VERSION "DNNBNNNYNNNNNNNNNNNNNNNNNNNNNNNNNNNNNNNNNN/4/%%%/4/'%**4NNN///"

NS_ :

BS_:

BU_: Vector__XXX Verdeck TSG_Fahrer TSG_Beifahrer Standheizung SMLS SitzMemo_Fahrer SitzMemo_Beifahrer Reifendruck_VW Reifendruck_Audi PTC_Heizung Multifunktions_SG Komfort_SG Gateway_K FHSG_hinten_rechts FHSG_hinten_links Einparkhilfe Clima BSG Anhaenger_SG

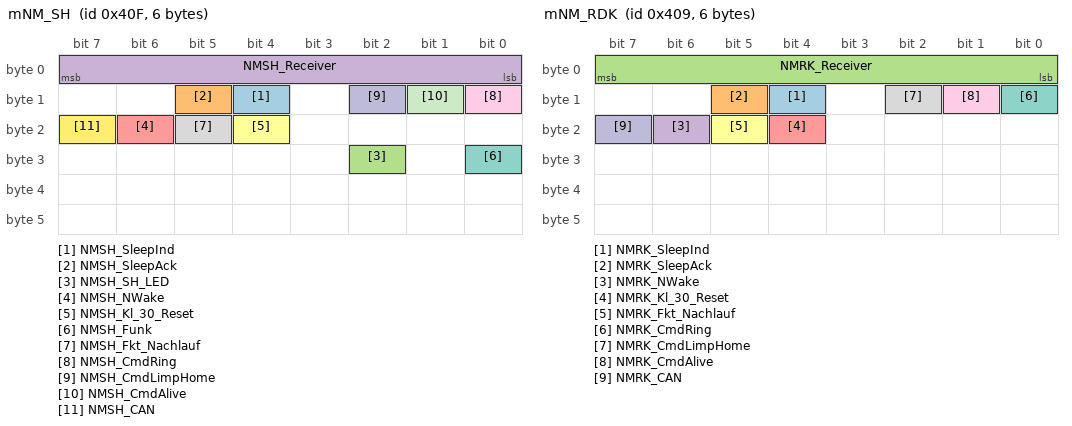
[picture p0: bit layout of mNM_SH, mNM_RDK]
BO_ 1039 mNM_SH: 6 Standheizung
 SG_ NMSH_SleepInd : 12|1@1+ (1,0) [0|0] ""  Reifendruck_VW,Reifendruck_Audi,Multifunktions_SG,SMLS,SitzMemo_Beifahrer,SitzMemo_Fahrer,Einparkhilfe,Verdeck,PTC_Heizung,Standheizung,Clima,Anhaenger_SG,BSG,FHSG_hinten_rechts,FHSG_hinten_links,TSG_Beifahrer,TSG_Fahrer,Komfort_SG,Gateway_K
 SG_ NMSH_SleepAck : 13|1@1+ (1,0) [0|0] ""  Reifendruck_VW,Reifendruck_Audi,Multifunktions_SG,SMLS,SitzMemo_Beifahrer,SitzMemo_Fahrer,Einparkhilfe,Verdeck,PTC_Heizung,Standheizung,Clima,Anhaenger_SG,BSG,FHSG_hinten_rechts,FHSG_hinten_links,TSG_Beifahrer,TSG_Fahrer,Komfort_SG,Gateway_K
 SG_ NMSH_SH_LED : 26|1@1+ (1,0) [0|0] ""  Standheizung
 SG_ NMSH_Receiver : 0|8@1+ (1,0) [0|0] ""  Reifendruck_VW,Reifendruck_Audi,Multifunktions_SG,SMLS,SitzMemo_Beifahrer,SitzMemo_Fahrer,Einparkhilfe,Verdeck,PTC_Heizung,Standheizung,Clima,Anhaenger_SG,BSG,FHSG_hinten_rechts,FHSG_hinten_links,TSG_Beifahrer,TSG_Fahrer,Komfort_SG,Gateway_K
 SG_ NMSH_NWake : 22|1@1+ (1,0) [0|0] ""  Standheizung
 SG_ NMSH_Kl_30_Reset : 20|1@1+ (1,0) [0|0] ""  Standheizung
 SG_ NMSH_Funk : 24|1@1+ (1,0) [0|0] ""  Standheizung
 SG_ NMSH_Fkt_Nachlauf : 21|1@1+ (1,0) [0|0] ""  Standheizung
 SG_ NMSH_CmdRing : 8|1@1+ (1,0) [0|0] ""  Reifendruck_VW,Reifendruck_Audi,Multifunktions_SG,SMLS,SitzMemo_Beifahrer,SitzMemo_Fahrer,Einparkhilfe,Verdeck,PTC_Heizung,Standheizung,Clima,Anhaenger_SG,BSG,FHSG_hinten_rechts,FHSG_hinten_links,TSG_Beifahrer,TSG_Fahrer,Komfort_SG,Gateway_K
 SG_ NMSH_CmdLimpHome : 10|1@1+ (1,0) [0|0] ""  Reifendruck_VW,Reifendruck_Audi,Multifunktions_SG,SMLS,SitzMemo_Beifahrer,SitzMemo_Fahrer,Einparkhilfe,Verdeck,PTC_Heizung,Standheizung,Clima,Anhaenger_SG,BSG,FHSG_hinten_rechts,FHSG_hinten_links,TSG_Beifahrer,TSG_Fahrer,Komfort_SG,Gateway_K
 SG_ NMSH_CmdAlive : 9|1@1+ (1,0) [0|0] ""  Reifendruck_VW,Reifendruck_Audi,Multifunktions_SG,SMLS,SitzMemo_Beifahrer,SitzMemo_Fahrer,Einparkhilfe,Verdeck,PTC_Heizung,Standheizung,Clima,Anhaenger_SG,BSG,FHSG_hinten_rechts,FHSG_hinten_links,TSG_Beifahrer,TSG_Fahrer,Komfort_SG,Gateway_K
 SG_ NMSH_CAN : 23|1@1+ (1,0) [0|0] ""  Standheizung

BO_ 1033 mNM_RDK: 6 Reifendruck_Audi
 SG_ NMRK_SleepInd : 12|1@1+ (1,0) [0|0] ""  Reifendruck_VW,Reifendruck_Audi,Multifunktions_SG,SMLS,SitzMemo_Beifahrer,SitzMemo_Fahrer,Einparkhilfe,Verdeck,PTC_Heizung,Standheizung,Clima,Anhaenger_SG,BSG,FHSG_hinten_rechts,FHSG_hinten_links,TSG_Beifahrer,TSG_Fahrer,Komfort_SG,Gateway_K
 SG_ NMRK_SleepAck : 13|1@1+ (1,0) [0|0] ""  Reifendruck_VW,Reifendruck_Audi,Multifunktions_SG,SMLS,SitzMemo_Beifahrer,SitzMemo_Fahrer,Einparkhilfe,Verdeck,PTC_Heizung,Standheizung,Clima,Anhaenger_SG,BSG,FHSG_hinten_rechts,FHSG_hinten_links,TSG_Beifahrer,TSG_Fahrer,Komfort_SG,Gateway_K
 SG_ NMRK_Receiver : 0|8@1+ (1,0) [0|0] ""  Reifendruck_VW,Reifendruck_Audi,Multifunktions_SG,SMLS,SitzMemo_Beifahrer,SitzMemo_Fahrer,Einparkhilfe,Verdeck,PTC_Heizung,Standheizung,Clima,Anhaenger_SG,BSG,FHSG_hinten_rechts,FHSG_hinten_links,TSG_Beifahrer,TSG_Fahrer,Komfort_SG,Gateway_K
 SG_ NMRK_NWake : 22|1@1+ (1,0) [0|0] ""  Reifendruck_VW,Reifendruck_Audi
 SG_ NMRK_Kl_30_Reset : 20|1@1+ (1,0) [0|0] ""  Reifendruck_VW,Reifendruck_Audi
 SG_ NMRK_Fkt_Nachlauf : 21|1@1+ (1,0) [0|0] ""  Reifendruck_VW,Reifendruck_Audi
 SG_ NMRK_CmdRing : 8|1@1+ (1,0) [0|0] ""  Reifendruck_VW,Reifendruck_Audi,Multifunktions_SG,SMLS,SitzMemo_Beifahrer,SitzMemo_Fahrer,Einparkhilfe,Verdeck,PTC_Heizung,Standheizung,Clima,Anhaenger_SG,BSG,FHSG_hinten_rechts,FHSG_hinten_links,TSG_Beifahrer,TSG_Fahrer,Komfort_SG,Gateway_K
 SG_ NMRK_CmdLimpHome : 10|1@1+ (1,0) [0|0] ""  Reifendruck_VW,Reifendruck_Audi,Multifunktions_SG,SMLS,SitzMemo_Beifahrer,SitzMemo_Fahrer,Einparkhilfe,Verdeck,PTC_Heizung,Standheizung,Clima,Anhaenger_SG,BSG,FHSG_hinten_rechts,FHSG_hinten_links,TSG_Beifahrer,TSG_Fahrer,Komfort_SG,Gateway_K
 SG_ NMRK_CmdAlive : 9|1@1+ (1,0) [0|0] ""  Reifendruck_VW,Reifendruck_Audi,Multifunktions_SG,SMLS,SitzMemo_Beifahrer,SitzMemo_Fahrer,Einparkhilfe,Verdeck,PTC_Heizung,Standheizung,Clima,Anhaenger_SG,BSG,FHSG_hinten_rechts,FHSG_hinten_links,TSG_Beifahrer,TSG_Fahrer,Komfort_SG,Gateway_K
 SG_ NMRK_CAN : 23|1@1+ (1,0) [0|0] ""  Reifendruck_VW,Reifendruck_Audi

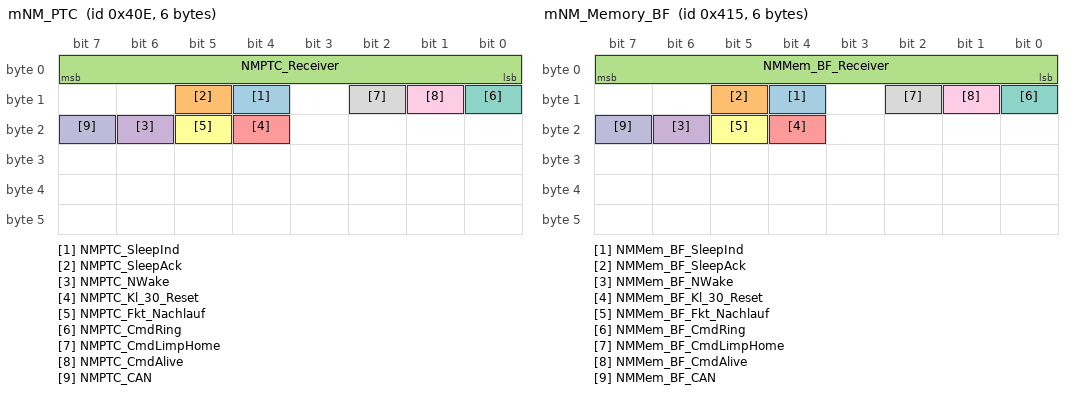
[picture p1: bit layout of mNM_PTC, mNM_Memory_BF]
BO_ 1038 mNM_PTC: 6 PTC_Heizung
 SG_ NMPTC_SleepInd : 12|1@1+ (1,0) [0|0] ""  Reifendruck_VW,Reifendruck_Audi,Multifunktions_SG,SMLS,SitzMemo_Beifahrer,SitzMemo_Fahrer,Einparkhilfe,Verdeck,PTC_Heizung,Standheizung,Clima,Anhaenger_SG,BSG,FHSG_hinten_rechts,FHSG_hinten_links,TSG_Beifahrer,TSG_Fahrer,Komfort_SG,Gateway_K
 SG_ NMPTC_SleepAck : 13|1@1+ (1,0) [0|0] ""  Reifendruck_VW,Reifendruck_Audi,Multifunktions_SG,SMLS,SitzMemo_Beifahrer,SitzMemo_Fahrer,Einparkhilfe,Verdeck,PTC_Heizung,Standheizung,Clima,Anhaenger_SG,BSG,FHSG_hinten_rechts,FHSG_hinten_links,TSG_Beifahrer,TSG_Fahrer,Komfort_SG,Gateway_K
 SG_ NMPTC_Receiver : 0|8@1+ (1,0) [0|0] ""  Reifendruck_VW,Reifendruck_Audi,Multifunktions_SG,SMLS,SitzMemo_Beifahrer,SitzMemo_Fahrer,Einparkhilfe,Verdeck,PTC_Heizung,Standheizung,Clima,Anhaenger_SG,BSG,FHSG_hinten_rechts,FHSG_hinten_links,TSG_Beifahrer,TSG_Fahrer,Komfort_SG,Gateway_K
 SG_ NMPTC_NWake : 22|1@1+ (1,0) [0|0] ""  Reifendruck_VW,Reifendruck_Audi,Gateway_K
 SG_ NMPTC_Kl_30_Reset : 20|1@1+ (1,0) [0|0] ""  Reifendruck_VW,Reifendruck_Audi,Gateway_K
 SG_ NMPTC_Fkt_Nachlauf : 21|1@1+ (1,0) [0|0] ""  Reifendruck_VW,Reifendruck_Audi,Gateway_K
 SG_ NMPTC_CmdRing : 8|1@1+ (1,0) [0|0] ""  Reifendruck_VW,Reifendruck_Audi,Multifunktions_SG,SMLS,SitzMemo_Beifahrer,SitzMemo_Fahrer,Einparkhilfe,Verdeck,PTC_Heizung,Standheizung,Clima,Anhaenger_SG,BSG,FHSG_hinten_rechts,FHSG_hinten_links,TSG_Beifahrer,TSG_Fahrer,Komfort_SG,Gateway_K
 SG_ NMPTC_CmdLimpHome : 10|1@1+ (1,0) [0|0] ""  Reifendruck_VW,Reifendruck_Audi,Multifunktions_SG,SMLS,SitzMemo_Beifahrer,SitzMemo_Fahrer,Einparkhilfe,Verdeck,PTC_Heizung,Standheizung,Clima,Anhaenger_SG,BSG,FHSG_hinten_rechts,FHSG_hinten_links,TSG_Beifahrer,TSG_Fahrer,Komfort_SG,Gateway_K
 SG_ NMPTC_CmdAlive : 9|1@1+ (1,0) [0|0] ""  Reifendruck_VW,Reifendruck_Audi,Multifunktions_SG,SMLS,SitzMemo_Beifahrer,SitzMemo_Fahrer,Einparkhilfe,Verdeck,PTC_Heizung,Standheizung,Clima,Anhaenger_SG,BSG,FHSG_hinten_rechts,FHSG_hinten_links,TSG_Beifahrer,TSG_Fahrer,Komfort_SG,Gateway_K
 SG_ NMPTC_CAN : 23|1@1+ (1,0) [0|0] ""  Reifendruck_VW,Reifendruck_Audi,Gateway_K

BO_ 1050 mNM_MFG: 6 Multifunktions_SG
 SG_ NMMFG_Warnblinker : 26|1@1+ (1,0) [0|0] ""  Multifunktions_SG
 SG_ NMMFG_Standlicht : 25|1@1+ (1,0) [0|0] ""  Multifunktions_SG
 SG_ NMMFG_SleepInd : 12|1@1+ (1,0) [0|0] ""  Reifendruck_VW,Reifendruck_Audi,Multifunktions_SG,SMLS,SitzMemo_Beifahrer,SitzMemo_Fahrer,Einparkhilfe,Verdeck,PTC_Heizung,Standheizung,Clima,Anhaenger_SG,BSG,FHSG_hinten_rechts,FHSG_hinten_links,TSG_Beifahrer,TSG_Fahrer,Komfort_SG,Gateway_K
 SG_ NMMFG_SleepAck : 13|1@1+ (1,0) [0|0] ""  Reifendruck_VW,Reifendruck_Audi,Multifunktions_SG,SMLS,SitzMemo_Beifahrer,SitzMemo_Fahrer,Einparkhilfe,Verdeck,PTC_Heizung,Standheizung,Clima,Anhaenger_SG,BSG,FHSG_hinten_rechts,FHSG_hinten_links,TSG_Beifahrer,TSG_Fahrer,Komfort_SG,Gateway_K
 SG_ NMMFG_Receiver : 0|8@1+ (1,0) [0|0] ""  Reifendruck_VW,Reifendruck_Audi,Multifunktions_SG,SMLS,SitzMemo_Beifahrer,SitzMemo_Fahrer,Einparkhilfe,Verdeck,PTC_Heizung,Standheizung,Clima,Anhaenger_SG,BSG,FHSG_hinten_rechts,FHSG_hinten_links,TSG_Beifahrer,TSG_Fahrer,Komfort_SG,Gateway_K
 SG_ NMMFG_re_Parklicht : 31|1@1+ (1,0) [0|0] ""  Multifunktions_SG
 SG_ NMMFG_NWake : 22|1@1+ (1,0) [0|0] ""  Multifunktions_SG
 SG_ NMMFG_Lichthupe : 29|1@1+ (1,0) [0|0] ""  Multifunktions_SG
 SG_ NMMFG_li_Parklicht : 30|1@1+ (1,0) [0|0] ""  Multifunktions_SG
 SG_ NMMFG_Kl_30_Reset : 20|1@1+ (1,0) [0|0] ""  Multifunktions_SG
 SG_ NMMFG_Fkt_Nachlauf : 21|1@1+ (1,0) [0|0] ""  Multifunktions_SG
 SG_ NMMFG_Fernbedienung : 24|1@1+ (1,0) [0|0] ""  Multifunktions_SG
 SG_ NMMFG_Fanfare : 32|1@1+ (1,0) [0|0] ""  Multifunktions_SG
 SG_ NMMFG_CmdRing : 8|1@1+ (1,0) [0|0] ""  Reifendruck_VW,Reifendruck_Audi,Multifunktions_SG,SMLS,SitzMemo_Beifahrer,SitzMemo_Fahrer,Einparkhilfe,Verdeck,PTC_Heizung,Standheizung,Clima,Anhaenger_SG,BSG,FHSG_hinten_rechts,FHSG_hinten_links,TSG_Beifahrer,TSG_Fahrer,Komfort_SG,Gateway_K
 SG_ NMMFG_CmdLimpHome : 10|1@1+ (1,0) [0|0] ""  Reifendruck_VW,Reifendruck_Audi,Multifunktions_SG,SMLS,SitzMemo_Beifahrer,SitzMemo_Fahrer,Einparkhilfe,Verdeck,PTC_Heizung,Standheizung,Clima,Anhaenger_SG,BSG,FHSG_hinten_rechts,FHSG_hinten_links,TSG_Beifahrer,TSG_Fahrer,Komfort_SG,Gateway_K
 SG_ NMMFG_CmdAlive : 9|1@1+ (1,0) [0|0] ""  Reifendruck_VW,Reifendruck_Audi,Multifunktions_SG,SMLS,SitzMemo_Beifahrer,SitzMemo_Fahrer,Einparkhilfe,Verdeck,PTC_Heizung,Standheizung,Clima,Anhaenger_SG,BSG,FHSG_hinten_rechts,FHSG_hinten_links,TSG_Beifahrer,TSG_Fahrer,Komfort_SG,Gateway_K
 SG_ NMMFG_CAN : 23|1@1+ (1,0) [0|0] ""  Multifunktions_SG
 SG_ NMMFG_Blinkalarm : 33|1@1+ (1,0) [0|0] ""  Multifunktions_SG
 SG_ NMMFG_Bel_Innenraum : 28|1@1+ (1,0) [0|0] ""  Multifunktions_SG
 SG_ NMMFG_Bel_Fussraum : 27|1@1+ (1,0) [0|0] ""  Multifunktions_SG

BO_ 1045 mNM_Memory_BF: 6 SitzMemo_Beifahrer
 SG_ NMMem_BF_SleepInd : 12|1@1+ (1,0) [0|0] ""  Reifendruck_VW,Reifendruck_Audi,Multifunktions_SG,SMLS,SitzMemo_Beifahrer,SitzMemo_Fahrer,Einparkhilfe,Verdeck,PTC_Heizung,Standheizung,Clima,Anhaenger_SG,BSG,FHSG_hinten_rechts,FHSG_hinten_links,TSG_Beifahrer,TSG_Fahrer,Komfort_SG,Gateway_K
 SG_ NMMem_BF_SleepAck : 13|1@1+ (1,0) [0|0] ""  Reifendruck_VW,Reifendruck_Audi,Multifunktions_SG,SMLS,SitzMemo_Beifahrer,SitzMemo_Fahrer,Einparkhilfe,Verdeck,PTC_Heizung,Standheizung,Clima,Anhaenger_SG,BSG,FHSG_hinten_rechts,FHSG_hinten_links,TSG_Beifahrer,TSG_Fahrer,Komfort_SG,Gateway_K
 SG_ NMMem_BF_Receiver : 0|8@1+ (1,0) [0|0] ""  Reifendruck_VW,Reifendruck_Audi,Multifunktions_SG,SMLS,SitzMemo_Beifahrer,SitzMemo_Fahrer,Einparkhilfe,Verdeck,PTC_Heizung,Standheizung,Clima,Anhaenger_SG,BSG,FHSG_hinten_rechts,FHSG_hinten_links,TSG_Beifahrer,TSG_Fahrer,Komfort_SG,Gateway_K
 SG_ NMMem_BF_NWake : 22|1@1+ (1,0) [0|0] ""  SitzMemo_Beifahrer
 SG_ NMMem_BF_Kl_30_Reset : 20|1@1+ (1,0) [0|0] ""  SitzMemo_Beifahrer
 SG_ NMMem_BF_Fkt_Nachlauf : 21|1@1+ (1,0) [0|0] ""  SitzMemo_Beifahrer
 SG_ NMMem_BF_CmdRing : 8|1@1+ (1,0) [0|0] ""  Reifendruck_VW,Reifendruck_Audi,Multifunktions_SG,SMLS,SitzMemo_Beifahrer,SitzMemo_Fahrer,Einparkhilfe,Verdeck,PTC_Heizung,Standheizung,Clima,Anhaenger_SG,BSG,FHSG_hinten_rechts,FHSG_hinten_links,TSG_Beifahrer,TSG_Fahrer,Komfort_SG,Gateway_K
 SG_ NMMem_BF_CmdLimpHome : 10|1@1+ (1,0) [0|0] ""  Reifendruck_VW,Reifendruck_Audi,Multifunktions_SG,SMLS,SitzMemo_Beifahrer,SitzMemo_Fahrer,Einparkhilfe,Verdeck,PTC_Heizung,Standheizung,Clima,Anhaenger_SG,BSG,FHSG_hinten_rechts,FHSG_hinten_links,TSG_Beifahrer,TSG_Fahrer,Komfort_SG,Gateway_K
 SG_ NMMem_BF_CmdAlive : 9|1@1+ (1,0) [0|0] ""  Reifendruck_VW,Reifendruck_Audi,Multifunktions_SG,SMLS,SitzMemo_Beifahrer,SitzMemo_Fahrer,Einparkhilfe,Verdeck,PTC_Heizung,Standheizung,Clima,Anhaenger_SG,BSG,FHSG_hinten_rechts,FHSG_hinten_links,TSG_Beifahrer,TSG_Fahrer,Komfort_SG,Gateway_K
 SG_ NMMem_BF_CAN : 23|1@1+ (1,0) [0|0] ""  SitzMemo_Beifahrer

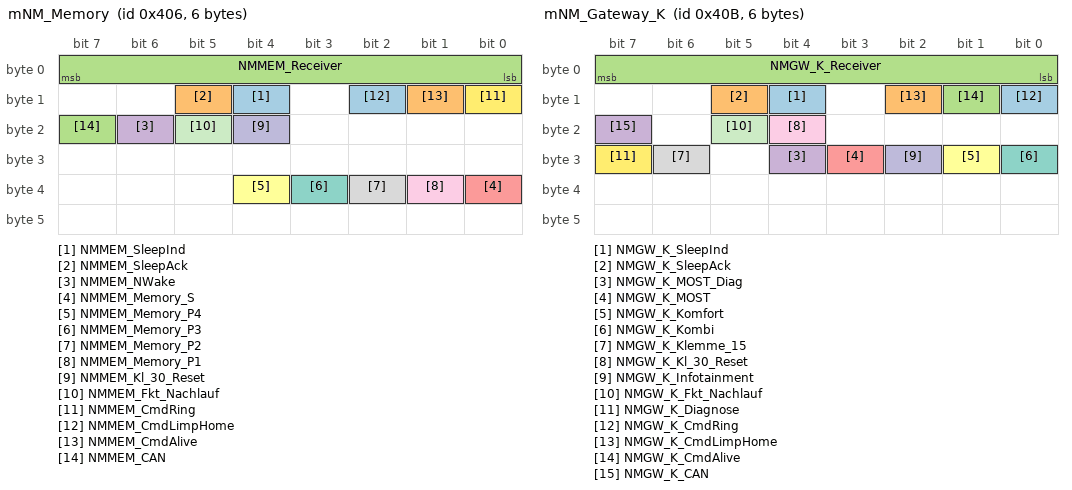
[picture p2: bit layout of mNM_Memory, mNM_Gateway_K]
BO_ 1030 mNM_Memory: 6 SitzMemo_Fahrer
 SG_ NMMEM_SleepInd : 12|1@1+ (1,0) [0|0] ""  Reifendruck_VW,Reifendruck_Audi,Multifunktions_SG,SMLS,SitzMemo_Beifahrer,SitzMemo_Fahrer,Einparkhilfe,Verdeck,PTC_Heizung,Standheizung,Clima,Anhaenger_SG,BSG,FHSG_hinten_rechts,FHSG_hinten_links,TSG_Beifahrer,TSG_Fahrer,Komfort_SG,Gateway_K
 SG_ NMMEM_SleepAck : 13|1@1+ (1,0) [0|0] ""  Reifendruck_VW,Reifendruck_Audi,Multifunktions_SG,SMLS,SitzMemo_Beifahrer,SitzMemo_Fahrer,Einparkhilfe,Verdeck,PTC_Heizung,Standheizung,Clima,Anhaenger_SG,BSG,FHSG_hinten_rechts,FHSG_hinten_links,TSG_Beifahrer,TSG_Fahrer,Komfort_SG,Gateway_K
 SG_ NMMEM_Receiver : 0|8@1+ (1,0) [0|0] ""  Reifendruck_VW,Reifendruck_Audi,Multifunktions_SG,SMLS,SitzMemo_Beifahrer,SitzMemo_Fahrer,Einparkhilfe,Verdeck,PTC_Heizung,Standheizung,Clima,Anhaenger_SG,BSG,FHSG_hinten_rechts,FHSG_hinten_links,TSG_Beifahrer,TSG_Fahrer,Komfort_SG,Gateway_K
 SG_ NMMEM_NWake : 22|1@1+ (1,0) [0|0] ""  SitzMemo_Fahrer
 SG_ NMMEM_Memory_S : 32|1@1+ (1,0) [0|0] ""  SitzMemo_Fahrer
 SG_ NMMEM_Memory_P4 : 36|1@1+ (1,0) [0|0] ""  SitzMemo_Fahrer
 SG_ NMMEM_Memory_P3 : 35|1@1+ (1,0) [0|0] ""  SitzMemo_Fahrer
 SG_ NMMEM_Memory_P2 : 34|1@1+ (1,0) [0|0] ""  SitzMemo_Fahrer
 SG_ NMMEM_Memory_P1 : 33|1@1+ (1,0) [0|0] ""  SitzMemo_Fahrer
 SG_ NMMEM_Kl_30_Reset : 20|1@1+ (1,0) [0|0] ""  SitzMemo_Fahrer
 SG_ NMMEM_Fkt_Nachlauf : 21|1@1+ (1,0) [0|0] ""  SitzMemo_Fahrer
 SG_ NMMEM_CmdRing : 8|1@1+ (1,0) [0|0] ""  Reifendruck_VW,Reifendruck_Audi,Multifunktions_SG,SMLS,SitzMemo_Beifahrer,SitzMemo_Fahrer,Einparkhilfe,Verdeck,PTC_Heizung,Standheizung,Clima,Anhaenger_SG,BSG,FHSG_hinten_rechts,FHSG_hinten_links,TSG_Beifahrer,TSG_Fahrer,Komfort_SG,Gateway_K
 SG_ NMMEM_CmdLimpHome : 10|1@1+ (1,0) [0|0] ""  Reifendruck_VW,Reifendruck_Audi,Multifunktions_SG,SMLS,SitzMemo_Beifahrer,SitzMemo_Fahrer,Einparkhilfe,Verdeck,PTC_Heizung,Standheizung,Clima,Anhaenger_SG,BSG,FHSG_hinten_rechts,FHSG_hinten_links,TSG_Beifahrer,TSG_Fahrer,Komfort_SG,Gateway_K
 SG_ NMMEM_CmdAlive : 9|1@1+ (1,0) [0|0] ""  Reifendruck_VW,Reifendruck_Audi,Multifunktions_SG,SMLS,SitzMemo_Beifahrer,SitzMemo_Fahrer,Einparkhilfe,Verdeck,PTC_Heizung,Standheizung,Clima,Anhaenger_SG,BSG,FHSG_hinten_rechts,FHSG_hinten_links,TSG_Beifahrer,TSG_Fahrer,Komfort_SG,Gateway_K
 SG_ NMMEM_CAN : 23|1@1+ (1,0) [0|0] ""  SitzMemo_Fahrer

BO_ 1035 mNM_Gateway_K: 6 Gateway_K
 SG_ NMGW_K_SleepInd : 12|1@1+ (1,0) [0|0] ""  Reifendruck_VW,Reifendruck_Audi,Multifunktions_SG,SMLS,SitzMemo_Beifahrer,SitzMemo_Fahrer,Einparkhilfe,Verdeck,PTC_Heizung,Standheizung,Clima,Anhaenger_SG,BSG,FHSG_hinten_rechts,FHSG_hinten_links,TSG_Beifahrer,TSG_Fahrer,Komfort_SG,Gateway_K
 SG_ NMGW_K_SleepAck : 13|1@1+ (1,0) [0|0] ""  Reifendruck_VW,Reifendruck_Audi,Multifunktions_SG,SMLS,SitzMemo_Beifahrer,SitzMemo_Fahrer,Einparkhilfe,Verdeck,PTC_Heizung,Standheizung,Clima,Anhaenger_SG,BSG,FHSG_hinten_rechts,FHSG_hinten_links,TSG_Beifahrer,TSG_Fahrer,Komfort_SG,Gateway_K
 SG_ NMGW_K_Receiver : 0|8@1+ (1,0) [0|0] ""  Reifendruck_VW,Reifendruck_Audi,Multifunktions_SG,SMLS,SitzMemo_Beifahrer,SitzMemo_Fahrer,Einparkhilfe,Verdeck,PTC_Heizung,Standheizung,Clima,Anhaenger_SG,BSG,FHSG_hinten_rechts,FHSG_hinten_links,TSG_Beifahrer,TSG_Fahrer,Komfort_SG,Gateway_K
 SG_ NMGW_K_MOST_Diag : 28|1@1+ (1,0) [0|0] ""  Gateway_K
 SG_ NMGW_K_MOST : 27|1@1+ (1,0) [0|0] ""  Gateway_K
 SG_ NMGW_K_Komfort : 25|1@1+ (1,0) [0|0] ""  Gateway_K
 SG_ NMGW_K_Kombi : 24|1@1+ (1,0) [0|0] ""  Gateway_K
 SG_ NMGW_K_Klemme_15 : 30|1@1+ (1,0) [0|0] ""  Gateway_K
 SG_ NMGW_K_Kl_30_Reset : 20|1@1+ (1,0) [0|0] ""  Gateway_K
 SG_ NMGW_K_Infotainment : 26|1@1+ (1,0) [0|0] ""  Gateway_K
 SG_ NMGW_K_Fkt_Nachlauf : 21|1@1+ (1,0) [0|0] ""  Gateway_K
 SG_ NMGW_K_Diagnose : 31|1@1+ (1,0) [0|0] ""  Gateway_K
 SG_ NMGW_K_CmdRing : 8|1@1+ (1,0) [0|0] ""  Reifendruck_VW,Reifendruck_Audi,Multifunktions_SG,SMLS,SitzMemo_Beifahrer,SitzMemo_Fahrer,Einparkhilfe,Verdeck,PTC_Heizung,Standheizung,Clima,Anhaenger_SG,BSG,FHSG_hinten_rechts,FHSG_hinten_links,TSG_Beifahrer,TSG_Fahrer,Komfort_SG,Gateway_K
 SG_ NMGW_K_CmdLimpHome : 10|1@1+ (1,0) [0|0] ""  Reifendruck_VW,Reifendruck_Audi,Multifunktions_SG,SMLS,SitzMemo_Beifahrer,SitzMemo_Fahrer,Einparkhilfe,Verdeck,PTC_Heizung,Standheizung,Clima,Anhaenger_SG,BSG,FHSG_hinten_rechts,FHSG_hinten_links,TSG_Beifahrer,TSG_Fahrer,Komfort_SG,Gateway_K
 SG_ NMGW_K_CmdAlive : 9|1@1+ (1,0) [0|0] ""  Reifendruck_VW,Reifendruck_Audi,Multifunktions_SG,SMLS,SitzMemo_Beifahrer,SitzMemo_Fahrer,Einparkhilfe,Verdeck,PTC_Heizung,Standheizung,Clima,Anhaenger_SG,BSG,FHSG_hinten_rechts,FHSG_hinten_links,TSG_Beifahrer,TSG_Fahrer,Komfort_SG,Gateway_K
 SG_ NMGW_K_CAN : 23|1@1+ (1,0) [0|0] ""  Gateway_K

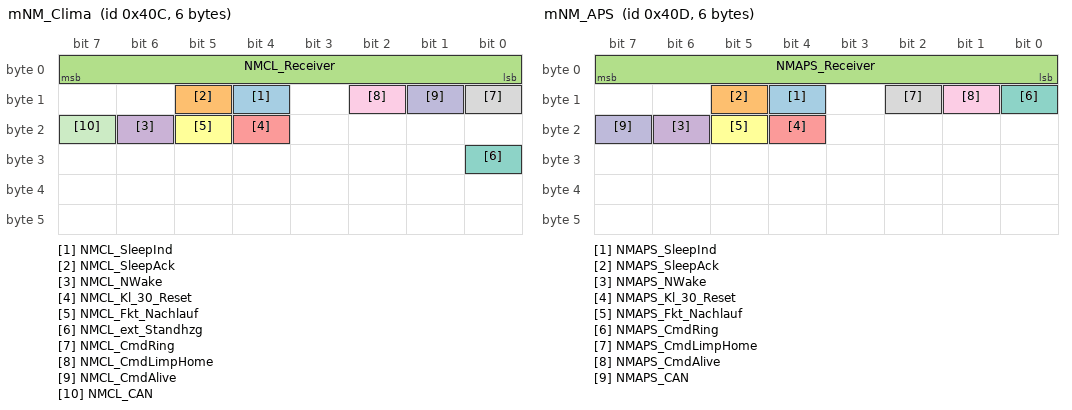
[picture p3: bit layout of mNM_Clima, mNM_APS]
BO_ 1036 mNM_Clima: 6 Clima
 SG_ NMCL_SleepInd : 12|1@1+ (1,0) [0|0] ""  Reifendruck_VW,Reifendruck_Audi,Multifunktions_SG,SMLS,SitzMemo_Beifahrer,SitzMemo_Fahrer,Einparkhilfe,Verdeck,PTC_Heizung,Standheizung,Clima,Anhaenger_SG,BSG,FHSG_hinten_rechts,FHSG_hinten_links,TSG_Beifahrer,TSG_Fahrer,Komfort_SG,Gateway_K
 SG_ NMCL_SleepAck : 13|1@1+ (1,0) [0|0] ""  Reifendruck_VW,Reifendruck_Audi,Multifunktions_SG,SMLS,SitzMemo_Beifahrer,SitzMemo_Fahrer,Einparkhilfe,Verdeck,PTC_Heizung,Standheizung,Clima,Anhaenger_SG,BSG,FHSG_hinten_rechts,FHSG_hinten_links,TSG_Beifahrer,TSG_Fahrer,Komfort_SG,Gateway_K
 SG_ NMCL_Receiver : 0|8@1+ (1,0) [0|0] ""  Reifendruck_VW,Reifendruck_Audi,Multifunktions_SG,SMLS,SitzMemo_Beifahrer,SitzMemo_Fahrer,Einparkhilfe,Verdeck,PTC_Heizung,Standheizung,Clima,Anhaenger_SG,BSG,FHSG_hinten_rechts,FHSG_hinten_links,TSG_Beifahrer,TSG_Fahrer,Komfort_SG,Gateway_K
 SG_ NMCL_NWake : 22|1@1+ (1,0) [0|0] ""  Clima
 SG_ NMCL_Kl_30_Reset : 20|1@1+ (1,0) [0|0] ""  Clima
 SG_ NMCL_Fkt_Nachlauf : 21|1@1+ (1,0) [0|0] ""  Clima
 SG_ NMCL_ext_Standhzg : 24|1@1+ (1,0) [0|0] ""  Clima
 SG_ NMCL_CmdRing : 8|1@1+ (1,0) [0|0] ""  Reifendruck_VW,Reifendruck_Audi,Multifunktions_SG,SMLS,SitzMemo_Beifahrer,SitzMemo_Fahrer,Einparkhilfe,Verdeck,PTC_Heizung,Standheizung,Clima,Anhaenger_SG,BSG,FHSG_hinten_rechts,FHSG_hinten_links,TSG_Beifahrer,TSG_Fahrer,Komfort_SG,Gateway_K
 SG_ NMCL_CmdLimpHome : 10|1@1+ (1,0) [0|0] ""  Reifendruck_VW,Reifendruck_Audi,Multifunktions_SG,SMLS,SitzMemo_Beifahrer,SitzMemo_Fahrer,Einparkhilfe,Verdeck,PTC_Heizung,Standheizung,Clima,Anhaenger_SG,BSG,FHSG_hinten_rechts,FHSG_hinten_links,TSG_Beifahrer,TSG_Fahrer,Komfort_SG,Gateway_K
 SG_ NMCL_CmdAlive : 9|1@1+ (1,0) [0|0] ""  Reifendruck_VW,Reifendruck_Audi,Multifunktions_SG,SMLS,SitzMemo_Beifahrer,SitzMemo_Fahrer,Einparkhilfe,Verdeck,PTC_Heizung,Standheizung,Clima,Anhaenger_SG,BSG,FHSG_hinten_rechts,FHSG_hinten_links,TSG_Beifahrer,TSG_Fahrer,Komfort_SG,Gateway_K
 SG_ NMCL_CAN : 23|1@1+ (1,0) [0|0] ""  Clima

BO_ 1024 mNM_BSG: 6 BSG
 SG_ NMBS_Warnblinker : 26|1@1+ (1,0) [0|0] ""  BSG
 SG_ NMBS_Standlicht : 28|1@1+ (1,0) [0|0] ""  BSG
 SG_ NMBS_SleepInd : 12|1@1+ (1,0) [0|0] ""  Reifendruck_VW,Reifendruck_Audi,Multifunktions_SG,SMLS,SitzMemo_Beifahrer,SitzMemo_Fahrer,Einparkhilfe,Verdeck,PTC_Heizung,Standheizung,Clima,Anhaenger_SG,BSG,FHSG_hinten_rechts,FHSG_hinten_links,TSG_Beifahrer,TSG_Fahrer,Komfort_SG,Gateway_K
 SG_ NMBS_SleepAck : 13|1@1+ (1,0) [0|0] ""  Reifendruck_VW,Reifendruck_Audi,Multifunktions_SG,SMLS,SitzMemo_Beifahrer,SitzMemo_Fahrer,Einparkhilfe,Verdeck,PTC_Heizung,Standheizung,Clima,Anhaenger_SG,BSG,FHSG_hinten_rechts,FHSG_hinten_links,TSG_Beifahrer,TSG_Fahrer,Komfort_SG,Gateway_K
 SG_ NMBS_Signalhorn : 27|1@1+ (1,0) [0|0] ""  BSG
 SG_ NMBS_Receiver : 0|8@1+ (1,0) [0|0] ""  Reifendruck_VW,Reifendruck_Audi,Multifunktions_SG,SMLS,SitzMemo_Beifahrer,SitzMemo_Fahrer,Einparkhilfe,Verdeck,PTC_Heizung,Standheizung,Clima,Anhaenger_SG,BSG,FHSG_hinten_rechts,FHSG_hinten_links,TSG_Beifahrer,TSG_Fahrer,Komfort_SG,Gateway_K
 SG_ NMBS_NWake : 22|1@1+ (1,0) [0|0] ""  BSG
 SG_ NMBS_MH_Kontakt : 38|1@1+ (1,0) [0|0] ""  BSG
 SG_ NMBS_Lastman : 45|1@1+ (1,0) [0|0] ""  BSG
 SG_ NMBS_Klemme15 : 25|1@1+ (1,0) [0|0] ""  BSG
 SG_ NMBS_Kl_30_Reset : 20|1@1+ (1,0) [0|0] ""  BSG
 SG_ NMBS_HR_Drehfalle : 35|1@1+ (1,0) [0|0] ""  BSG
 SG_ NMBS_Home_Fkt : 44|1@1+ (1,0) [0|0] ""  BSG
 SG_ NMBS_HL_Drehfalle : 34|1@1+ (1,0) [0|0] ""  BSG
 SG_ NMBS_HD_Vorraste : 36|1@1+ (1,0) [0|0] ""  BSG
 SG_ NMBS_HD_Innentaster : 40|1@1+ (1,0) [0|0] ""  BSG
 SG_ NMBS_HD_Hauptraste : 37|1@1+ (1,0) [0|0] ""  BSG
 SG_ NMBS_HD_Grifftaster : 41|1@1+ (1,0) [0|0] ""  BSG
 SG_ NMBS_FT_Drehfalle : 32|1@1+ (1,0) [0|0] ""  BSG
 SG_ NMBS_Fkt_Nachlauf : 21|1@1+ (1,0) [0|0] ""  BSG
 SG_ NMBS_Dimmsignal : 24|1@1+ (1,0) [0|0] ""  BSG
 SG_ NMBS_CmdRing : 8|1@1+ (1,0) [0|0] ""  Reifendruck_VW,Reifendruck_Audi,Multifunktions_SG,SMLS,SitzMemo_Beifahrer,SitzMemo_Fahrer,Einparkhilfe,Verdeck,PTC_Heizung,Standheizung,Clima,Anhaenger_SG,BSG,FHSG_hinten_rechts,FHSG_hinten_links,TSG_Beifahrer,TSG_Fahrer,Komfort_SG,Gateway_K
 SG_ NMBS_CmdLimpHome : 10|1@1+ (1,0) [0|0] ""  Reifendruck_VW,Reifendruck_Audi,Multifunktions_SG,SMLS,SitzMemo_Beifahrer,SitzMemo_Fahrer,Einparkhilfe,Verdeck,PTC_Heizung,Standheizung,Clima,Anhaenger_SG,BSG,FHSG_hinten_rechts,FHSG_hinten_links,TSG_Beifahrer,TSG_Fahrer,Komfort_SG,Gateway_K
 SG_ NMBS_CmdAlive : 9|1@1+ (1,0) [0|0] ""  Reifendruck_VW,Reifendruck_Audi,Multifunktions_SG,SMLS,SitzMemo_Beifahrer,SitzMemo_Fahrer,Einparkhilfe,Verdeck,PTC_Heizung,Standheizung,Clima,Anhaenger_SG,BSG,FHSG_hinten_rechts,FHSG_hinten_links,TSG_Beifahrer,TSG_Fahrer,Komfort_SG,Gateway_K
 SG_ NMBS_CAN : 23|1@1+ (1,0) [0|0] ""  BSG
 SG_ NMBS_BT_Drehfalle : 33|1@1+ (1,0) [0|0] ""  BSG
 SG_ NMBS_Bremslicht : 29|1@1+ (1,0) [0|0] ""  BSG

BO_ 1037 mNM_APS: 6 Einparkhilfe
 SG_ NMAPS_SleepInd : 12|1@1+ (1,0) [0|0] ""  Reifendruck_VW,Reifendruck_Audi,Multifunktions_SG,SMLS,SitzMemo_Beifahrer,SitzMemo_Fahrer,Einparkhilfe,Verdeck,PTC_Heizung,Standheizung,Clima,Anhaenger_SG,BSG,FHSG_hinten_rechts,FHSG_hinten_links,TSG_Beifahrer,TSG_Fahrer,Komfort_SG,Gateway_K
 SG_ NMAPS_SleepAck : 13|1@1+ (1,0) [0|0] ""  Reifendruck_VW,Reifendruck_Audi,Multifunktions_SG,SMLS,SitzMemo_Beifahrer,SitzMemo_Fahrer,Einparkhilfe,Verdeck,PTC_Heizung,Standheizung,Clima,Anhaenger_SG,BSG,FHSG_hinten_rechts,FHSG_hinten_links,TSG_Beifahrer,TSG_Fahrer,Komfort_SG,Gateway_K
 SG_ NMAPS_Receiver : 0|8@1+ (1,0) [0|0] ""  Reifendruck_VW,Reifendruck_Audi,Multifunktions_SG,SMLS,SitzMemo_Beifahrer,SitzMemo_Fahrer,Einparkhilfe,Verdeck,PTC_Heizung,Standheizung,Clima,Anhaenger_SG,BSG,FHSG_hinten_rechts,FHSG_hinten_links,TSG_Beifahrer,TSG_Fahrer,Komfort_SG,Gateway_K
 SG_ NMAPS_NWake : 22|1@1+ (1,0) [0|0] ""  Einparkhilfe
 SG_ NMAPS_Kl_30_Reset : 20|1@1+ (1,0) [0|0] ""  Einparkhilfe
 SG_ NMAPS_Fkt_Nachlauf : 21|1@1+ (1,0) [0|0] ""  Einparkhilfe
 SG_ NMAPS_CmdRing : 8|1@1+ (1,0) [0|0] ""  Reifendruck_VW,Reifendruck_Audi,Multifunktions_SG,SMLS,SitzMemo_Beifahrer,SitzMemo_Fahrer,Einparkhilfe,Verdeck,PTC_Heizung,Standheizung,Clima,Anhaenger_SG,BSG,FHSG_hinten_rechts,FHSG_hinten_links,TSG_Beifahrer,TSG_Fahrer,Komfort_SG,Gateway_K
 SG_ NMAPS_CmdLimpHome : 10|1@1+ (1,0) [0|0] ""  Reifendruck_VW,Reifendruck_Audi,Multifunktions_SG,SMLS,SitzMemo_Beifahrer,SitzMemo_Fahrer,Einparkhilfe,Verdeck,PTC_Heizung,Standheizung,Clima,Anhaenger_SG,BSG,FHSG_hinten_rechts,FHSG_hinten_links,TSG_Beifahrer,TSG_Fahrer,Komfort_SG,Gateway_K
 SG_ NMAPS_CmdAlive : 9|1@1+ (1,0) [0|0] ""  Reifendruck_VW,Reifendruck_Audi,Multifunktions_SG,SMLS,SitzMemo_Beifahrer,SitzMemo_Fahrer,Einparkhilfe,Verdeck,PTC_Heizung,Standheizung,Clima,Anhaenger_SG,BSG,FHSG_hinten_rechts,FHSG_hinten_links,TSG_Beifahrer,TSG_Fahrer,Komfort_SG,Gateway_K
 SG_ NMAPS_CAN : 23|1@1+ (1,0) [0|0] ""  Einparkhilfe

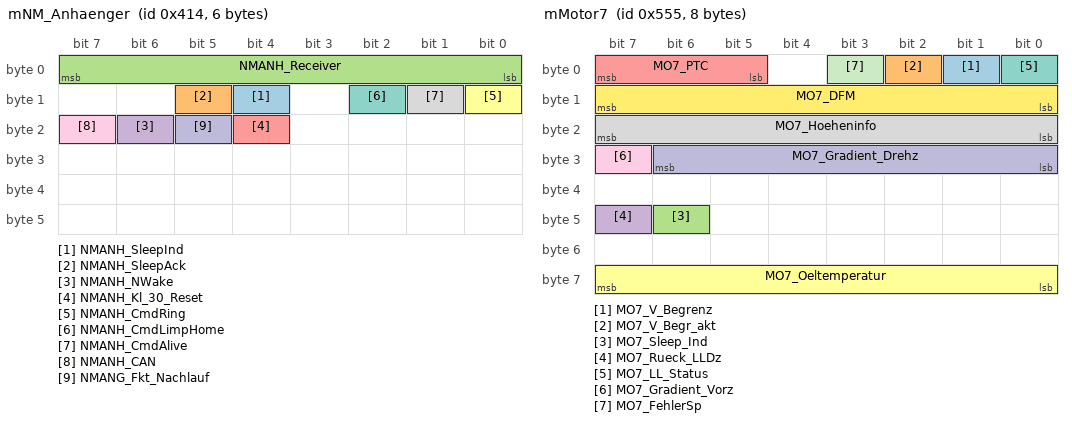
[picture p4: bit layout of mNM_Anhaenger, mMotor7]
BO_ 1044 mNM_Anhaenger: 6 Anhaenger_SG
 SG_ NMANH_SleepInd : 12|1@1+ (1,0) [0|0] ""  Reifendruck_VW,Reifendruck_Audi,Multifunktions_SG,SMLS,SitzMemo_Beifahrer,SitzMemo_Fahrer,Einparkhilfe,Verdeck,PTC_Heizung,Standheizung,Clima,Anhaenger_SG,BSG,FHSG_hinten_rechts,FHSG_hinten_links,TSG_Beifahrer,TSG_Fahrer,Komfort_SG,Gateway_K
 SG_ NMANH_SleepAck : 13|1@1+ (1,0) [0|0] ""  Reifendruck_VW,Reifendruck_Audi,Multifunktions_SG,SMLS,SitzMemo_Beifahrer,SitzMemo_Fahrer,Einparkhilfe,Verdeck,PTC_Heizung,Standheizung,Clima,Anhaenger_SG,BSG,FHSG_hinten_rechts,FHSG_hinten_links,TSG_Beifahrer,TSG_Fahrer,Komfort_SG,Gateway_K
 SG_ NMANH_Receiver : 0|8@1+ (1,0) [0|0] ""  Reifendruck_VW,Reifendruck_Audi,Multifunktions_SG,SMLS,SitzMemo_Beifahrer,SitzMemo_Fahrer,Einparkhilfe,Verdeck,PTC_Heizung,Standheizung,Clima,Anhaenger_SG,BSG,FHSG_hinten_rechts,FHSG_hinten_links,TSG_Beifahrer,TSG_Fahrer,Komfort_SG,Gateway_K
 SG_ NMANH_NWake : 22|1@1+ (1,0) [0|0] ""  Anhaenger_SG
 SG_ NMANH_Kl_30_Reset : 20|1@1+ (1,0) [0|0] ""  Anhaenger_SG
 SG_ NMANH_CmdRing : 8|1@1+ (1,0) [0|0] ""  Reifendruck_VW,Reifendruck_Audi,Multifunktions_SG,SMLS,SitzMemo_Beifahrer,SitzMemo_Fahrer,Einparkhilfe,Verdeck,PTC_Heizung,Standheizung,Clima,Anhaenger_SG,BSG,FHSG_hinten_rechts,FHSG_hinten_links,TSG_Beifahrer,TSG_Fahrer,Komfort_SG,Gateway_K
 SG_ NMANH_CmdLimpHome : 10|1@1+ (1,0) [0|0] ""  Reifendruck_VW,Reifendruck_Audi,Multifunktions_SG,SMLS,SitzMemo_Beifahrer,SitzMemo_Fahrer,Einparkhilfe,Verdeck,PTC_Heizung,Standheizung,Clima,Anhaenger_SG,BSG,FHSG_hinten_rechts,FHSG_hinten_links,TSG_Beifahrer,TSG_Fahrer,Komfort_SG,Gateway_K
 SG_ NMANH_CmdAlive : 9|1@1+ (1,0) [0|0] ""  Reifendruck_VW,Reifendruck_Audi,Multifunktions_SG,SMLS,SitzMemo_Beifahrer,SitzMemo_Fahrer,Einparkhilfe,Verdeck,PTC_Heizung,Standheizung,Clima,Anhaenger_SG,BSG,FHSG_hinten_rechts,FHSG_hinten_links,TSG_Beifahrer,TSG_Fahrer,Komfort_SG,Gateway_K
 SG_ NMANH_CAN : 23|1@1+ (1,0) [0|0] ""  Anhaenger_SG
 SG_ NMANG_Fkt_Nachlauf : 21|1@1+ (1,0) [0|0] ""  Anhaenger_SG

BO_ 1365 mMotor7: 8 Gateway_K
 SG_ MO7_V_Begrenz : 1|1@1+ (1,0) [0|1] "" Vector__XXX
 SG_ MO7_V_Begr_akt : 2|1@1+ (1,0) [0|1] "" Vector__XXX
 SG_ MO7_Sleep_Ind : 46|1@1+ (1,0) [0|1] "" Vector__XXX
 SG_ MO7_Rueck_LLDz : 47|1@1+ (1,0) [0|1] "" Vector__XXX
 SG_ MO7_PTC : 5|3@1+ (1,0) [0|7] "Tabelle"  BSG
 SG_ MO7_Oeltemperatur : 56|8@1+ (1,-60) [-60|194] "°C" Vector__XXX
 SG_ MO7_LL_Status : 0|1@1+ (1,0) [0|1] ""  BSG
 SG_ MO7_Hoeheninfo : 16|8@1+ (0.0078125,0) [0|2] ""  Standheizung
 SG_ MO7_Gradient_Vorz : 31|1@1+ (1,0) [0|1] "" Vector__XXX
 SG_ MO7_Gradient_Drehz : 24|7@1+ (1,0) [0|126] "1/min" Vector__XXX
 SG_ MO7_FehlerSp : 3|1@1+ (1,0) [0|1] "" Vector__XXX
 SG_ MO7_DFM : 8|8@1+ (0.4,0) [0|101.6] "%"  PTC_Heizung,BSG

BO_ 1473 mMFL_Tasten: 2 SMLS
 SG_ MLT_Symbol : 0|8@1+ (1,0) [0|255] ""  Reifendruck_VW,Standheizung,BSG,Komfort_SG,Gateway_K
 SG_ MLT_DW_VZ : 15|1@1+ (1,0) [0|1] ""  Reifendruck_VW,Standheizung,BSG,Komfort_SG,Gateway_K
 SG_ MLT_DW_Ticks : 8|7@1+ (1,0) [0|127] "Tick"  Reifendruck_VW,Standheizung,BSG,Komfort_SG,Gateway_K

BO_ 1475 mMFL_Cmd: 3 SMLS
 SG_ ML1_Ziel : 0|8@1+ (1,0) [0|255] ""  Gateway_K
 SG_ ML1_DW_VZ : 23|1@1+ (1,0) [0|1] ""  Gateway_K
 SG_ ML1_DW_Ticks : 16|7@1+ (1,0) [0|127] "Tick"  Gateway_K
 SG_ ML1_Befehl : 8|8@1+ (1,0) [0|255] ""  Gateway_K

BO_ 889 mMFG_1: 8 Multifunktions_SG
 SG_ MG1_Zaehler : 52|4@1+ (1,0) [0|15] "Tabelle"  SMLS,BSG
 SG_ MG1_WischenStufe_2 : 27|1@1+ (1,0) [0|1] ""  SMLS
 SG_ MG1_WischenStufe_1 : 26|1@1+ (1,0) [0|1] ""  SMLS
 SG_ MG1_Warnblinker : 11|1@1+ (1,0) [0|1] ""  BSG
 SG_ MG1_Typ3 : 3|1@1+ (1,0) [0|1] ""  SMLS,BSG,TSG_Fahrer,Gateway_K
 SG_ MG1_Typ2 : 2|1@1+ (1,0) [0|1] ""  SMLS,BSG,Gateway_K
 SG_ MG1_Typ1 : 1|1@1+ (1,0) [0|1] ""  SMLS,BSG,Gateway_K
 SG_ MG1_Typ0 : 0|1@1+ (1,0) [0|1] ""  SMLS,BSG,Gateway_K
 SG_ MG1_Tipwischen : 24|1@1+ (1,0) [0|1] ""  SMLS
 SG_ MG1_Summer : 32|1@1+ (1,0) [0|1] ""  Gateway_K
 SG_ MG1_Standlicht : 8|1@1+ (1,0) [0|1] ""  BSG
 SG_ MG1_Signalhorn : 39|1@1+ (1,0) [0|1] ""  SMLS
 SG_ MG1_Parklicht_rechts : 22|1@1+ (1,0) [0|1] ""  SMLS
 SG_ MG1_Parklicht_links : 21|1@1+ (1,0) [0|1] ""  SMLS
 SG_ MG1_Motorweiterlauf : 48|1@1+ (1,0) [0|1] ""  SMLS
 SG_ MG1_Lichthupe : 18|1@1+ (1,0) [0|1] ""  SMLS
 SG_ MG1_KD_Fehler : 7|1@1+ (1,0) [0|1] ""  Gateway_K
 SG_ MG1_Interm_Fernlicht : 10|1@1+ (1,0) [0|1] ""  BSG
 SG_ MG1_Innenraumbel : 13|1@1+ (1,0) [0|1] ""  BSG
 SG_ MG1_Heckwaschen : 31|1@1+ (1,0) [0|1] ""  SMLS
 SG_ MG1_Heckintervall : 30|1@1+ (1,0) [0|1] ""  SMLS
 SG_ MG1_Fussraumbel : 12|1@1+ (1,0) [0|1] ""  BSG
 SG_ MG1_Frontwaschen : 28|1@1+ (1,0) [0|1] ""  SMLS
 SG_ MG1_Frontintervall : 25|1@1+ (1,0) [0|1] ""  SMLS
 SG_ MG1_FH_FT_Tief : 41|1@1+ (1,0) [0|1] ""  TSG_Fahrer
 SG_ MG1_FH_FT_Hoch : 40|1@1+ (1,0) [0|1] ""  TSG_Fahrer
 SG_ MG1_FH_BT_Tief : 43|1@1+ (1,0) [0|1] ""  TSG_Fahrer
 SG_ MG1_FH_BT_Hoch : 42|1@1+ (1,0) [0|1] ""  TSG_Fahrer
 SG_ MG1_Fernlicht : 19|1@1+ (1,0) [0|1] ""  SMLS
 SG_ MG1_Fernbedienung : 6|1@1+ (1,0) [0|1] ""  SMLS
 SG_ MG1_Fahrlicht : 9|1@1+ (1,0) [0|1] ""  BSG
 SG_ MG1_Checksumme : 56|8@1+ (1,0) [0|255] "Tabelle"  SMLS,BSG
 SG_ MG1_Blk_rechts : 17|1@1+ (1,0) [0|1] ""  SMLS
 SG_ MG1_Blk_links : 16|1@1+ (1,0) [0|1] ""  SMLS
 SG_ MG1_Anlasssperre : 50|1@1+ (1,0) [0|1] ""  BSG
 SG_ MG1_Anlasser : 49|1@1+ (1,0) [0|1] ""  SMLS
 SG_ MG1_Alarm_Fanfare : 33|1@1+ (1,0) [0|1] ""  BSG
 SG_ MG1_Alarm_Blinker : 34|1@1+ (1,0) [0|1] ""  BSG

BO_ 1317 mMenue_3: 2 Gateway_K
 SG_ SHM_SL : 2|1@1+ (1,0) [0|1] ""  Standheizung,Clima
 SG_ SHM_SH_SL : 0|1@1+ (1,0) [0|1] ""  Standheizung,Clima
 SG_ SHM_SH : 1|1@1+ (1,0) [0|1] ""  Standheizung
 SG_ SHM_Restdauer : 8|7@1+ (1,0) [0|126] "min"  Standheizung,Clima
 SG_ SHM_MVW : 3|1@1+ (1,0) [0|1] ""  Standheizung

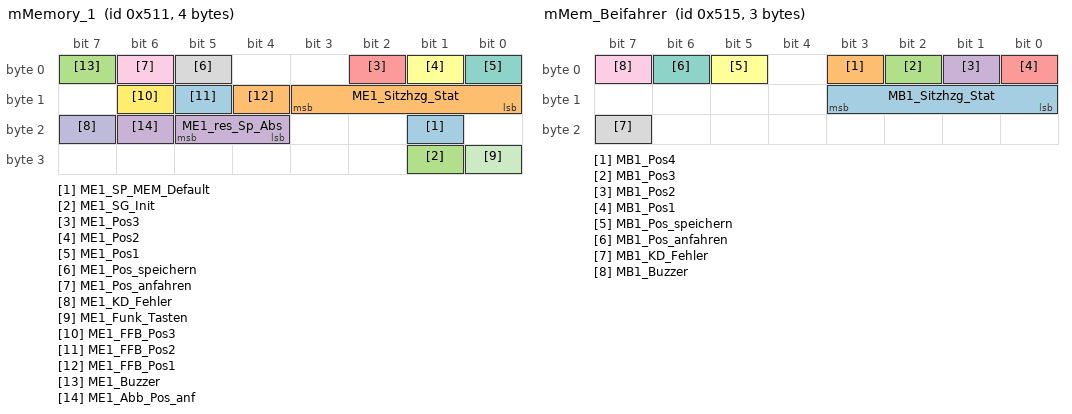
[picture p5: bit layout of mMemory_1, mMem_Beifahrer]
BO_ 1297 mMemory_1: 4 SitzMemo_Fahrer
 SG_ ME1_SP_MEM_Default : 17|1@1+ (1,0) [0|1] ""  TSG_Beifahrer,TSG_Fahrer
 SG_ ME1_Sitzhzg_Stat : 8|4@1+ (10,0) [0|100] "%"  BSG
 SG_ ME1_SG_Init : 25|1@1+ (1,0) [0|1] ""  TSG_Beifahrer,TSG_Fahrer
 SG_ ME1_res_Sp_Abs : 20|2@1+ (1,0) [0|3] ""  TSG_Beifahrer,TSG_Fahrer
 SG_ ME1_Pos3 : 2|1@1+ (1,0) [0|1] ""  TSG_Beifahrer,TSG_Fahrer
 SG_ ME1_Pos2 : 1|1@1+ (1,0) [0|1] ""  TSG_Beifahrer,TSG_Fahrer
 SG_ ME1_Pos1 : 0|1@1+ (1,0) [0|1] ""  TSG_Beifahrer,TSG_Fahrer
 SG_ ME1_Pos_speichern : 5|1@1+ (1,0) [0|1] ""  TSG_Beifahrer,TSG_Fahrer
 SG_ ME1_Pos_anfahren : 6|1@1+ (1,0) [0|1] ""  TSG_Beifahrer,TSG_Fahrer
 SG_ ME1_KD_Fehler : 23|1@1+ (1,0) [0|1] ""  Gateway_K
 SG_ ME1_Funk_Tasten : 24|1@1+ (1,0) [0|1] ""  TSG_Beifahrer,TSG_Fahrer
 SG_ ME1_FFB_Pos3 : 14|1@1+ (1,0) [0|1] "" Vector__XXX
 SG_ ME1_FFB_Pos2 : 13|1@1+ (1,0) [0|1] "" Vector__XXX
 SG_ ME1_FFB_Pos1 : 12|1@1+ (1,0) [0|1] "" Vector__XXX
 SG_ ME1_Buzzer : 7|1@1+ (1,0) [0|1] ""  Gateway_K
 SG_ ME1_Abb_Pos_anf : 22|1@1+ (1,0) [0|1] ""  TSG_Beifahrer,TSG_Fahrer

BO_ 1301 mMem_Beifahrer: 3 SitzMemo_Beifahrer
 SG_ MB1_Sitzhzg_Stat : 8|4@1+ (10,0) [0|100] "%"  BSG
 SG_ MB1_Pos4 : 3|1@1+ (1,0) [0|1] "" Vector__XXX
 SG_ MB1_Pos3 : 2|1@1+ (1,0) [0|1] "" Vector__XXX
 SG_ MB1_Pos2 : 1|1@1+ (1,0) [0|1] "" Vector__XXX
 SG_ MB1_Pos1 : 0|1@1+ (1,0) [0|1] "" Vector__XXX
 SG_ MB1_Pos_speichern : 5|1@1+ (1,0) [0|1] "" Vector__XXX
 SG_ MB1_Pos_anfahren : 6|1@1+ (1,0) [0|1] "" Vector__XXX
 SG_ MB1_KD_Fehler : 23|1@1+ (1,0) [0|1] ""  Gateway_K
 SG_ MB1_Buzzer : 7|1@1+ (1,0) [0|1] ""  Gateway_K

BO_ 705 mLSM_1: 5 SMLS
 SG_ LS1_WischenStufe_2 : 11|1@1+ (1,0) [0|1] ""  Multifunktions_SG,Clima,BSG,Gateway_K
 SG_ LS1_WischenStufe_1 : 10|1@1+ (1,0) [0|1] ""  Multifunktions_SG,Clima,BSG,Gateway_K
 SG_ LS1_Winterstellung : 32|1@1+ (1,0) [0|1] ""  BSG,Gateway_K
 SG_ LS1_Tipwischen : 8|1@1+ (1,0) [0|1] ""  Clima,BSG,Gateway_K
 SG_ LS1_Signalhorn : 7|1@1+ (1,0) [0|1] ""  Multifunktions_SG,BSG,Gateway_K
 SG_ LS1_Servicestellung : 38|1@1+ (1,0) [0|1] ""  BSG,Gateway_K
 SG_ LS1_Parklicht_rechts : 6|1@1+ (1,0) [0|1] ""  Multifunktions_SG,BSG,Gateway_K
 SG_ LS1_Parklicht_links : 5|1@1+ (1,0) [0|1] ""  Multifunktions_SG,BSG,Gateway_K
 SG_ LS1_MFL_vorhanden : 33|1@1+ (1,0) [0|1] ""  Reifendruck_VW,Standheizung,BSG,Komfort_SG,Gateway_K
 SG_ LS1_MFA_vorhanden : 34|1@1+ (1,0) [0|1] ""  Reifendruck_VW,Standheizung,BSG,Komfort_SG,Gateway_K
 SG_ LS1_MFA_Tasten : 35|1@1+ (1,0) [0|1] ""  Reifendruck_VW,Standheizung,BSG,Komfort_SG,Gateway_K
 SG_ LS1_LSZ_zurueck : 27|1@1+ (1,0) [0|1] ""  SitzMemo_Fahrer,Gateway_K
 SG_ LS1_LSZ_vor : 26|1@1+ (1,0) [0|1] ""  SitzMemo_Fahrer,Gateway_K
 SG_ LS1_LSY_unten : 25|1@1+ (1,0) [0|1] ""  SitzMemo_Fahrer,Gateway_K
 SG_ LS1_LSY_oben : 24|1@1+ (1,0) [0|1] ""  SitzMemo_Fahrer,Gateway_K
 SG_ LS1_Lichthupe : 2|1@1+ (1,0) [0|1] ""  Multifunktions_SG,BSG,Gateway_K
 SG_ LS1_LHeizung_aktiv : 31|1@1+ (1,0) [0|1] ""  BSG,Gateway_K
 SG_ LS1_KD_Fehler : 23|1@1+ (1,0) [0|1] ""  Gateway_K
 SG_ LS1_Intervallstufen : 16|4@1+ (1,0) [0|15] ""  BSG,Gateway_K
 SG_ LS1_Intervall : 9|1@1+ (1,0) [0|1] ""  Multifunktions_SG,Clima,BSG,Gateway_K
 SG_ LS1_Heckwaschen : 15|1@1+ (1,0) [0|1] ""  Multifunktions_SG,BSG,Gateway_K
 SG_ LS1_Heckintervall : 14|1@1+ (1,0) [0|1] ""  Multifunktions_SG,BSG,Gateway_K
 SG_ LS1_Frontwaschen : 12|1@1+ (1,0) [0|1] ""  Multifunktions_SG,Clima,BSG,Gateway_K
 SG_ LS1_Fernlicht : 3|1@1+ (1,0) [0|1] ""  Multifunktions_SG,BSG,Gateway_K
 SG_ LS1_Easy_Entry_LS : 30|1@1+ (1,0) [0|1] ""  SitzMemo_Fahrer,Gateway_K
 SG_ LS1_Blk_rechts : 1|1@1+ (1,0) [0|1] ""  Multifunktions_SG,BSG,Gateway_K
 SG_ LS1_Blk_links : 0|1@1+ (1,0) [0|1] ""  Multifunktions_SG,BSG,Gateway_K
 SG_ LS1_Bew_Frontwaschen : 13|1@1+ (1,0) [0|1] ""  Clima,BSG,Gateway_K
 SG_ LS1_BC_Up_Cursor : 21|1@1+ (1,0) [0|1] ""  Gateway_K
 SG_ LS1_BC_Reset : 22|1@1+ (1,0) [0|1] ""  Gateway_K
 SG_ LS1_BC_Down_Cursor : 20|1@1+ (1,0) [0|1] ""  Gateway_K

BO_ 1585 mLicht_2: 4 BSG
 SG_ LI2_Standl_HR_def : 25|1@1+ (1,0) [0|1] ""  Gateway_K
 SG_ LI2_Standl_HL_def : 17|1@1+ (1,0) [0|1] ""  Gateway_K
 SG_ LI2_Rueckf_HR_def : 27|1@1+ (1,0) [0|1] ""  Gateway_K
 SG_ LI2_Rueckf_HL_def : 19|1@1+ (1,0) [0|1] ""  Gateway_K
 SG_ LI2_Parkl_VR_def : 9|1@1+ (1,0) [0|1] ""  Gateway_K
 SG_ LI2_Parkl_VL_def : 1|1@1+ (1,0) [0|1] ""  Gateway_K
 SG_ LI2_Nebel_VR_def : 12|1@1+ (1,0) [0|1] ""  Gateway_K
 SG_ LI2_Nebel_VL_def : 4|1@1+ (1,0) [0|1] ""  Gateway_K
 SG_ LI2_Nebel_HR_def : 28|1@1+ (1,0) [0|1] ""  Gateway_K
 SG_ LI2_Nebel_HL_def : 20|1@1+ (1,0) [0|1] ""  Gateway_K
 SG_ LI2_Kurv_R_Licht_def : 15|1@1+ (1,0) [0|1] ""  Gateway_K
 SG_ LI2_Kurv_L_Licht_def : 7|1@1+ (1,0) [0|1] ""  Gateway_K
 SG_ LI2_Kennzl_def : 22|1@1+ (1,0) [0|1] ""  Gateway_K
 SG_ LI2_Fernl_VR_def : 11|1@1+ (1,0) [0|1] ""  Gateway_K
 SG_ LI2_Fernl_VL_def : 3|1@1+ (1,0) [0|1] ""  Gateway_K
 SG_ LI2_Bremsl_HR_def : 26|1@1+ (1,0) [0|1] ""  Gateway_K
 SG_ LI2_Bremsl_HL_def : 18|1@1+ (1,0) [0|1] ""  Gateway_K
 SG_ LI2_Blk_VR_def : 8|1@1+ (1,0) [0|1] ""  Gateway_K
 SG_ LI2_Blk_VL_def : 0|1@1+ (1,0) [0|1] ""  Gateway_K
 SG_ LI2_Blk_Seite_R_def : 14|1@1+ (1,0) [0|1] ""  Gateway_K
 SG_ LI2_BLk_Seite_L_def : 6|1@1+ (1,0) [0|1] ""  Gateway_K
 SG_ LI2_Blk_HR_def : 24|1@1+ (1,0) [0|1] ""  Gateway_K
 SG_ LI2_Blk_HL_def : 16|1@1+ (1,0) [0|1] ""  Gateway_K
 SG_ LI2_Abblend_VR_def : 10|1@1+ (1,0) [0|1] ""  Gateway_K
 SG_ LI2_Abblend_VL_def : 2|1@1+ (1,0) [0|1] ""  Gateway_K
 SG_ LI2_3Bremsl_def : 21|1@1+ (1,0) [0|1] ""  Gateway_K

BO_ 1329 mLicht_1_alt: 4 BSG
 SG_ LIA_Zaehler : 20|4@1+ (1,0) [0|15] "Tabelle" Vector__XXX
 SG_ LIA_Warnblk_Status : 19|1@1+ (1,0) [0|1] ""  TSG_Beifahrer,TSG_Fahrer,Gateway_K
 SG_ LIA_Warnblink : 11|1@1+ (1,0) [0|1] ""  Multifunktions_SG,Anhaenger_SG,TSG_Beifahrer,TSG_Fahrer,Gateway_K
 SG_ LIA_Tagesfahrlicht : 15|1@1+ (1,0) [0|1] ""  Gateway_K
 SG_ LIA_Standlicht : 0|1@1+ (1,0) [0|1] ""  Multifunktions_SG,Anhaenger_SG,Gateway_K
 SG_ LIA_Rueckfahrlicht : 5|1@1+ (1,0) [0|1] ""  TSG_Fahrer,TSG_Beifahrer,SitzMemo_Fahrer,Gateway_K,Einparkhilfe,Anhaenger_SG
 SG_ LIA_Pruefsumme : 24|8@1+ (1,0) [0|255] "Tabelle" Vector__XXX
 SG_ LIA_Parklicht_rechts : 7|1@1+ (1,0) [0|1] ""  Anhaenger_SG,Gateway_K
 SG_ LIA_Parklicht_links : 6|1@1+ (1,0) [0|1] ""  Anhaenger_SG,Gateway_K
 SG_ LIA_Nebelschluss : 4|1@1+ (1,0) [0|1] ""  Anhaenger_SG,Gateway_K
 SG_ LIA_Nebellicht : 3|1@1+ (1,0) [0|1] ""  Gateway_K
 SG_ LIA_Fernlicht : 2|1@1+ (1,0) [0|1] ""  Multifunktions_SG,Gateway_K
 SG_ LIA_Blk_rechts : 9|1@1+ (1,0) [0|1] ""  Anhaenger_SG,TSG_Beifahrer,TSG_Fahrer
 SG_ LIA_Blk_R_Kontrolle : 17|1@1+ (1,0) [0|1] ""  Gateway_K
 SG_ LIA_Blk_links : 8|1@1+ (1,0) [0|1] ""  Anhaenger_SG,TSG_Beifahrer,TSG_Fahrer
 SG_ LIA_Blk_L_Kontrolle : 16|1@1+ (1,0) [0|1] ""  Gateway_K
 SG_ LIA_BLK_Frequenz : 12|1@1+ (1,0) [0|1] ""  Multifunktions_SG,Anhaenger_SG,Gateway_K
 SG_ LIA_Anhaenger : 10|1@1+ (1,0) [0|1] ""  Gateway_K
 SG_ LIA_AFL_Schalter : 13|1@1+ (1,0) [0|1] ""  Gateway_K
 SG_ LIA_Abblendlicht : 1|1@1+ (1,0) [0|1] ""  Multifunktions_SG,Gateway_K

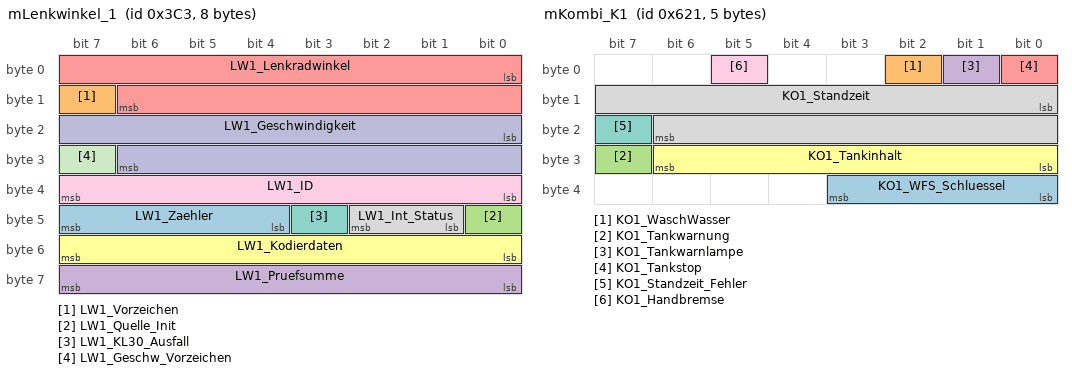
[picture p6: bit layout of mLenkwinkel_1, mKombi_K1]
BO_ 963 mLenkwinkel_1: 8 Gateway_K
 SG_ LW1_Zaehler : 44|4@1+ (1,0) [0|15] "" Vector__XXX
 SG_ LW1_Vorzeichen : 15|1@1+ (1,0) [0|1] ""  Multifunktions_SG
 SG_ LW1_Quelle_Init : 40|1@1+ (1,0) [0|1] "" Vector__XXX
 SG_ LW1_Pruefsumme : 56|8@1+ (1,0) [0|255] "" Vector__XXX
 SG_ LW1_Lenkradwinkel : 0|15@1+ (0.04375,0) [0|1433.6] "°"  Multifunktions_SG
 SG_ LW1_Kodierdaten : 48|8@1+ (1,0) [0|255] "" Vector__XXX
 SG_ LW1_KL30_Ausfall : 43|1@1+ (1,0) [0|1] "" Vector__XXX
 SG_ LW1_Int_Status : 41|2@1+ (1,0) [0|3] "" Vector__XXX
 SG_ LW1_ID : 32|8@1+ (1,0) [0|255] "" Vector__XXX
 SG_ LW1_Geschwindigkeit : 16|15@1+ (0.04375,0) [0|1433.6] "°/Sek" Vector__XXX
 SG_ LW1_Geschw_Vorzeichen : 31|1@1+ (1,0) [0|1] "" Vector__XXX

BO_ 961 mLenkhilfe_1: 6 Gateway_K
 SG_ LH1_Welligkeit : 40|8@1+ (0.01,0) [0|2.54] "Vss" Vector__XXX
 SG_ LH1_Unterst_Leist : 32|8@1+ (0.5,0) [0|100] "%"  BSG
 SG_ LH1_Unterspannung : 24|1@1+ (1,0) [0|1] ""  BSG
 SG_ LH1_Uebertemperatur : 26|1@1+ (1,0) [0|1] ""  BSG
 SG_ LH1_Ueberspannung : 25|1@1+ (1,0) [0|1] ""  BSG
 SG_ LH1_Textbits : 9|4@1+ (1,0) [0|3] ""  BSG
 SG_ LH1_Sleep_Indication : 14|1@1+ (1,0) [0|1] ""  BSG
 SG_ LH1_Sensorik : 27|1@1+ (1,0) [0|1] ""  BSG
 SG_ LH1_NL_Res : 31|1@1+ (1,0) [0|1] ""  BSG
 SG_ LH1_Motor : 30|1@1+ (1,0) [0|1] ""  BSG
 SG_ LH1_Lastinfo : 0|7@1+ (1,0) [0|127] "A"  BSG
 SG_ LH1_KD_Fehler : 15|1@1+ (1,0) [0|1] "" Vector__XXX
 SG_ LH1_gueltig_Wellig : 19|1@1+ (1,0) [0|1] "" Vector__XXX
 SG_ LH1_gueltig_Batt_ab : 18|1@1+ (1,0) [0|1] ""  BSG
 SG_ LH1_Fehlerlampe : 8|1@1+ (1,0) [0|1] ""  BSG
 SG_ LH1_Fehler_Lastinfo : 7|1@1+ (1,0) [0|1] ""  BSG
 SG_ LH1_ECU_intern : 29|1@1+ (1,0) [0|1] ""  BSG
 SG_ LH1_Diag : 16|1@1+ (1,0) [0|1] ""  BSG
 SG_ LH1_CAN_Schnittstelle : 28|1@1+ (1,0) [0|1] ""  BSG
 SG_ LH1_Batterie_ab : 17|1@1+ (1,0) [0|1] ""  BSG
 SG_ LH1_Akustiksig : 13|1@1+ (1,0) [0|1] ""  BSG

BO_ 1569 mKombi_K1: 5 Gateway_K
 SG_ KO1_WFS_Schluessel : 32|4@1+ (1,0) [0|15] "" Vector__XXX
 SG_ KO1_WaschWasser : 2|1@1+ (1,0) [0|1] "" Vector__XXX
 SG_ KO1_Tankwarnung : 31|1@1+ (1,0) [0|1] "" Vector__XXX
 SG_ KO1_Tankwarnlampe : 1|1@1+ (1,0) [0|1] ""  Reifendruck_VW,Standheizung
 SG_ KO1_Tankstop : 0|1@1+ (1,0) [0|1] ""  Reifendruck_VW
 SG_ KO1_Tankinhalt : 24|7@1+ (1,0) [0|126] "" Vector__XXX
 SG_ KO1_Standzeit_Fehler : 23|1@1+ (1,0) [0|1] ""  Reifendruck_VW,Clima
 SG_ KO1_Standzeit : 8|15@1+ (4,0) [0|131068] "sek"  Reifendruck_VW,Clima
 SG_ KO1_Handbremse : 5|1@1+ (1,0) [0|1] ""  Multifunktions_SG,BSG

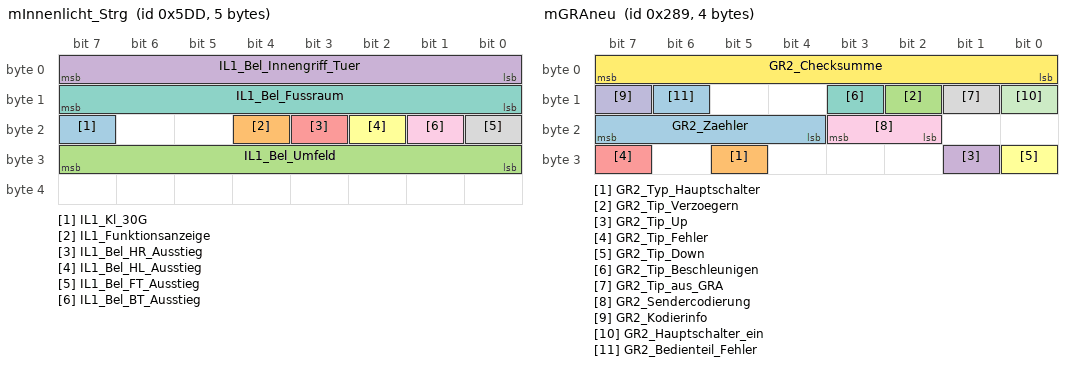
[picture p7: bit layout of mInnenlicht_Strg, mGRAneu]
BO_ 1501 mInnenlicht_Strg: 5 BSG
 SG_ IL1_Kl_30G : 23|1@1+ (1,0) [0|1] "" Vector__XXX
 SG_ IL1_Funktionsanzeige : 20|1@1+ (1,0) [0|1] ""  FHSG_hinten_rechts,FHSG_hinten_links,TSG_Beifahrer,TSG_Fahrer,Komfort_SG
 SG_ IL1_Bel_Umfeld : 24|8@1+ (1,0) [0|100] "%"  TSG_Beifahrer,TSG_Fahrer
 SG_ IL1_Bel_Innengriff_Tuer : 0|8@1+ (1,0) [0|100] "%"  TSG_Beifahrer,TSG_Fahrer,Komfort_SG
 SG_ IL1_Bel_HR_Ausstieg : 19|1@1+ (1,0) [0|1] ""  Komfort_SG
 SG_ IL1_Bel_HL_Ausstieg : 18|1@1+ (1,0) [0|1] ""  Komfort_SG
 SG_ IL1_Bel_Fussraum : 8|8@1+ (1,0) [0|100] "%"  Multifunktions_SG,SitzMemo_Beifahrer,SitzMemo_Fahrer
 SG_ IL1_Bel_FT_Ausstieg : 16|1@1+ (1,0) [0|1] ""  TSG_Fahrer
 SG_ IL1_Bel_BT_Ausstieg : 17|1@1+ (1,0) [0|1] ""  TSG_Beifahrer

BO_ 859 mGW_Motor: 8 Gateway_K
 SG_ GWM_Motordrehzahl : 8|16@1+ (0.25,0) [0|16256] "1/min"  Reifendruck_VW,Reifendruck_Audi,Multifunktions_SG,PTC_Heizung,Standheizung,Clima,BSG,TSG_Beifahrer,TSG_Fahrer
 SG_ GWM_Kuppl_Schalter : 35|1@1+ (1,0) [0|1] ""  BSG
 SG_ GWM_KuehlmittelTemp : 24|8@1+ (0.75,-48.75) [-48|142.5] "°C"  PTC_Heizung,Standheizung,Clima
 SG_ GWM_Komp_Leist_red : 39|1@1+ (1,0) [0|1] ""  Clima,BSG
 SG_ GWM_KLuefter : 40|8@1+ (0.4,0) [0|100] "%"  Clima,BSG
 SG_ GWM_Klimaabschaltung : 37|1@1+ (1,0) [0|1] ""  Clima
 SG_ GWM_Kennfeldkuehlung : 38|1@1+ (1,0) [0|1] ""  Clima,BSG
 SG_ GWM_Heissl_Vorwarn : 36|1@1+ (1,0) [0|1] ""  Clima
 SG_ GWM_GRA_Status : 54|2@1+ (1,0) [0|3] "" Vector__XXX
 SG_ GWM_Fehl_KmittelTemp : 34|1@1+ (1,0) [0|1] ""  Clima
 SG_ GWM_Bremstest_Schalter : 33|1@1+ (1,0) [0|1] ""  BSG
 SG_ GWM_Bremslicht_Schalter : 32|1@1+ (1,0) [0|1] ""  BSG
 SG_ GWM_Anl_Freigabe : 48|1@1+ (1,0) [0|1] ""  BSG
 SG_ GWM_Anl_Ausspuren : 49|1@1+ (1,0) [0|1] ""  BSG
 SG_ GWM_Alt_5_Motor : 2|1@1+ (1,0) [0|1] ""  Clima,BSG
 SG_ GWM_Alt_2_Motor : 1|1@1+ (1,0) [0|1] ""  PTC_Heizung,Standheizung,Clima,BSG
 SG_ GWM_Alt_1_Motor : 0|1@1+ (1,0) [0|1] ""  Reifendruck_VW,Reifendruck_Audi,Multifunktions_SG,PTC_Heizung,Standheizung,Clima,BSG,TSG_Beifahrer,TSG_Fahrer

BO_ 1319 mGW_Kombi: 8 Gateway_K
 SG_ GWK_Umfang_Reifen : 28|12@1+ (1,0) [0|4095] "mm" Vector__XXX
 SG_ GWK_AussenTemp_ungefiltert : 48|8@1+ (0.5,-50) [-50|77] "°C"  Reifendruck_VW,PTC_Heizung,Standheizung,Clima,BSG,TSG_Beifahrer,TSG_Fahrer
 SG_ GWK_AussenTemp_gefiltert : 40|8@1+ (0.5,-50) [-50|77] "°C"  Reifendruck_VW,Reifendruck_Audi,PTC_Heizung,Standheizung,Clima,BSG
 SG_ GWK_AussenTemp_Fehler : 56|1@1+ (1,0) [0|1] ""  Standheizung,Clima,BSG
 SG_ GWK_Alt_3_Kombi : 0|1@1+ (1,0) [0|1] "" Vector__XXX
 SG_ GWK_Alt_2_Kombi : 1|1@1+ (1,0) [0|1] ""  Reifendruck_VW,Reifendruck_Audi,Standheizung,Clima,BSG

BO_ 857 mGW_Bremse_Getriebe: 8 Gateway_K
 SG_ GWB_Wegimpulse_Fehler : 39|1@1+ (1,0) [0|1] ""  Einparkhilfe
 SG_ GWB_Wegimpulse : 24|11@1+ (1,0) [0|2047] ""  Einparkhilfe
 SG_ GWB_Wegimpuls_Status : 35|1@1+ (1,0) [0|1] ""  Einparkhilfe
 SG_ GWB_Shift_Lock : 59|1@1+ (1,0) [0|1] "" Vector__XXX
 SG_ GWB_Schlechtweg_Fehler : 54|1@1+ (1,0) [0|1] "" Vector__XXX
 SG_ GWB_Schlechtweg : 53|1@1+ (1,0) [0|1] "" Vector__XXX
 SG_ GWB_Schaltvorgang : 56|1@1+ (1,0) [0|1] "" Vector__XXX
 SG_ GWB_res_Richtung : 46|1@1+ (1,0) [0|1] "" Vector__XXX
 SG_ GWB_Info_Waehlhebel : 60|4@1+ (1,0) [0|15] "Tabelle"  Multifunktions_SG,Einparkhilfe,BSG
 SG_ GWB_Impulszahl : 40|6@1+ (1,0) [0|1] "" Vector__XXX
 SG_ GWB_Geschw_Ersatz : 55|1@1+ (1,0) [0|1] ""  Reifendruck_VW,Multifunktions_SG
 SG_ GWB_FzgGeschw_Quelle : 8|1@1+ (1,0) [0|1] ""  Reifendruck_VW,Reifendruck_Audi,Multifunktions_SG,Verdeck,Clima,BSG
 SG_ GWB_FzgGeschw : 9|15@1+ (0.01,0) [0|325] "km/h"  Reifendruck_VW,Reifendruck_Audi,Multifunktions_SG,SitzMemo_Fahrer,Einparkhilfe,Verdeck,Clima,BSG,FHSG_hinten_rechts,FHSG_hinten_links,TSG_Beifahrer,TSG_Fahrer,Komfort_SG
 SG_ GWB_Alt_FzgGeschw : 0|1@1+ (1,0) [0|1] ""  Reifendruck_VW,Reifendruck_Audi,Multifunktions_SG,SitzMemo_Fahrer,Einparkhilfe,Verdeck,Clima,BSG,FHSG_hinten_rechts,FHSG_hinten_links,TSG_Beifahrer,TSG_Fahrer,Komfort_SG
 SG_ GWB_Alt_2_Getriebe : 4|1@1+ (1,0) [0|1] "" Vector__XXX
 SG_ GWB_Alt_2_Bremse : 1|1@1+ (1,0) [0|1] "" Vector__XXX
 SG_ GWB_Alt_1_Getriebe : 3|1@1+ (1,0) [0|1] ""  Einparkhilfe,BSG
 SG_ GWB_Alt_1_Bremse : 2|1@1+ (1,0) [0|1] ""  BSG
 SG_ GWB_ABS_Bremsung : 50|1@1+ (1,0) [0|1] ""  BSG

BO_ 649 mGRAneu: 4 SMLS
 SG_ GR2_Zaehler : 20|4@1+ (1,0) [0|15] "Tabelle"  Gateway_K
 SG_ GR2_Typ_Hauptschalter : 29|1@1+ (1,0) [0|1] ""  Gateway_K
 SG_ GR2_Tip_Verzoegern : 10|1@1+ (1,0) [0|1] ""  Gateway_K
 SG_ GR2_Tip_Up : 25|1@1+ (1,0) [0|1] ""  Gateway_K
 SG_ GR2_Tip_Fehler : 31|1@1+ (1,0) [0|1] ""  Gateway_K
 SG_ GR2_Tip_Down : 24|1@1+ (1,0) [0|1] ""  Gateway_K
 SG_ GR2_Tip_Beschleunigen : 11|1@1+ (1,0) [0|1] ""  Gateway_K
 SG_ GR2_Tip_aus_GRA : 9|1@1+ (1,0) [0|1] ""  Gateway_K
 SG_ GR2_Sendercodierung : 18|2@1+ (1,0) [0|3] "Tabelle"  Gateway_K
 SG_ GR2_Kodierinfo : 15|1@1+ (1,0) [0|1] ""  Gateway_K
 SG_ GR2_Hauptschalter_ein : 8|1@1+ (1,0) [0|1] ""  Gateway_K
 SG_ GR2_Checksumme : 0|8@1+ (1,0) [0|255] "Tabelle"  Gateway_K
 SG_ GR2_Bedienteil_Fehler : 14|1@1+ (1,0) [0|1] ""  Gateway_K

BO_ 1619 mGateway_3: 3 Gateway_K
 SG_ GW3_Sprachvariante : 8|8@1+ (1,0) [0|10] "Tabelle"  Reifendruck_VW,Standheizung,Clima,BSG,Komfort_SG
 SG_ GW3_Motortyp : 16|6@1+ (1,0) [0|63] "Tabelle"  Standheizung,Clima
 SG_ GW3_Laendervariante : 0|6@1+ (1,0) [0|7] "Tabelle"  Reifendruck_VW,Standheizung,Clima,BSG,TSG_Beifahrer,TSG_Fahrer,Komfort_SG

BO_ 1631 mFzg_Ident: 8 Gateway_K
 SG_ FI1_MUX : 0|8@1+ (1,0) [0|255] "" Vector__XXX
 SG_ FI1_Data7 : 56|8@1+ (1,0) [0|255] "" Vector__XXX
 SG_ FI1_Data6 : 48|8@1+ (1,0) [0|255] "" Vector__XXX
 SG_ FI1_Data5 : 40|8@1+ (1,0) [0|255] "" Vector__XXX
 SG_ FI1_Data4 : 32|8@1+ (1,0) [0|255] "" Vector__XXX
 SG_ FI1_Data3 : 24|8@1+ (1,0) [0|255] "" Vector__XXX
 SG_ FI1_Data2 : 16|8@1+ (1,0) [0|255] "" Vector__XXX
 SG_ FI1_Data1 : 8|8@1+ (1,0) [0|255] "" Vector__XXX

BO_ 2016 Messdaten1: 8 Clima
 SG_ Messdaten8 : 56|8@1+ (1,0) [0|0] "" Vector__XXX
 SG_ Messdaten7 : 48|8@1+ (1,0) [0|0] "" Vector__XXX
 SG_ Messdaten6 : 40|8@1+ (1,0) [0|0] "" Vector__XXX
 SG_ Messdaten5 : 32|8@1+ (1,0) [0|0] "" Vector__XXX
 SG_ Messdaten4 : 24|8@1+ (1,0) [0|0] "" Vector__XXX
 SG_ Messdaten3 : 16|8@1+ (1,0) [0|0] "" Vector__XXX
 SG_ Messdaten2 : 8|8@1+ (1,0) [0|0] "" Vector__XXX
 SG_ Messdaten1 : 0|8@1+ (1,0) [0|0] "" Vector__XXX

BO_ 1550 mEinheiten: 2 Gateway_K
 SG_ EH1_Profil : 8|4@1+ (1,0) [0|15] ""  Reifendruck_VW,Standheizung,BSG,Komfort_SG
 SG_ EH1_Einh_Vol : 2|1@1+ (1,0) [0|1] "" Vector__XXX
 SG_ EH1_Einh_Verbr : 3|1@1+ (1,0) [0|1] "" Vector__XXX
 SG_ EH1_Einh_Temp : 1|1@1+ (1,0) [0|1] ""  Standheizung,Clima
 SG_ EH1_Einh_Strck : 0|1@1+ (1,0) [0|1] "" Vector__XXX
 SG_ EH1_Einh_Druck : 4|1@1+ (1,0) [0|1] ""  Reifendruck_VW

BO_ 1583 mDisplay_1: 4 Gateway_K
 SG_ DY1_Reset : 1|1@1+ (1,0) [0|1] ""  Reifendruck_VW,Standheizung,BSG,Komfort_SG
 SG_ DY1_Global_Reset : 2|1@1+ (1,0) [0|1] ""  Reifendruck_VW,Standheizung,BSG,Komfort_SG
 SG_ DY1_Display_OK : 0|1@1+ (1,0) [0|1] ""  Reifendruck_VW,Standheizung,BSG,Komfort_SG
 SG_ DY1_Bereich3 : 24|8@1+ (1,0) [0|255] ""  Reifendruck_VW,Standheizung,BSG,Komfort_SG
 SG_ DY1_Bereich2 : 16|8@1+ (1,0) [0|255] ""  Reifendruck_VW,Standheizung,BSG,Komfort_SG
 SG_ DY1_Bereich1 : 8|8@1+ (1,0) [0|255] ""  Reifendruck_VW,Standheizung,BSG,Komfort_SG

BO_ 1589 mDimmung: 3 BSG
 SG_ DI1_Schalter_def : 15|1@1+ (1,0) [0|1] ""  SMLS,Clima,TSG_Beifahrer,TSG_Fahrer,Komfort_SG,Gateway_K
 SG_ DI1_Schalter : 8|7@1+ (1,0) [0|100] "%"  SMLS,Clima,TSG_Beifahrer,TSG_Fahrer,Komfort_SG,Gateway_K
 SG_ DI1_Display_def : 7|1@1+ (1,0) [0|1] ""  Multifunktions_SG,SMLS,SitzMemo_Beifahrer,SitzMemo_Fahrer,Einparkhilfe,Verdeck,Clima,FHSG_hinten_rechts,FHSG_hinten_links,TSG_Beifahrer,TSG_Fahrer,Komfort_SG,Gateway_K
 SG_ DI1_Display : 0|7@1+ (1,0) [0|100] "%"  Multifunktions_SG,SMLS,SitzMemo_Beifahrer,SitzMemo_Fahrer,Einparkhilfe,Verdeck,Clima,FHSG_hinten_rechts,FHSG_hinten_links,TSG_Beifahrer,TSG_Fahrer,Komfort_SG,Gateway_K

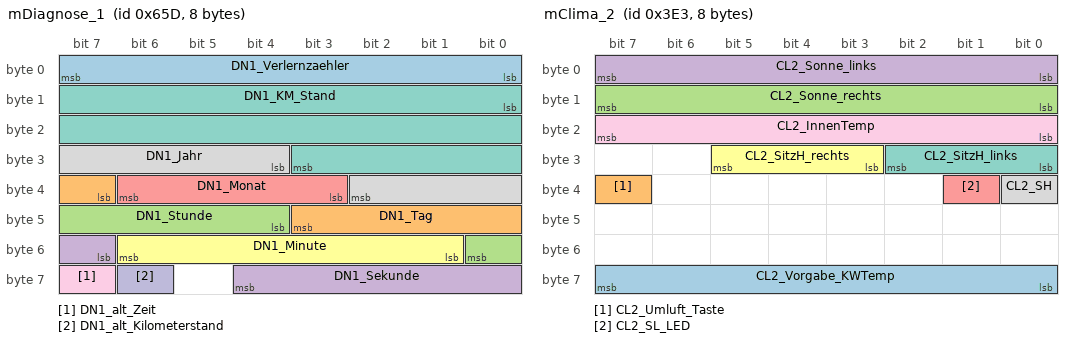
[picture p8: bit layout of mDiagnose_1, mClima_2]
BO_ 1629 mDiagnose_1: 8 Gateway_K
 SG_ DN1_Verlernzaehler : 0|8@1+ (1,0) [0|255] ""  Reifendruck_VW,Reifendruck_Audi,Multifunktions_SG,SMLS,SitzMemo_Beifahrer,SitzMemo_Fahrer,Einparkhilfe,Verdeck,PTC_Heizung,Standheizung,Clima,Anhaenger_SG,BSG,FHSG_hinten_rechts,FHSG_hinten_links,TSG_Beifahrer,TSG_Fahrer,Komfort_SG
 SG_ DN1_Tag : 39|5@1+ (1,0) [0|31] ""  Reifendruck_VW,Reifendruck_Audi,Multifunktions_SG,SMLS,SitzMemo_Beifahrer,SitzMemo_Fahrer,Einparkhilfe,Verdeck,PTC_Heizung,Standheizung,Clima,Anhaenger_SG,BSG,FHSG_hinten_rechts,FHSG_hinten_links,TSG_Beifahrer,TSG_Fahrer,Komfort_SG
 SG_ DN1_Stunde : 44|5@1+ (1,0) [0|23] "h"  Reifendruck_VW,Reifendruck_Audi,Multifunktions_SG,SMLS,SitzMemo_Beifahrer,SitzMemo_Fahrer,Einparkhilfe,Verdeck,PTC_Heizung,Standheizung,Clima,Anhaenger_SG,BSG,FHSG_hinten_rechts,FHSG_hinten_links,TSG_Beifahrer,TSG_Fahrer,Komfort_SG
 SG_ DN1_Sekunde : 55|6@1+ (1,0) [0|59] "sec"  Reifendruck_VW,Reifendruck_Audi,Multifunktions_SG,SMLS,SitzMemo_Beifahrer,SitzMemo_Fahrer,Einparkhilfe,Verdeck,PTC_Heizung,Standheizung,Clima,Anhaenger_SG,BSG,FHSG_hinten_rechts,FHSG_hinten_links,TSG_Beifahrer,TSG_Fahrer,Komfort_SG
 SG_ DN1_Monat : 35|4@1+ (1,0) [0|15] ""  Reifendruck_VW,Reifendruck_Audi,Multifunktions_SG,SMLS,SitzMemo_Beifahrer,SitzMemo_Fahrer,Einparkhilfe,Verdeck,PTC_Heizung,Standheizung,Clima,Anhaenger_SG,BSG,FHSG_hinten_rechts,FHSG_hinten_links,TSG_Beifahrer,TSG_Fahrer,Komfort_SG
 SG_ DN1_Minute : 49|6@1+ (1,0) [0|59] "min"  Reifendruck_VW,Reifendruck_Audi,Multifunktions_SG,SMLS,SitzMemo_Beifahrer,SitzMemo_Fahrer,Einparkhilfe,Verdeck,PTC_Heizung,Standheizung,Clima,Anhaenger_SG,BSG,FHSG_hinten_rechts,FHSG_hinten_links,TSG_Beifahrer,TSG_Fahrer,Komfort_SG
 SG_ DN1_KM_Stand : 8|20@1+ (1,0) [0|1048575] "km"  Reifendruck_VW,Reifendruck_Audi,Multifunktions_SG,SMLS,SitzMemo_Beifahrer,SitzMemo_Fahrer,Einparkhilfe,Verdeck,PTC_Heizung,Standheizung,Clima,Anhaenger_SG,BSG,FHSG_hinten_rechts,FHSG_hinten_links,TSG_Beifahrer,TSG_Fahrer,Komfort_SG
 SG_ DN1_Jahr : 28|7@1+ (1,2000) [2000|2127] ""  Reifendruck_VW,Reifendruck_Audi,Multifunktions_SG,SMLS,SitzMemo_Beifahrer,SitzMemo_Fahrer,Einparkhilfe,Verdeck,PTC_Heizung,Standheizung,Clima,Anhaenger_SG,BSG,FHSG_hinten_rechts,FHSG_hinten_links,TSG_Beifahrer,TSG_Fahrer,Komfort_SG
 SG_ DN1_alt_Zeit : 63|1@1+ (1,0) [0|1] ""  Reifendruck_VW,Reifendruck_Audi,Multifunktions_SG,SMLS,SitzMemo_Beifahrer,SitzMemo_Fahrer,Einparkhilfe,Verdeck,PTC_Heizung,Standheizung,Clima,Anhaenger_SG,BSG,FHSG_hinten_rechts,FHSG_hinten_links,TSG_Beifahrer,TSG_Fahrer,Komfort_SG
 SG_ DN1_alt_Kilometerstand : 62|1@1+ (1,0) [0|1] ""  Reifendruck_VW,Reifendruck_Audi,Multifunktions_SG,SMLS,SitzMemo_Beifahrer,SitzMemo_Fahrer,Einparkhilfe,Verdeck,PTC_Heizung,Standheizung,Clima,Anhaenger_SG,BSG,FHSG_hinten_rechts,FHSG_hinten_links,TSG_Beifahrer,TSG_Fahrer,Komfort_SG

BO_ 995 mClima_2: 8 Clima
 SG_ CL2_Vorgabe_KWTemp : 56|8@1+ (0.75,-48.75) [-48|142.5] "°C"  Gateway_K
 SG_ CL2_Umluft_Taste : 39|1@1+ (1,0) [0|1] ""  FHSG_hinten_rechts,FHSG_hinten_links,TSG_Beifahrer,TSG_Fahrer,Komfort_SG,Gateway_K
 SG_ CL2_Sonne_rechts : 8|8@1+ (4,0) [0|1016] "W/m²"  Gateway_K
 SG_ CL2_Sonne_links : 0|8@1+ (4,0) [0|1016] "W/m²"  Gateway_K
 SG_ CL2_SL_LED : 33|1@1+ (1,0) [0|1] ""  Komfort_SG,Gateway_K
 SG_ CL2_SitzH_rechts : 27|3@1+ (1,0) [0|7] ""  Gateway_K
 SG_ CL2_SitzH_links : 24|3@1+ (1,0) [0|7] ""  Gateway_K
 SG_ CL2_SH : 32|1@1+ (1,0) [0|1] ""  Standheizung,Gateway_K
 SG_ CL2_InnenTemp : 16|8@1+ (0.5,-50) [-50|77] "K"  Standheizung,Gateway_K

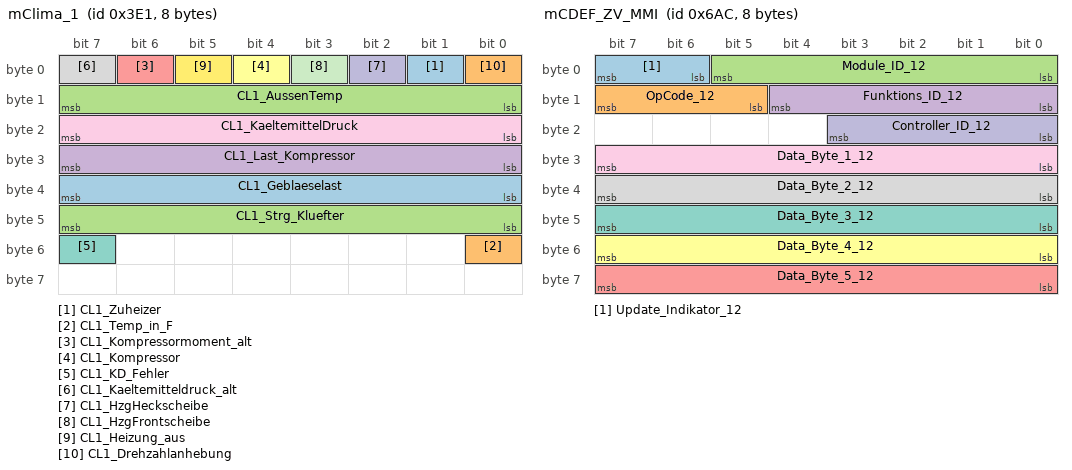
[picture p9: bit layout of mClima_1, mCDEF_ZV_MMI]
BO_ 993 mClima_1: 8 Clima
 SG_ CL1_Zuheizer : 1|1@1+ (1,0) [0|1] ""  PTC_Heizung,Standheizung,Gateway_K
 SG_ CL1_Temp_in_F : 48|1@1+ (1,0) [0|1] ""  Gateway_K
 SG_ CL1_Strg_Kluefter : 40|8@1+ (0.4,0) [0|100] "%"  BSG,Gateway_K
 SG_ CL1_Last_Kompressor : 24|8@1+ (0.25,0) [0|63.5] "Nm"  BSG,Gateway_K
 SG_ CL1_Kompressormoment_alt : 6|1@1+ (1,0) [0|1] ""  Gateway_K
 SG_ CL1_Kompressor : 4|1@1+ (1,0) [0|1] ""  BSG,Gateway_K
 SG_ CL1_KD_Fehler : 55|1@1+ (1,0) [0|1] ""  Gateway_K
 SG_ CL1_Kaeltemitteldruck_alt : 7|1@1+ (1,0) [0|1] ""  Gateway_K
 SG_ CL1_KaeltemittelDruck : 16|8@1+ (0.2,0) [0|50.8] "bar"  BSG,Gateway_K
 SG_ CL1_HzgHeckscheibe : 2|1@1+ (1,0) [0|1] ""  BSG,TSG_Beifahrer,TSG_Fahrer,Gateway_K
 SG_ CL1_HzgFrontscheibe : 3|1@1+ (1,0) [0|1] ""  BSG,Gateway_K
 SG_ CL1_Heizung_aus : 5|1@1+ (1,0) [0|1] ""  Gateway_K
 SG_ CL1_Geblaeselast : 32|8@1+ (0.4,0) [0|100] "%"  BSG,Gateway_K
 SG_ CL1_Drehzahlanhebung : 0|1@1+ (1,0) [0|1] ""  Standheizung,Gateway_K
 SG_ CL1_AussenTemp : 8|8@1+ (0.5,-50) [-50|77] "°C"  Standheizung,Gateway_K

BO_ 1708 mCDEF_ZV_MMI: 8 Komfort_SG
 SG_ Update_Indikator_12 : 6|2@1+ (1,0) [0|3] ""  Gateway_K
 SG_ OpCode_12 : 13|3@1+ (1,0) [0|7] ""  Gateway_K
 SG_ Module_ID_12 : 0|6@1+ (1,0) [0|63] ""  Gateway_K
 SG_ Funktions_ID_12 : 8|5@1+ (1,0) [0|31] ""  Gateway_K
 SG_ Data_Byte_5_12 : 56|8@1+ (1,0) [0|255] ""  Gateway_K
 SG_ Data_Byte_4_12 : 48|8@1+ (1,0) [0|255] ""  Gateway_K
 SG_ Data_Byte_3_12 : 40|8@1+ (1,0) [0|255] ""  Gateway_K
 SG_ Data_Byte_2_12 : 32|8@1+ (1,0) [0|255] ""  Gateway_K
 SG_ Data_Byte_1_12 : 24|8@1+ (1,0) [0|255] ""  Gateway_K
 SG_ Controller_ID_12 : 16|4@1+ (1,0) [0|15] ""  Gateway_K

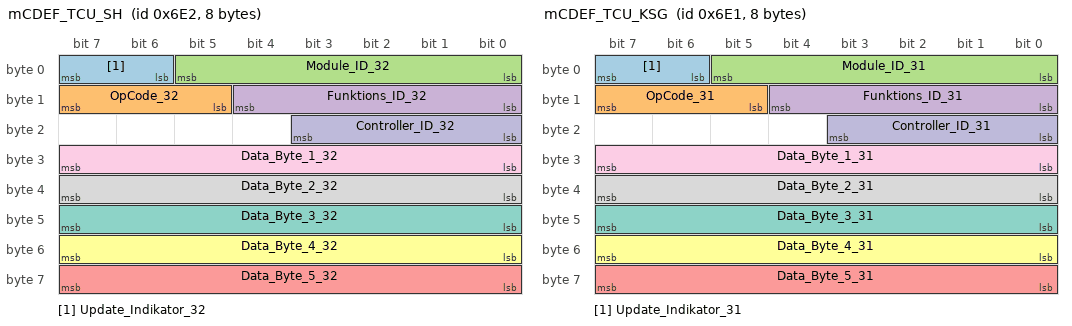
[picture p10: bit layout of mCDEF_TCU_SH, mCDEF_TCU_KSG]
BO_ 1762 mCDEF_TCU_SH: 8 Gateway_K
 SG_ Update_Indikator_32 : 6|2@1+ (1,0) [0|3] ""  Standheizung
 SG_ OpCode_32 : 13|3@1+ (1,0) [0|7] ""  Standheizung
 SG_ Module_ID_32 : 0|6@1+ (1,0) [0|63] ""  Standheizung
 SG_ Funktions_ID_32 : 8|5@1+ (1,0) [0|31] ""  Standheizung
 SG_ Data_Byte_5_32 : 56|8@1+ (1,0) [0|255] ""  Standheizung
 SG_ Data_Byte_4_32 : 48|8@1+ (1,0) [0|255] ""  Standheizung
 SG_ Data_Byte_3_32 : 40|8@1+ (1,0) [0|255] ""  Standheizung
 SG_ Data_Byte_2_32 : 32|8@1+ (1,0) [0|255] ""  Standheizung
 SG_ Data_Byte_1_32 : 24|8@1+ (1,0) [0|255] ""  Standheizung
 SG_ Controller_ID_32 : 16|4@1+ (1,0) [0|15] ""  Standheizung

BO_ 1761 mCDEF_TCU_KSG: 8 Gateway_K
 SG_ Update_Indikator_31 : 6|2@1+ (1,0) [0|3] ""  Komfort_SG
 SG_ OpCode_31 : 13|3@1+ (1,0) [0|7] ""  Komfort_SG
 SG_ Module_ID_31 : 0|6@1+ (1,0) [0|63] ""  Komfort_SG
 SG_ Funktions_ID_31 : 8|5@1+ (1,0) [0|31] ""  Komfort_SG
 SG_ Data_Byte_5_31 : 56|8@1+ (1,0) [0|255] ""  Komfort_SG
 SG_ Data_Byte_4_31 : 48|8@1+ (1,0) [0|255] ""  Komfort_SG
 SG_ Data_Byte_3_31 : 40|8@1+ (1,0) [0|255] ""  Komfort_SG
 SG_ Data_Byte_2_31 : 32|8@1+ (1,0) [0|255] ""  Komfort_SG
 SG_ Data_Byte_1_31 : 24|8@1+ (1,0) [0|255] ""  Komfort_SG
 SG_ Controller_ID_31 : 16|4@1+ (1,0) [0|15] ""  Komfort_SG

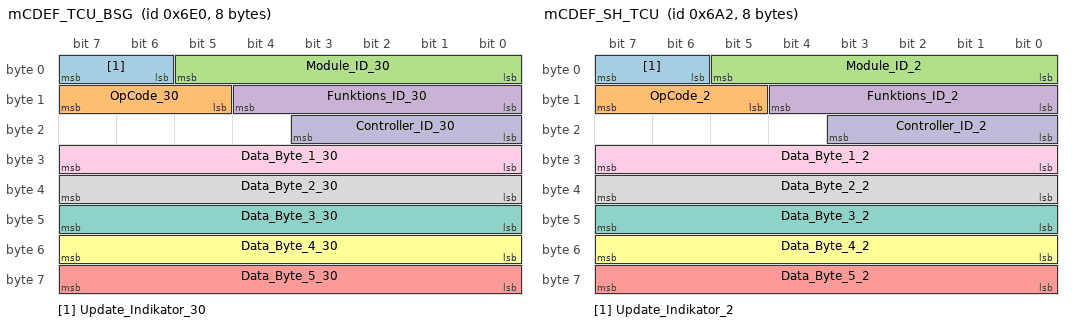
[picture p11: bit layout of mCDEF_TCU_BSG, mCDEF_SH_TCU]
BO_ 1760 mCDEF_TCU_BSG: 8 Gateway_K
 SG_ Update_Indikator_30 : 6|2@1+ (1,0) [0|3] ""  BSG
 SG_ OpCode_30 : 13|3@1+ (1,0) [0|7] ""  BSG
 SG_ Module_ID_30 : 0|6@1+ (1,0) [0|63] ""  BSG
 SG_ Funktions_ID_30 : 8|5@1+ (1,0) [0|31] ""  BSG
 SG_ Data_Byte_5_30 : 56|8@1+ (1,0) [0|255] ""  BSG
 SG_ Data_Byte_4_30 : 48|8@1+ (1,0) [0|255] ""  BSG
 SG_ Data_Byte_3_30 : 40|8@1+ (1,0) [0|255] ""  BSG
 SG_ Data_Byte_2_30 : 32|8@1+ (1,0) [0|255] ""  BSG
 SG_ Data_Byte_1_30 : 24|8@1+ (1,0) [0|255] ""  BSG
 SG_ Controller_ID_30 : 16|4@1+ (1,0) [0|15] ""  BSG

BO_ 1698 mCDEF_SH_TCU: 8 Standheizung
 SG_ Update_Indikator_2 : 6|2@1+ (1,0) [0|3] ""  Gateway_K
 SG_ OpCode_2 : 13|3@1+ (1,0) [0|7] ""  Gateway_K
 SG_ Module_ID_2 : 0|6@1+ (1,0) [0|63] ""  Gateway_K
 SG_ Funktions_ID_2 : 8|5@1+ (1,0) [0|31] ""  Gateway_K
 SG_ Data_Byte_5_2 : 56|8@1+ (1,0) [0|255] ""  Gateway_K
 SG_ Data_Byte_4_2 : 48|8@1+ (1,0) [0|255] ""  Gateway_K
 SG_ Data_Byte_3_2 : 40|8@1+ (1,0) [0|255] ""  Gateway_K
 SG_ Data_Byte_2_2 : 32|8@1+ (1,0) [0|255] ""  Gateway_K
 SG_ Data_Byte_1_2 : 24|8@1+ (1,0) [0|255] ""  Gateway_K
 SG_ Controller_ID_2 : 16|4@1+ (1,0) [0|15] ""  Gateway_K

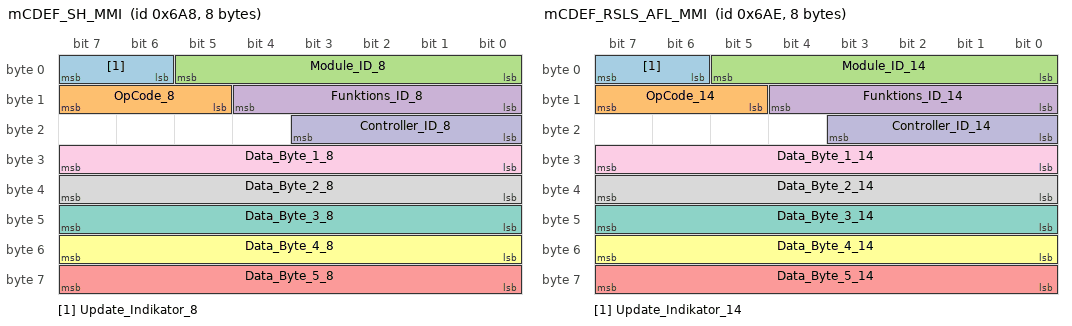
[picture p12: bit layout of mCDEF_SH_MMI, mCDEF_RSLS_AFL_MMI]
BO_ 1704 mCDEF_SH_MMI: 8 Standheizung
 SG_ Update_Indikator_8 : 6|2@1+ (1,0) [0|3] ""  Gateway_K
 SG_ OpCode_8 : 13|3@1+ (1,0) [0|7] ""  Gateway_K
 SG_ Module_ID_8 : 0|6@1+ (1,0) [0|63] ""  Gateway_K
 SG_ Funktions_ID_8 : 8|5@1+ (1,0) [0|31] ""  Gateway_K
 SG_ Data_Byte_5_8 : 56|8@1+ (1,0) [0|255] ""  Gateway_K
 SG_ Data_Byte_4_8 : 48|8@1+ (1,0) [0|255] ""  Gateway_K
 SG_ Data_Byte_3_8 : 40|8@1+ (1,0) [0|255] ""  Gateway_K
 SG_ Data_Byte_2_8 : 32|8@1+ (1,0) [0|255] ""  Gateway_K
 SG_ Data_Byte_1_8 : 24|8@1+ (1,0) [0|255] ""  Gateway_K
 SG_ Controller_ID_8 : 16|4@1+ (1,0) [0|15] ""  Gateway_K

BO_ 1710 mCDEF_RSLS_AFL_MMI: 8 BSG
 SG_ Update_Indikator_14 : 6|2@1+ (1,0) [0|3] ""  Gateway_K
 SG_ OpCode_14 : 13|3@1+ (1,0) [0|7] ""  Gateway_K
 SG_ Module_ID_14 : 0|6@1+ (1,0) [0|63] ""  Gateway_K
 SG_ Funktions_ID_14 : 8|5@1+ (1,0) [0|31] ""  Gateway_K
 SG_ Data_Byte_5_14 : 56|8@1+ (1,0) [0|255] ""  Gateway_K
 SG_ Data_Byte_4_14 : 48|8@1+ (1,0) [0|255] ""  Gateway_K
 SG_ Data_Byte_3_14 : 40|8@1+ (1,0) [0|255] ""  Gateway_K
 SG_ Data_Byte_2_14 : 32|8@1+ (1,0) [0|255] ""  Gateway_K
 SG_ Data_Byte_1_14 : 24|8@1+ (1,0) [0|255] ""  Gateway_K
 SG_ Controller_ID_14 : 16|4@1+ (1,0) [0|15] ""  Gateway_K

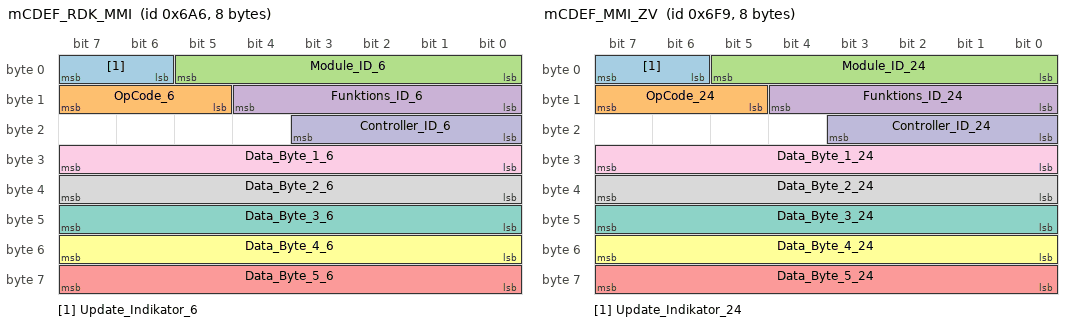
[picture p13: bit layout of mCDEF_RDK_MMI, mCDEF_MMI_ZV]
BO_ 1702 mCDEF_RDK_MMI: 8 Reifendruck_Audi
 SG_ Update_Indikator_6 : 6|2@1+ (1,0) [0|3] ""  Gateway_K
 SG_ OpCode_6 : 13|3@1+ (1,0) [0|7] ""  Gateway_K
 SG_ Module_ID_6 : 0|6@1+ (1,0) [0|63] ""  Gateway_K
 SG_ Funktions_ID_6 : 8|5@1+ (1,0) [0|31] ""  Gateway_K
 SG_ Data_Byte_5_6 : 56|8@1+ (1,0) [0|255] ""  Gateway_K
 SG_ Data_Byte_4_6 : 48|8@1+ (1,0) [0|255] ""  Gateway_K
 SG_ Data_Byte_3_6 : 40|8@1+ (1,0) [0|255] ""  Gateway_K
 SG_ Data_Byte_2_6 : 32|8@1+ (1,0) [0|255] ""  Gateway_K
 SG_ Data_Byte_1_6 : 24|8@1+ (1,0) [0|255] ""  Gateway_K
 SG_ Controller_ID_6 : 16|4@1+ (1,0) [0|15] ""  Gateway_K

BO_ 1785 mCDEF_MMI_ZV: 8 Gateway_K
 SG_ Update_Indikator_24 : 6|2@1+ (1,0) [0|3] ""  Komfort_SG
 SG_ OpCode_24 : 13|3@1+ (1,0) [0|7] ""  Komfort_SG
 SG_ Module_ID_24 : 0|6@1+ (1,0) [0|63] ""  Komfort_SG
 SG_ Funktions_ID_24 : 8|5@1+ (1,0) [0|31] ""  Komfort_SG
 SG_ Data_Byte_5_24 : 56|8@1+ (1,0) [0|255] ""  Komfort_SG
 SG_ Data_Byte_4_24 : 48|8@1+ (1,0) [0|255] ""  Komfort_SG
 SG_ Data_Byte_3_24 : 40|8@1+ (1,0) [0|255] ""  Komfort_SG
 SG_ Data_Byte_2_24 : 32|8@1+ (1,0) [0|255] ""  Komfort_SG
 SG_ Data_Byte_1_24 : 24|8@1+ (1,0) [0|255] ""  Komfort_SG
 SG_ Controller_ID_24 : 16|4@1+ (1,0) [0|15] ""  Komfort_SG

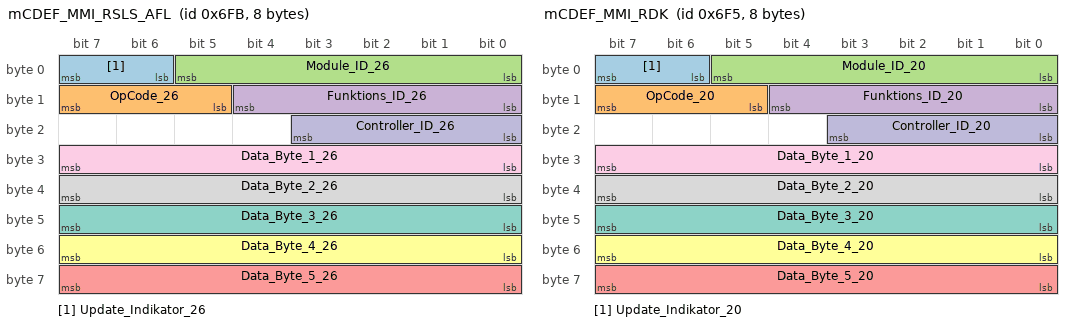
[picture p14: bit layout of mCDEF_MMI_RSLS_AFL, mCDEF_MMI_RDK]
BO_ 1787 mCDEF_MMI_RSLS_AFL: 8 Gateway_K
 SG_ Update_Indikator_26 : 6|2@1+ (1,0) [0|3] ""  BSG
 SG_ OpCode_26 : 13|3@1+ (1,0) [0|7] ""  BSG
 SG_ Module_ID_26 : 0|6@1+ (1,0) [0|63] ""  BSG
 SG_ Funktions_ID_26 : 8|5@1+ (1,0) [0|31] ""  BSG
 SG_ Data_Byte_5_26 : 56|8@1+ (1,0) [0|255] ""  BSG
 SG_ Data_Byte_4_26 : 48|8@1+ (1,0) [0|255] ""  BSG
 SG_ Data_Byte_3_26 : 40|8@1+ (1,0) [0|255] ""  BSG
 SG_ Data_Byte_2_26 : 32|8@1+ (1,0) [0|255] ""  BSG
 SG_ Data_Byte_1_26 : 24|8@1+ (1,0) [0|255] ""  BSG
 SG_ Controller_ID_26 : 16|4@1+ (1,0) [0|15] ""  BSG

BO_ 1781 mCDEF_MMI_RDK: 8 Gateway_K
 SG_ Update_Indikator_20 : 6|2@1+ (1,0) [0|3] ""  Reifendruck_Audi
 SG_ OpCode_20 : 13|3@1+ (1,0) [0|7] ""  Reifendruck_Audi
 SG_ Module_ID_20 : 0|6@1+ (1,0) [0|63] ""  Reifendruck_Audi
 SG_ Funktions_ID_20 : 8|5@1+ (1,0) [0|31] ""  Reifendruck_Audi
 SG_ Data_Byte_5_20 : 56|8@1+ (1,0) [0|255] ""  Reifendruck_Audi
 SG_ Data_Byte_4_20 : 48|8@1+ (1,0) [0|255] ""  Reifendruck_Audi
 SG_ Data_Byte_3_20 : 40|8@1+ (1,0) [0|255] ""  Reifendruck_Audi
 SG_ Data_Byte_2_20 : 32|8@1+ (1,0) [0|255] ""  Reifendruck_Audi
 SG_ Data_Byte_1_20 : 24|8@1+ (1,0) [0|255] ""  Reifendruck_Audi
 SG_ Controller_ID_20 : 16|4@1+ (1,0) [0|15] ""  Reifendruck_Audi

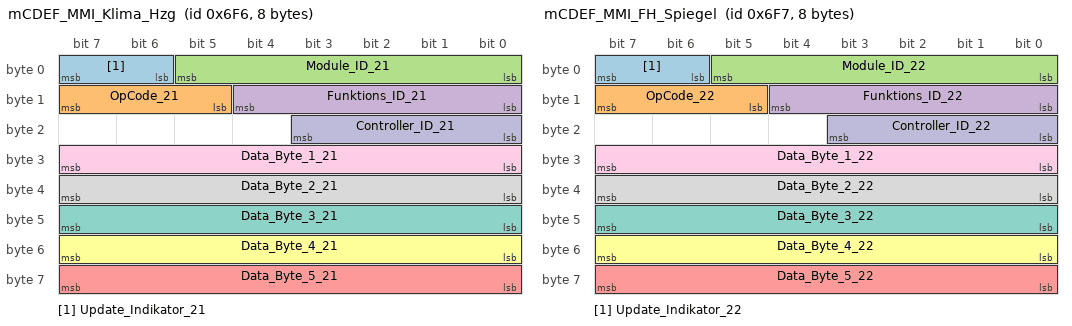
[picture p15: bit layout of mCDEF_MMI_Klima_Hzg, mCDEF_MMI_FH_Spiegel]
BO_ 1782 mCDEF_MMI_Klima_Hzg: 8 Gateway_K
 SG_ Update_Indikator_21 : 6|2@1+ (1,0) [0|3] ""  Clima
 SG_ OpCode_21 : 13|3@1+ (1,0) [0|7] ""  Clima
 SG_ Module_ID_21 : 0|6@1+ (1,0) [0|63] ""  Clima
 SG_ Funktions_ID_21 : 8|5@1+ (1,0) [0|31] ""  Clima
 SG_ Data_Byte_5_21 : 56|8@1+ (1,0) [0|255] ""  Clima
 SG_ Data_Byte_4_21 : 48|8@1+ (1,0) [0|255] ""  Clima
 SG_ Data_Byte_3_21 : 40|8@1+ (1,0) [0|255] ""  Clima
 SG_ Data_Byte_2_21 : 32|8@1+ (1,0) [0|255] ""  Clima
 SG_ Data_Byte_1_21 : 24|8@1+ (1,0) [0|255] ""  Clima
 SG_ Controller_ID_21 : 16|4@1+ (1,0) [0|15] ""  Clima

BO_ 1783 mCDEF_MMI_FH_Spiegel: 8 Gateway_K
 SG_ Update_Indikator_22 : 6|2@1+ (1,0) [0|3] ""  TSG_Fahrer
 SG_ OpCode_22 : 13|3@1+ (1,0) [0|7] ""  TSG_Fahrer
 SG_ Module_ID_22 : 0|6@1+ (1,0) [0|63] ""  TSG_Fahrer
 SG_ Funktions_ID_22 : 8|5@1+ (1,0) [0|31] ""  TSG_Fahrer
 SG_ Data_Byte_5_22 : 56|8@1+ (1,0) [0|255] ""  TSG_Fahrer
 SG_ Data_Byte_4_22 : 48|8@1+ (1,0) [0|255] ""  TSG_Fahrer
 SG_ Data_Byte_3_22 : 40|8@1+ (1,0) [0|255] ""  TSG_Fahrer
 SG_ Data_Byte_2_22 : 32|8@1+ (1,0) [0|255] ""  TSG_Fahrer
 SG_ Data_Byte_1_22 : 24|8@1+ (1,0) [0|255] ""  TSG_Fahrer
 SG_ Controller_ID_22 : 16|4@1+ (1,0) [0|15] ""  TSG_Fahrer

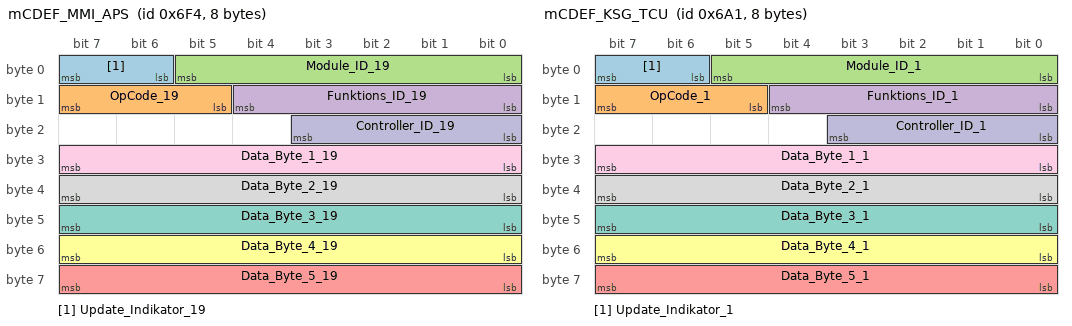
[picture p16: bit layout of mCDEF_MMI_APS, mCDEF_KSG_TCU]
BO_ 1780 mCDEF_MMI_APS: 8 Gateway_K
 SG_ Update_Indikator_19 : 6|2@1+ (1,0) [0|3] ""  Einparkhilfe
 SG_ OpCode_19 : 13|3@1+ (1,0) [0|7] ""  Einparkhilfe
 SG_ Module_ID_19 : 0|6@1+ (1,0) [0|63] ""  Einparkhilfe
 SG_ Funktions_ID_19 : 8|5@1+ (1,0) [0|31] ""  Einparkhilfe
 SG_ Data_Byte_5_19 : 56|8@1+ (1,0) [0|255] ""  Einparkhilfe
 SG_ Data_Byte_4_19 : 48|8@1+ (1,0) [0|255] ""  Einparkhilfe
 SG_ Data_Byte_3_19 : 40|8@1+ (1,0) [0|255] ""  Einparkhilfe
 SG_ Data_Byte_2_19 : 32|8@1+ (1,0) [0|255] ""  Einparkhilfe
 SG_ Data_Byte_1_19 : 24|8@1+ (1,0) [0|255] ""  Einparkhilfe
 SG_ Controller_ID_19 : 16|4@1+ (1,0) [0|15] ""  Einparkhilfe

BO_ 1697 mCDEF_KSG_TCU: 8 Komfort_SG
 SG_ Update_Indikator_1 : 6|2@1+ (1,0) [0|3] ""  Gateway_K
 SG_ OpCode_1 : 13|3@1+ (1,0) [0|7] ""  Gateway_K
 SG_ Module_ID_1 : 0|6@1+ (1,0) [0|63] ""  Gateway_K
 SG_ Funktions_ID_1 : 8|5@1+ (1,0) [0|31] ""  Gateway_K
 SG_ Data_Byte_5_1 : 56|8@1+ (1,0) [0|255] ""  Gateway_K
 SG_ Data_Byte_4_1 : 48|8@1+ (1,0) [0|255] ""  Gateway_K
 SG_ Data_Byte_3_1 : 40|8@1+ (1,0) [0|255] ""  Gateway_K
 SG_ Data_Byte_2_1 : 32|8@1+ (1,0) [0|255] ""  Gateway_K
 SG_ Data_Byte_1_1 : 24|8@1+ (1,0) [0|255] ""  Gateway_K
 SG_ Controller_ID_1 : 16|4@1+ (1,0) [0|15] ""  Gateway_K

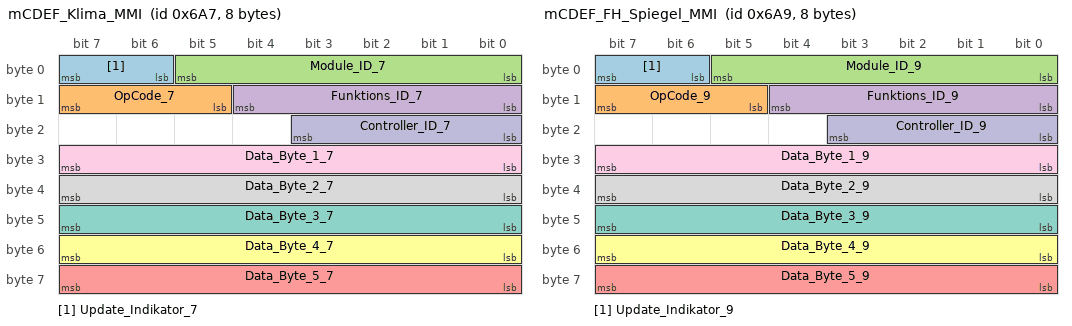
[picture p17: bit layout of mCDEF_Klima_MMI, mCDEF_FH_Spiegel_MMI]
BO_ 1703 mCDEF_Klima_MMI: 8 Clima
 SG_ Update_Indikator_7 : 6|2@1+ (1,0) [0|3] ""  Gateway_K
 SG_ OpCode_7 : 13|3@1+ (1,0) [0|7] ""  Gateway_K
 SG_ Module_ID_7 : 0|6@1+ (1,0) [0|63] ""  Gateway_K
 SG_ Funktions_ID_7 : 8|5@1+ (1,0) [0|31] ""  Gateway_K
 SG_ Data_Byte_5_7 : 56|8@1+ (1,0) [0|255] ""  Gateway_K
 SG_ Data_Byte_4_7 : 48|8@1+ (1,0) [0|255] ""  Gateway_K
 SG_ Data_Byte_3_7 : 40|8@1+ (1,0) [0|255] ""  Gateway_K
 SG_ Data_Byte_2_7 : 32|8@1+ (1,0) [0|255] ""  Gateway_K
 SG_ Data_Byte_1_7 : 24|8@1+ (1,0) [0|255] ""  Gateway_K
 SG_ Controller_ID_7 : 16|4@1+ (1,0) [0|15] ""  Gateway_K

BO_ 1705 mCDEF_FH_Spiegel_MMI: 8 TSG_Fahrer
 SG_ Update_Indikator_9 : 6|2@1+ (1,0) [0|3] ""  Gateway_K
 SG_ OpCode_9 : 13|3@1+ (1,0) [0|7] ""  Gateway_K
 SG_ Module_ID_9 : 0|6@1+ (1,0) [0|63] ""  Gateway_K
 SG_ Funktions_ID_9 : 8|5@1+ (1,0) [0|31] ""  Gateway_K
 SG_ Data_Byte_5_9 : 56|8@1+ (1,0) [0|255] ""  Gateway_K
 SG_ Data_Byte_4_9 : 48|8@1+ (1,0) [0|255] ""  Gateway_K
 SG_ Data_Byte_3_9 : 40|8@1+ (1,0) [0|255] ""  Gateway_K
 SG_ Data_Byte_2_9 : 32|8@1+ (1,0) [0|255] ""  Gateway_K
 SG_ Data_Byte_1_9 : 24|8@1+ (1,0) [0|255] ""  Gateway_K
 SG_ Controller_ID_9 : 16|4@1+ (1,0) [0|15] ""  Gateway_K

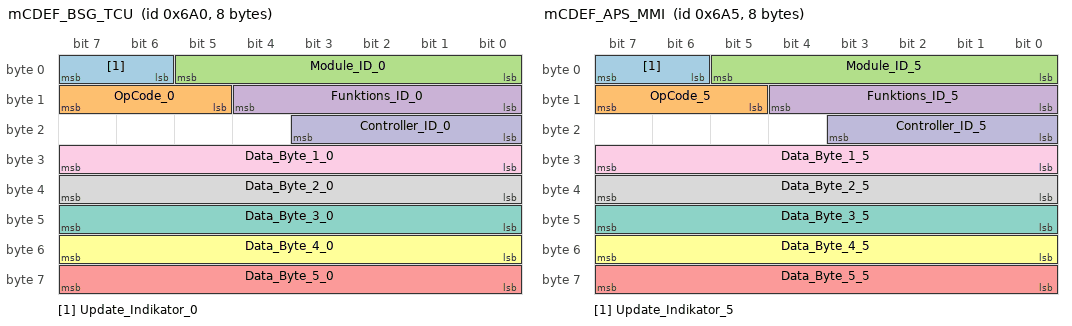
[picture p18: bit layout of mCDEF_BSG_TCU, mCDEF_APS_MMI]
BO_ 1696 mCDEF_BSG_TCU: 8 BSG
 SG_ Update_Indikator_0 : 6|2@1+ (1,0) [0|3] ""  Gateway_K
 SG_ OpCode_0 : 13|3@1+ (1,0) [0|7] ""  Gateway_K
 SG_ Module_ID_0 : 0|6@1+ (1,0) [0|63] ""  Gateway_K
 SG_ Funktions_ID_0 : 8|5@1+ (1,0) [0|31] ""  Gateway_K
 SG_ Data_Byte_5_0 : 56|8@1+ (1,0) [0|255] ""  Gateway_K
 SG_ Data_Byte_4_0 : 48|8@1+ (1,0) [0|255] ""  Gateway_K
 SG_ Data_Byte_3_0 : 40|8@1+ (1,0) [0|255] ""  Gateway_K
 SG_ Data_Byte_2_0 : 32|8@1+ (1,0) [0|255] ""  Gateway_K
 SG_ Data_Byte_1_0 : 24|8@1+ (1,0) [0|255] ""  Gateway_K
 SG_ Controller_ID_0 : 16|4@1+ (1,0) [0|15] ""  Gateway_K

BO_ 1701 mCDEF_APS_MMI: 8 Einparkhilfe
 SG_ Update_Indikator_5 : 6|2@1+ (1,0) [0|3] ""  Gateway_K
 SG_ OpCode_5 : 13|3@1+ (1,0) [0|7] ""  Gateway_K
 SG_ Module_ID_5 : 0|6@1+ (1,0) [0|63] ""  Gateway_K
 SG_ Funktions_ID_5 : 8|5@1+ (1,0) [0|31] ""  Gateway_K
 SG_ Data_Byte_5_5 : 56|8@1+ (1,0) [0|255] ""  Gateway_K
 SG_ Data_Byte_4_5 : 48|8@1+ (1,0) [0|255] ""  Gateway_K
 SG_ Data_Byte_3_5 : 40|8@1+ (1,0) [0|255] ""  Gateway_K
 SG_ Data_Byte_2_5 : 32|8@1+ (1,0) [0|255] ""  Gateway_K
 SG_ Data_Byte_1_5 : 24|8@1+ (1,0) [0|255] ""  Gateway_K
 SG_ Controller_ID_5 : 16|4@1+ (1,0) [0|15] ""  Gateway_K

BO_ 1136 mBSG_Kombi: 5 BSG
 SG_ BSK_Unterspannung : 15|1@1+ (1,0) [0|1] ""  Gateway_K
 SG_ BSK_Ruecks_HR_verriegelt : 35|1@1+ (1,0) [0|1] ""  Gateway_K
 SG_ BSK_Ruecks_HL_verriegelt : 34|1@1+ (1,0) [0|1] ""  Gateway_K
 SG_ BSK_Rueckfahrlicht : 5|1@1+ (1,0) [0|1] ""  Gateway_K
 SG_ BSK_NSL_LED_Pfad : 37|1@1+ (1,0) [0|1] ""  Gateway_K
 SG_ BSK_MH_geoeffnet : 12|1@1+ (1,0) [0|1] ""  Gateway_K
 SG_ BSK_Ladekontrollampe : 7|1@1+ (1,0) [0|1] ""  Multifunktions_SG,Gateway_K
 SG_ BSK_HR_geoeffnet : 11|1@1+ (1,0) [0|1] ""  Verdeck,Gateway_K
 SG_ BSK_HL_geoeffnet : 10|1@1+ (1,0) [0|1] ""  Verdeck,Gateway_K
 SG_ BSK_HD_Vorraste : 14|1@1+ (1,0) [0|1] ""  Multifunktions_SG,Verdeck,Gateway_K
 SG_ BSK_HD_Hauptraste : 13|1@1+ (1,0) [0|1] ""  Multifunktions_SG,Verdeck,Gateway_K
 SG_ BSK_FT_geoeffnet : 8|1@1+ (1,0) [0|1] ""  SitzMemo_Fahrer,Verdeck,Gateway_K
 SG_ BSK_Display_def : 23|1@1+ (1,0) [0|1] ""  Gateway_K
 SG_ BSK_Display : 16|7@1+ (1,0) [0|100] "%"  Gateway_K
 SG_ BSK_Def_Lampe : 36|1@1+ (1,0) [0|1] ""  Gateway_K
 SG_ BSK_BT_geoeffnet : 9|1@1+ (1,0) [0|1] ""  SitzMemo_Beifahrer,Verdeck,Gateway_K
 SG_ BSK_AFL_defekt : 38|1@1+ (1,0) [0|1] ""  Gateway_K

BO_ 1397 mBSG_3: 4 BSG
 SG_ BS3_LED_Sitze : 29|1@1+ (1,0) [0|1] ""  SitzMemo_Beifahrer,SitzMemo_Fahrer
 SG_ BS3_LED_Heckscheibe : 27|1@1+ (1,0) [0|1] ""  Clima
 SG_ BS3_LED_Frontscheibe : 28|1@1+ (1,0) [0|1] ""  Clima
 SG_ BS3_LED_Aussenspiegel : 30|1@1+ (1,0) [0|1] ""  TSG_Beifahrer,TSG_Fahrer
 SG_ BS3_Leaving_Home : 17|1@1+ (1,0) [0|1] ""  Gateway_K
 SG_ BS3_Ladekontrollampe : 7|1@1+ (1,0) [0|1] ""  PTC_Heizung,Clima,Gateway_K
 SG_ BS3_Klemme_X : 2|1@1+ (1,0) [0|1] ""  Reifendruck_VW,Multifunktions_SG,SitzMemo_Beifahrer,SitzMemo_Fahrer,Standheizung,Anhaenger_SG,Gateway_K
 SG_ BS3_Klemme_S : 0|1@1+ (1,0) [0|1] ""  Gateway_K
 SG_ BS3_Klemme_P : 4|1@1+ (1,0) [0|1] ""  Gateway_K
 SG_ BS3_Klemme_50 : 3|1@1+ (1,0) [0|1] ""  Reifendruck_VW,Multifunktions_SG,Anhaenger_SG,Gateway_K
 SG_ BS3_Klemme_15_Motorraum : 6|1@1+ (1,0) [0|1] ""  Gateway_K
 SG_ BS3_Klemme_15 : 1|1@1+ (1,0) [0|1] ""  Reifendruck_VW,Reifendruck_Audi,Multifunktions_SG,SMLS,SitzMemo_Beifahrer,SitzMemo_Fahrer,Einparkhilfe,Verdeck,PTC_Heizung,Standheizung,Clima,Anhaenger_SG,FHSG_hinten_rechts,FHSG_hinten_links,TSG_Beifahrer,TSG_Fahrer,Komfort_SG,Gateway_K
 SG_ BS3_KD_Fehler : 13|1@1+ (1,0) [0|1] ""  Gateway_K
 SG_ BS3_K_Luefter_ein : 18|1@1+ (1,0) [0|1] ""  Gateway_K
 SG_ BS3_Haubenkontakt : 15|1@1+ (1,0) [0|1] ""  Komfort_SG,Gateway_K
 SG_ BS3_Drehzahlanhebung : 8|1@1+ (1,0) [0|1] ""  Gateway_K
 SG_ BS3_Coming_Home : 16|1@1+ (1,0) [0|1] ""  Gateway_K
 SG_ BS3_Bordnetzbatt : 9|2@1+ (1,0) [0|3] ""  Standheizung,Gateway_K
 SG_ BS3_2_Drehzahl : 5|1@1+ (1,0) [0|1] ""  Gateway_K

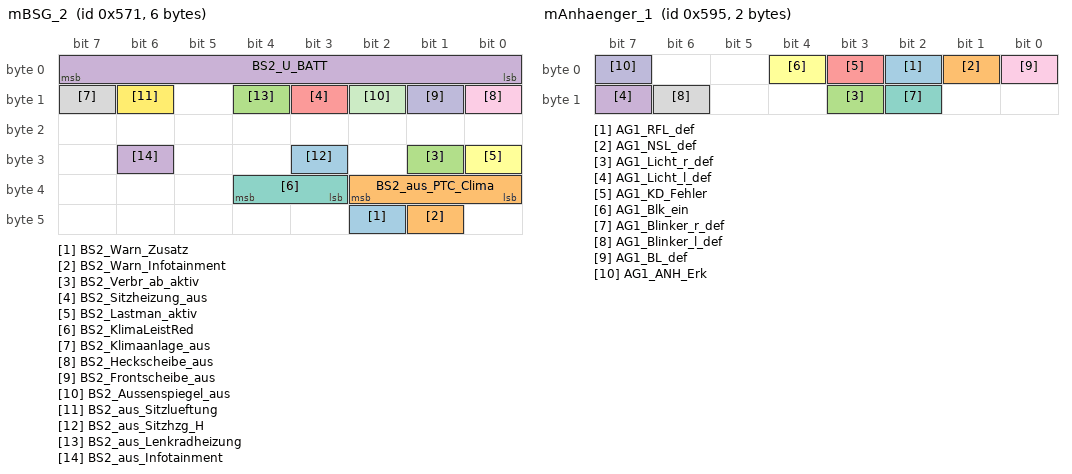
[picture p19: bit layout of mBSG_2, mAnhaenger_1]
BO_ 1393 mBSG_2: 6 BSG
 SG_ BS2_Warn_Zusatz : 42|1@1+ (1,0) [0|1] ""  Gateway_K
 SG_ BS2_Warn_Infotainment : 41|1@1+ (1,0) [0|1] ""  Gateway_K
 SG_ BS2_Verbr_ab_aktiv : 25|1@1+ (1,0) [0|1] ""  Clima
 SG_ BS2_U_BATT : 0|8@1+ (0.05,5) [5|17.7] "V"  Standheizung,Clima,Gateway_K
 SG_ BS2_Sitzheizung_aus : 11|1@1+ (1,0) [0|1] ""  SitzMemo_Beifahrer,SitzMemo_Fahrer,Clima,Gateway_K
 SG_ BS2_Lastman_aktiv : 24|1@1+ (1,0) [0|1] "" Vector__XXX
 SG_ BS2_KlimaLeistRed : 35|2@1+ (1,0) [0|3] "Tabelle"  Clima
 SG_ BS2_Klimaanlage_aus : 15|1@1+ (1,0) [0|1] ""  Clima,Gateway_K
 SG_ BS2_Heckscheibe_aus : 8|1@1+ (1,0) [0|1] ""  Clima,Gateway_K
 SG_ BS2_Frontscheibe_aus : 9|1@1+ (1,0) [0|1] ""  Clima,Gateway_K
 SG_ BS2_Aussenspiegel_aus : 10|1@1+ (1,0) [0|1] ""  TSG_Beifahrer,TSG_Fahrer,Gateway_K
 SG_ BS2_aus_Sitzlueftung : 14|1@1+ (1,0) [0|1] ""  SitzMemo_Fahrer,Gateway_K
 SG_ BS2_aus_Sitzhzg_H : 27|1@1+ (1,0) [0|1] "" Vector__XXX
 SG_ BS2_aus_PTC_Clima : 32|3@1+ (25,0) [0|100] "%"  PTC_Heizung,Clima
 SG_ BS2_aus_Lenkradheizung : 12|1@1+ (1,0) [0|1] ""  SMLS,Gateway_K
 SG_ BS2_aus_Infotainment : 30|1@1+ (1,0) [0|1] ""  Gateway_K

BO_ 1429 mAnhaenger_1: 2 Anhaenger_SG
 SG_ AG1_RFL_def : 2|1@1+ (1,0) [0|1] ""  BSG,Gateway_K
 SG_ AG1_NSL_def : 1|1@1+ (1,0) [0|1] ""  BSG,Gateway_K
 SG_ AG1_Licht_r_def : 11|1@1+ (1,0) [0|1] ""  BSG,Gateway_K
 SG_ AG1_Licht_l_def : 15|1@1+ (1,0) [0|1] ""  BSG,Gateway_K
 SG_ AG1_KD_Fehler : 3|1@1+ (1,0) [0|1] ""  BSG,Gateway_K
 SG_ AG1_Blk_ein : 4|1@1+ (1,0) [0|1] ""  Gateway_K
 SG_ AG1_Blinker_r_def : 10|1@1+ (1,0) [0|1] ""  BSG,Gateway_K
 SG_ AG1_Blinker_l_def : 14|1@1+ (1,0) [0|1] ""  BSG,Gateway_K
 SG_ AG1_BL_def : 0|1@1+ (1,0) [0|1] ""  BSG,Gateway_K
 SG_ AG1_ANH_Erk : 7|1@1+ (1,0) [0|1] ""  Einparkhilfe,BSG,Komfort_SG,Gateway_K

BO_ 337 mAirbag_1: 4 Gateway_K
 SG_ AB1_Systemfehler : 11|1@1+ (1,0) [0|1] "" Vector__XXX
 SG_ AB1_Stellglied : 17|1@1+ (1,0) [0|1] "" Vector__XXX
 SG_ AB1_Rollover : 4|1@1+ (1,0) [0|1] "" Vector__XXX
 SG_ AB1_Pruefsumme : 24|8@1+ (1,0) [0|255] "Tabelle"  BSG,Komfort_SG
 SG_ AB1_MessageZaehler : 20|4@1+ (1,0) [0|15] "Tabelle"  BSG,Komfort_SG
 SG_ AB1_KD_Fehler : 19|1@1+ (1,0) [0|1] "" Vector__XXX
 SG_ AB1_HeckCrash : 1|1@1+ (1,0) [0|1] "" Vector__XXX
 SG_ AB1_FTGurtwarnung : 13|1@1+ (1,0) [0|1] "" Vector__XXX
 SG_ AB1_FTGurtschalter : 12|1@1+ (1,0) [0|1] ""  SitzMemo_Fahrer
 SG_ AB1_FrontCrash : 0|1@1+ (1,0) [0|1] "" Vector__XXX
 SG_ AB1_Diagnose : 16|1@1+ (1,0) [0|1] "" Vector__XXX
 SG_ AB1_CrashStaerke : 5|3@1+ (1,0) [0|7] ""  Standheizung,BSG,FHSG_hinten_rechts,FHSG_hinten_links,TSG_Beifahrer,TSG_Fahrer,Komfort_SG
 SG_ AB1_Crash_FT : 2|1@1+ (1,0) [0|1] "" Vector__XXX
 SG_ AB1_Crash_BT : 3|1@1+ (1,0) [0|1] "" Vector__XXX
 SG_ AB1_BTGurtwarnung : 15|1@1+ (1,0) [0|1] "" Vector__XXX
 SG_ AB1_BTGurtschalter : 14|1@1+ (1,0) [0|1] "" Vector__XXX
 SG_ AB1_AirbagLampe_ein : 8|1@1+ (1,0) [0|1] "" Vector__XXX
 SG_ AB1_Airbag_deaktiviert : 9|1@1+ (1,0) [0|1] "" Vector__XXX

CM_ BO_ 1039 "
Byte 1:NM_Message
Byte 2:NM_Message
Byte 4:NM_WakeUp_Appl1";
CM_ SG_ 1039 NMSH_SleepInd "BusSleep Indication";
CM_ SG_ 1039 NMSH_SleepAck "BusSleep Acknowledge";
CM_ SG_ 1039 NMSH_SH_LED "Weckursache : Standheizung ein";
CM_ SG_ 1039 NMSH_Receiver "SG_Adresse";
CM_ SG_ 1039 NMSH_NWake "Weckursache: NWake-Eingang";
CM_ SG_ 1039 NMSH_Kl_30_Reset "Weckursache: Klemme 30 Reset";
CM_ SG_ 1039 NMSH_Funk "Weckursache: Funkempfang";
CM_ SG_ 1039 NMSH_Fkt_Nachlauf "Weckursache: Ablauf Timer Funktionsnachlauf";
CM_ SG_ 1039 NMSH_CmdRing "Ring Message";
CM_ SG_ 1039 NMSH_CmdLimpHome "Limp Home Message";
CM_ SG_ 1039 NMSH_CmdAlive "Alive Message";
CM_ SG_ 1039 NMSH_CAN "Weckursache: CAN";
CM_ BO_ 1033 "
Byte 1:NM_Message
Byte 2:NM_Message";
CM_ SG_ 1033 NMRK_SleepInd "BusSleep Indication";
CM_ SG_ 1033 NMRK_SleepAck "BusSleep Acknowledge";
CM_ SG_ 1033 NMRK_Receiver "SG_Adresse";
CM_ SG_ 1033 NMRK_NWake "Weckursache: NWake-Eingang";
CM_ SG_ 1033 NMRK_Kl_30_Reset "Weckursache: Klemme 30 Reset";
CM_ SG_ 1033 NMRK_Fkt_Nachlauf "Weckursache: Ablauf Timer Funktionsnachlauf";
CM_ SG_ 1033 NMRK_CmdRing "Ring Message";
CM_ SG_ 1033 NMRK_CmdLimpHome "Limp Home Message";
CM_ SG_ 1033 NMRK_CmdAlive "Alive Message";
CM_ SG_ 1033 NMRK_CAN "Weckursache: CAN";
CM_ BO_ 1038 "
Byte 1:NM_Message
Byte 2:NM_Message";
CM_ SG_ 1038 NMPTC_SleepInd "BusSleep Indication";
CM_ SG_ 1038 NMPTC_SleepAck "BusSleep Acknowledge";
CM_ SG_ 1038 NMPTC_Receiver "SG_Adresse /nEinparkhilfe";
CM_ SG_ 1038 NMPTC_NWake "Weckursache: NWake-Eingang";
CM_ SG_ 1038 NMPTC_Kl_30_Reset "Weckursache: Klemme 30 Reset";
CM_ SG_ 1038 NMPTC_Fkt_Nachlauf "Weckursache: Ablauf Timer Funktionsnachlauf";
CM_ SG_ 1038 NMPTC_CmdRing "Ring Message";
CM_ SG_ 1038 NMPTC_CmdLimpHome "Limp Home Message";
CM_ SG_ 1038 NMPTC_CmdAlive "Alive Message";
CM_ SG_ 1038 NMPTC_CAN "Weckursache: CAN";
CM_ BO_ 1050 "
Byte 1:NM_Message
Byte 2:NM_Message
Byte 4:NM_WakeUp_Appl1
Byte 5:NM_WakeUp_Appl1";
CM_ SG_ 1050 NMMFG_Warnblinker "Weckursache: Warnblinker";
CM_ SG_ 1050 NMMFG_Standlicht "Weckursache: Standlicht";
CM_ SG_ 1050 NMMFG_SleepInd "BusSleep Indication";
CM_ SG_ 1050 NMMFG_SleepAck "BusSleep Acknowledge";
CM_ SG_ 1050 NMMFG_Receiver "SG_Adresse /nMultifunktionssteuergeraet";
CM_ SG_ 1050 NMMFG_re_Parklicht "Weckursache: Parkhilfe rechts";
CM_ SG_ 1050 NMMFG_NWake "Weckursache: NWake-Eingang";
CM_ SG_ 1050 NMMFG_Lichthupe "Weckursache: Lichthupe";
CM_ SG_ 1050 NMMFG_li_Parklicht "Weckursache: Parklicht links";
CM_ SG_ 1050 NMMFG_Kl_30_Reset "Weckursache: Klemme 30 Reset";
CM_ SG_ 1050 NMMFG_Fkt_Nachlauf "Weckursache: Ablauf Timer Funktionsnachlauf";
CM_ SG_ 1050 NMMFG_Fernbedienung "Weckursache: Fernbedienug ein";
CM_ SG_ 1050 NMMFG_Fanfare "Weckursache: Taxi-Fanfare";
CM_ SG_ 1050 NMMFG_CmdRing "Ring Message";
CM_ SG_ 1050 NMMFG_CmdLimpHome "Limp Home Message";
CM_ SG_ 1050 NMMFG_CmdAlive "Alive Message";
CM_ SG_ 1050 NMMFG_CAN "Weckursache: CAN";
CM_ SG_ 1050 NMMFG_Blinkalarm "Weckursache: Taxi-Blinkalarm";
CM_ SG_ 1050 NMMFG_Bel_Innenraum "Weckursache: Bel. Innenraum";
CM_ SG_ 1050 NMMFG_Bel_Fussraum "Weckursache: Bel. Fussraum";
CM_ BO_ 1045 "
Byte 1:NM_Message
Byte 2:NM_Message";
CM_ SG_ 1045 NMMem_BF_SleepInd "BusSleep Indication";
CM_ SG_ 1045 NMMem_BF_SleepAck "BusSleep Acknowledge";
CM_ SG_ 1045 NMMem_BF_Receiver "SG_Adresse";
CM_ SG_ 1045 NMMem_BF_NWake "Weckursache: NWake-Eingang";
CM_ SG_ 1045 NMMem_BF_Kl_30_Reset "Weckursache: Klemme 30 Reset";
CM_ SG_ 1045 NMMem_BF_Fkt_Nachlauf "Weckursache: Ablauf Timer Funktionsnachlauf";
CM_ SG_ 1045 NMMem_BF_CmdRing "Ring Message";
CM_ SG_ 1045 NMMem_BF_CmdLimpHome "Limp Home Message";
CM_ SG_ 1045 NMMem_BF_CmdAlive "Alive Message";
CM_ SG_ 1045 NMMem_BF_CAN "Weckursache: CAN";
CM_ BO_ 1030 "
Byte 1:NM_Message
Byte 2:NM_Message
Byte 5:NM_WakeUp_Appl2";
CM_ SG_ 1030 NMMEM_SleepInd "BusSleep Indication";
CM_ SG_ 1030 NMMEM_SleepAck "BusSleep Acknowledge";
CM_ SG_ 1030 NMMEM_Receiver "SG_Adresse";
CM_ SG_ 1030 NMMEM_NWake "Weckursache: NWake-Eingang";
CM_ SG_ 1030 NMMEM_Memory_S "Weckursache: Memory Speichertaste betaetigt /nWeck";
CM_ SG_ 1030 NMMEM_Memory_P4 "Weckursache: Memory Positionstaster 4 betaetigt /n";
CM_ SG_ 1030 NMMEM_Memory_P3 "Weckursache: Memory Positionstaster 3 betaetigt /n";
CM_ SG_ 1030 NMMEM_Memory_P2 "Weckursache: Memory Positionstaster 2 betaetigt /n";
CM_ SG_ 1030 NMMEM_Memory_P1 "Weckursache: Memory Positionstaster 1 betaetigt /n";
CM_ SG_ 1030 NMMEM_Kl_30_Reset "Weckursache: Klemme 30 Reset";
CM_ SG_ 1030 NMMEM_Fkt_Nachlauf "Weckursache: Ablauf Timer Funktionsnachlauf";
CM_ SG_ 1030 NMMEM_CmdRing "Ring Message";
CM_ SG_ 1030 NMMEM_CmdLimpHome "Limp Home Message";
CM_ SG_ 1030 NMMEM_CmdAlive "Alive Message";
CM_ SG_ 1030 NMMEM_CAN "Weckursache: CAN";
CM_ BO_ 1035 "
Byte 1:NM_Message
Byte 2:NM_Message
Byte 4:NM_WakeUp_Appl1";
CM_ SG_ 1035 NMGW_K_SleepInd "BusSleep Indication";
CM_ SG_ 1035 NMGW_K_SleepAck "BusSleep Acknowledge";
CM_ SG_ 1035 NMGW_K_Receiver "SG_Adresse";
CM_ SG_ 1035 NMGW_K_MOST_Diag "Weckursache: MOST Diagnose";
CM_ SG_ 1035 NMGW_K_MOST "Weckursache:";
CM_ SG_ 1035 NMGW_K_Komfort "Weckursache: Komfort CAN";
CM_ SG_ 1035 NMGW_K_Kombi "Weckursache: Kombileitung";
CM_ SG_ 1035 NMGW_K_Klemme_15 "Weckursache: Klemme 15";
CM_ SG_ 1035 NMGW_K_Kl_30_Reset "Weckursache: Klemme 30 Reset";
CM_ SG_ 1035 NMGW_K_Infotainment "Weckursache: Infotainment CAN";
CM_ SG_ 1035 NMGW_K_Fkt_Nachlauf "Weckursache: Ablauf Timer Funktionsnachlauf";
CM_ SG_ 1035 NMGW_K_Diagnose "Weckursache: Diagnose CAN";
CM_ SG_ 1035 NMGW_K_CmdRing "Ring Message";
CM_ SG_ 1035 NMGW_K_CmdLimpHome "Limp Home Message";
CM_ SG_ 1035 NMGW_K_CmdAlive "Alive Message";
CM_ SG_ 1035 NMGW_K_CAN "Weckursache: CAN";
CM_ BO_ 1036 "
Byte 1:NM_Message
Byte 2:NM_Message
Byte 4:NM_WakeUp_Appl1";
CM_ SG_ 1036 NMCL_SleepInd "BusSleep Indication";
CM_ SG_ 1036 NMCL_SleepAck "BusSleep Acknowledge";
CM_ SG_ 1036 NMCL_Receiver "SG_Adresse";
CM_ SG_ 1036 NMCL_NWake "Weckursache: NWake-Eingang";
CM_ SG_ 1036 NMCL_Kl_30_Reset "Weckursache: Klemme 30 Reset";
CM_ SG_ 1036 NMCL_Fkt_Nachlauf "Weckursache: Ablauf Timer Funktionsnachlauf";
CM_ SG_ 1036 NMCL_ext_Standhzg "Weckursache: Klemme 15 = ein oder Standheizung";
CM_ SG_ 1036 NMCL_CmdRing "Ring Message";
CM_ SG_ 1036 NMCL_CmdLimpHome "Limp Home Message";
CM_ SG_ 1036 NMCL_CmdAlive "Alive Message";
CM_ SG_ 1036 NMCL_CAN "Weckursache: CAN";
CM_ BO_ 1024 "
Byte 1:NM_Message
Byte 2:NM_Message
Byte 4:NM_WakeUp_Appl1
Byte 5:NM_WakeUp_Appl2
Byte 6:NM_WakeUp_Appl3";
CM_ SG_ 1024 NMBS_Warnblinker "Weckursache: Warnblinkschalter";
CM_ SG_ 1024 NMBS_Standlicht "Weckursache: Standlichtschalter";
CM_ SG_ 1024 NMBS_SleepInd "BusSleep Indication";
CM_ SG_ 1024 NMBS_SleepAck "BusSleep Acknowledge";
CM_ SG_ 1024 NMBS_Signalhorn "Weckursache: Signalhorn betaetigt";
CM_ SG_ 1024 NMBS_Receiver "SG_Adresse";
CM_ SG_ 1024 NMBS_NWake "Weckursache: NWake-Eingang";
CM_ SG_ 1024 NMBS_MH_Kontakt "Weckursache: Motorhaubenkontakt";
CM_ SG_ 1024 NMBS_Lastman "Weckursache: Lastmanagementeingriff bei Unterspann";
CM_ SG_ 1024 NMBS_Klemme15 "Weckursache: Klemme 15 = ein /nnur mit Codierung";
CM_ SG_ 1024 NMBS_Kl_30_Reset "Weckursache: Klemme 30 Reset";
CM_ SG_ 1024 NMBS_HR_Drehfalle "Weckursache: Drehfalle Hinten Rechts";
CM_ SG_ 1024 NMBS_Home_Fkt "Weckursache: Coming/Leaving Home,Zustandsaenderung";
CM_ SG_ 1024 NMBS_HL_Drehfalle "Weckursache: Drehfalle Hinten Links";
CM_ SG_ 1024 NMBS_HD_Vorraste "Weckursache: Heckdeckel-Vorraste";
CM_ SG_ 1024 NMBS_HD_Innentaster "Weckursache: Heckdeckel-Innentaster";
CM_ SG_ 1024 NMBS_HD_Hauptraste "Weckursache: Heckdeckel-Hauptraste";
CM_ SG_ 1024 NMBS_HD_Grifftaster "Weckursache: Heckdeckel-Grifftaster";
CM_ SG_ 1024 NMBS_FT_Drehfalle "Weckursache: Drehfalle Fahrertuer";
CM_ SG_ 1024 NMBS_Fkt_Nachlauf "Weckursache: Ablauf Timer Funktionsnachlauf";
CM_ SG_ 1024 NMBS_Dimmsignal "Weckursache: Dimmsignal";
CM_ SG_ 1024 NMBS_CmdRing "Ring Message";
CM_ SG_ 1024 NMBS_CmdLimpHome "Limp Home Message";
CM_ SG_ 1024 NMBS_CmdAlive "Alive Message";
CM_ SG_ 1024 NMBS_CAN "Weckursache: CAN";
CM_ SG_ 1024 NMBS_BT_Drehfalle "Weckursache: Drehfalle Beifahrertuer";
CM_ SG_ 1024 NMBS_Bremslicht "Weckursache: Bremslichtschalter";
CM_ BO_ 1037 "
Byte 1:NM_Message
Byte 2:NM_Message";
CM_ SG_ 1037 NMAPS_SleepInd "BusSleep Indication";
CM_ SG_ 1037 NMAPS_SleepAck "BusSleep Acknowledge";
CM_ SG_ 1037 NMAPS_Receiver "SG_Adresse /nEinparkhilfe";
CM_ SG_ 1037 NMAPS_NWake "Weckursache: NWake-Eingang";
CM_ SG_ 1037 NMAPS_Kl_30_Reset "Weckursache: Klemme 30 Reset";
CM_ SG_ 1037 NMAPS_Fkt_Nachlauf "Weckursache: Ablauf Timer Funktionsnachlauf";
CM_ SG_ 1037 NMAPS_CmdRing "Ring Message";
CM_ SG_ 1037 NMAPS_CmdLimpHome "Limp Home Message";
CM_ SG_ 1037 NMAPS_CmdAlive "Alive Message";
CM_ SG_ 1037 NMAPS_CAN "Weckursache: CAN";
CM_ BO_ 1044 "
Byte 1:NM_Message
Byte 2:NM_Message";
CM_ SG_ 1044 NMANH_SleepInd "BusSleep Indication";
CM_ SG_ 1044 NMANH_SleepAck "BusSleep Acknowledge";
CM_ SG_ 1044 NMANH_Receiver "SG_Adresse /nAnhaenger-Steuergeraet";
CM_ SG_ 1044 NMANH_NWake "Weckursache: NWake-Eingang";
CM_ SG_ 1044 NMANH_Kl_30_Reset "Weckursache: Klemme 30 Reset";
CM_ SG_ 1044 NMANH_CmdRing "Ring Message";
CM_ SG_ 1044 NMANH_CmdLimpHome "Limp Home Message";
CM_ SG_ 1044 NMANH_CmdAlive "Alive Message";
CM_ SG_ 1044 NMANH_CAN "Weckursache: CAN";
CM_ SG_ 1044 NMANG_Fkt_Nachlauf "Weckursache: Ablauf Timer Funktionsnachlauf";
CM_ BO_ 1365 "
Byte 1:Status
Byte 2:Generatorlast
Byte 3:Hoeheninformation";
CM_ SG_ 1365 MO7_V_Begrenz "Geschwindigkeitsbegrenzung aktivierbar /n1 = Gesch";
CM_ SG_ 1365 MO7_V_Begr_akt "Geschwindigkeitsbegrenzung aktiv /n1 = Geschwindig";
CM_ SG_ 1365 MO7_Sleep_Ind "Sleep Indication /nDie Sleep-Bereitschaft wird nac";
CM_ SG_ 1365 MO7_Rueck_LLDz "Rueckmeldung_Leerlauf-Solldrehzahl 2 /nLeerlauf-So";
CM_ SG_ 1365 MO7_PTC "Status der Gluehstifte /nAusschaltinformation PTC-";
CM_ SG_ 1365 MO7_Oeltemperatur "ltemperatur /nrealer Meßbereich ca. -40..150 Grad";
CM_ SG_ 1365 MO7_LL_Status "Status der Leerlaufdrehzahl /nVergl. Motor 7 in An";
CM_ SG_ 1365 MO7_Hoeheninfo "Hoeheninformation /nFFh = Fehler, Korrekturfaktor";
CM_ SG_ 1365 MO7_Gradient_Vorz "Vorzeichen Motordrehzahlgradient /nPositiv steht f";
CM_ SG_ 1365 MO7_Gradient_Drehz "Motordrehzahlgradient /nDifferenz der Motordrehzah";
CM_ SG_ 1365 MO7_FehlerSp "Kundendienst Fehlerspeichereintrag im SG vorhanden";
CM_ SG_ 1365 MO7_DFM "Messwert DFM Signal (Generatorlast) /nFFh = Fehler";
CM_ BO_ 1473 "
Byte 1:Symbol
Byte 2:Drehwalze";
CM_ SG_ 1473 MLT_Symbol "Tastenzuordnung zum Symbolaufdruck /n'Code zugeord";
CM_ SG_ 1473 MLT_DW_VZ "Drehrichtungsanzeige /n'0=pos.=aufwaerts; 1=neg.=a";
CM_ SG_ 1473 MLT_DW_Ticks "Anzahl Drehwalzenticks /nEs wird die Anzahl der Wa";
CM_ BO_ 1475 "
Byte 1:Zieladresse
Byte 2:Funktionscode
Byte 3:Drehwalze";
CM_ SG_ 1475 ML1_Ziel "Zieladresse fuer das Tastensymbol /nZieladresse de";
CM_ SG_ 1475 ML1_DW_VZ "Drehrichtungsanzeige /n'0=pos.=aufwaerts; 1=neg.=a";
CM_ SG_ 1475 ML1_DW_Ticks "Anzahl Drehwalzenticks /nEs wird die Anzahl der Wa";
CM_ SG_ 1475 ML1_Befehl "Befehlscode /nByte analog zu MFT_Tasten, Byte1";
CM_ BO_ 889 "
Byte 1:Codierung MFG
Byte 2:Licht
Byte 3:Lenkstock 1
Byte 4:Lenkstock 2
Byte 5:Akustische Signale
Byte 6:Komfortfunktion
Byte 7:Zaehler, Motoreingriffe
Byte 8:Zaehler, Motoreingriffe";
CM_ SG_ 889 MG1_Zaehler "Botschaftszaehler /nBotschaftszaehler zur Erkennun";
CM_ SG_ 889 MG1_WischenStufe_2 "Frontwischergeschwindigkeit Stufe 2 /n0 = Wischen";
CM_ SG_ 889 MG1_WischenStufe_1 "Frontwischergeschwindigkeit Stufe 1 /n0 = Wischen";
CM_ SG_ 889 MG1_Warnblinker "Warnbllinker einschalten /n0 = Warnblinkmode aus;";
CM_ SG_ 889 MG1_Typ3 "Typcodierung Versehrten /n1 = Versehrtenfahrzeug";
CM_ SG_ 889 MG1_Typ2 "Typcodierung Fahrschule /n1 = Fahrschule";
CM_ SG_ 889 MG1_Typ1 "Typcodierung Taxi /n1 = Taxi";
CM_ SG_ 889 MG1_Typ0 "Typcodierung SoSi /n1 = Fahrzeug mit Sondersignala";
CM_ SG_ 889 MG1_Tipwischen "Tipwischen Frontwischer /n0 = Tipwischen aus ; 1 =";
CM_ SG_ 889 MG1_Summer "Summeransteuerung /n0 = Summer aus ; 1 = Summer an";
CM_ SG_ 889 MG1_Standlicht "Standlicht ein /n0 = Standlicht aus; 1 = Standlich";
CM_ SG_ 889 MG1_Signalhorn "Signalhorn aktiv (Hupe) /n0 = Signalhorn aus 1 = S";
CM_ SG_ 889 MG1_Parklicht_rechts "Parklicht rechts einschalten /n0 = Parklicht recht";
CM_ SG_ 889 MG1_Parklicht_links "Parklicht links einschalten /n0 = Parklicht links";
CM_ SG_ 889 MG1_Motorweiterlauf "Motorweiterlauf /n1 = Klemme 15 ein (Motorweiterla";
CM_ SG_ 889 MG1_Lichthupe "Lichthupe einschalten /n0 = Lichthupe nicht betaet";
CM_ SG_ 889 MG1_KD_Fehler "KD_Fehler /n1 = mindestens 1 Kundendienstfehlerein";
CM_ SG_ 889 MG1_Interm_Fernlicht "Intermetierendes Fernlicht ein /n0 = Fernlichtanst";
CM_ SG_ 889 MG1_Innenraumbel "Innenraumbeleuchtung einschalten /n0 = Innenraumbe";
CM_ SG_ 889 MG1_Heckwaschen "Heckwaschen einschalten /n0 = Heckwaschen aus ; 1";
CM_ SG_ 889 MG1_Heckintervall "Intervall Heckwischer /n0 = Heckwischer Intervall";
CM_ SG_ 889 MG1_Fussraumbel "Fussraumbeleuchtung einschalten /n0 = Fussraumbele";
CM_ SG_ 889 MG1_Frontwaschen "Frontwaschen einschalten /n0 = Frontwaschen aus ;";
CM_ SG_ 889 MG1_Frontintervall "Intervall Frontwischer /n0 = Frontwischer Interval";
CM_ SG_ 889 MG1_FH_FT_Tief "Fenster Fahrer manuell tief /n1 = Verstellung Fens";
CM_ SG_ 889 MG1_FH_FT_Hoch "Fenster Fahrer manuell hoch /n1 = Verstellung Fens";
CM_ SG_ 889 MG1_FH_BT_Tief "Fenster Beifahrer manuell tief /n1 = Verstellung F";
CM_ SG_ 889 MG1_FH_BT_Hoch "Fenster Beifahrer manuell hoch /n1 = Verstellung F";
CM_ SG_ 889 MG1_Fernlicht "Fernlicht einschalten /n0 = Fernlicht aus ; 1 = Fe";
CM_ SG_ 889 MG1_Fernbedienung "Fernbedienung ein /n0 = Lenkradfernbedienung inakt";
CM_ SG_ 889 MG1_Fahrlicht "Fahrlicht ein /n0 = Fahrlicht aus; 1 = Fahrlicht e";
CM_ SG_ 889 MG1_Checksumme "Pruefsumme /nPruefsumme, Definition im CAN-Lastenh";
CM_ SG_ 889 MG1_Blk_rechts "Blinker rechts einschalten /n0 = Blinker aus ; 1 =";
CM_ SG_ 889 MG1_Blk_links "Blinker links einschalten /n0 = Blinker aus ; 1 =";
CM_ SG_ 889 MG1_Anlasssperre "Anlasserbetaetigug sperren /n0 = Anlasser freigege";
CM_ SG_ 889 MG1_Anlasser "Fahrzeug starten /n0 = Anlasser aus; 1 = Anlasser";
CM_ SG_ 889 MG1_Alarm_Fanfare "Alarm aktiv (Fanfare) /n0 = Fanfare aus 1 = Fanfar";
CM_ SG_ 889 MG1_Alarm_Blinker "Alarm aktiv (Blinker) /n0 = Alarm Blinker aus 1 =";
CM_ BO_ 1317 "
Byte 1:SHL_Menue
Byte 2:SH_ZeitMenue";
CM_ SG_ 1317 SHM_SL "Standluefter ein /nStandlueftung explizit ein (Kun";
CM_ SG_ 1317 SHM_SH_SL "Standheizung/-Luefter ueber Timer/ Funk ein /nSign";
CM_ SG_ 1317 SHM_SH "Standheizung ein /nStandheizung explizit ein (Kund";
CM_ SG_ 1317 SHM_Restdauer "Einschaltdauer Standheizung / Standlueftung /n7F =";
CM_ SG_ 1317 SHM_MVW "Standheizung mit/ohne Motorvorwaermung /n0 = SH oh";
CM_ BO_ 1297 "
Byte 1:Memoryverstellung
Byte 2:Sitzheizung
Byte 4:Zusatzfunktion 2";
CM_ SG_ 1297 ME1_SP_MEM_Default "Neue Defaultposition fuer Spiegelabsenkung speiche";
CM_ SG_ 1297 ME1_Sitzhzg_Stat "Sitzheizung Einstellung Fahrer /nEine Abschaltung";
CM_ SG_ 1297 ME1_SG_Init "SG Initialisierung /n1 = SG in Initialisierungspha";
CM_ SG_ 1297 ME1_res_Sp_Abs "reserviert für Sitzpos. spezifische Spiegelabsenku";
CM_ SG_ 1297 ME1_Pos3 "Memory Position 3";
CM_ SG_ 1297 ME1_Pos2 "Memory Position 2";
CM_ SG_ 1297 ME1_Pos1 "Memory Position 1";
CM_ SG_ 1297 ME1_Pos_speichern "Memory Position speichern /n1 = Neue Sitzposition";
CM_ SG_ 1297 ME1_Pos_anfahren "Memory Position anfahren /n1 = Neue Sitzposition w";
CM_ SG_ 1297 ME1_KD_Fehler "Kundendienstfehler /n1 = mindestens 1 Kundendienst";
CM_ SG_ 1297 ME1_Funk_Tasten "Funk- bzw. Tastenzuordnung /n1 = gedrueckte Memory";
CM_ SG_ 1297 ME1_FFB_Pos3 "Zuordnung akt. Funkschluesselnummer zu Mem Pos 3 /";
CM_ SG_ 1297 ME1_FFB_Pos2 "Zuordnung akt. Funkschluesselnummer zu Mem Pos 2 /";
CM_ SG_ 1297 ME1_FFB_Pos1 "Zuordnung akt. Funkschluesselnummer zu Mem Pos 1 /";
CM_ SG_ 1297 ME1_Buzzer "Ansteuerung Buzzer";
CM_ SG_ 1297 ME1_Abb_Pos_anf "Abbruch Position anfahren /n1 = Abbruch des Anfahr";
CM_ BO_ 1301 "
Byte 1:Memoryverstellung
Byte 2:Sitzheizung Beifahrer";
CM_ SG_ 1301 MB1_Sitzhzg_Stat "Sitzheizung Einstellung Beifahrer /nEine Abschaltu";
CM_ SG_ 1301 MB1_Pos4 "Memory Position 4";
CM_ SG_ 1301 MB1_Pos3 "Memory Position 3";
CM_ SG_ 1301 MB1_Pos2 "Memory Position 2";
CM_ SG_ 1301 MB1_Pos1 "Memory Position 1";
CM_ SG_ 1301 MB1_Pos_speichern "Memory Position speichern";
CM_ SG_ 1301 MB1_Pos_anfahren "Memory Position anfahren";
CM_ SG_ 1301 MB1_KD_Fehler "Kundendienstfehler /n1 = mindestens 1 Kundendienst";
CM_ SG_ 1301 MB1_Buzzer "Ansteuerung Buzzer";
CM_ BO_ 705 "
Byte 1:Schaltersignale_1
Byte 2:Schaltersignale_2
Byte 3:Intervallstufen
Byte 4:Lenksaeulenverstellung
Byte 5:Zusatzsignale";
CM_ SG_ 705 LS1_WischenStufe_2 "Wischergeschwindigkeit Stufe 2";
CM_ SG_ 705 LS1_WischenStufe_1 "Wischergeschwindigkeit Stufe 1";
CM_ SG_ 705 LS1_Winterstellung "Winterstellung fuer Reversierwischeranlage /n1 = P";
CM_ SG_ 705 LS1_Tipwischen "Tipwischen ein";
CM_ SG_ 705 LS1_Signalhorn "Hupe ein";
CM_ SG_ 705 LS1_Servicestellung "Servicestellung /n1 = Positionierung der Wischerbl";
CM_ SG_ 705 LS1_Parklicht_rechts "Parklicht rechts ein";
CM_ SG_ 705 LS1_Parklicht_links "Parklicht links ein";
CM_ SG_ 705 LS1_MFL_vorhanden "Multifunktionslenkrad vorhanden /n1 = Multifunktio";
CM_ SG_ 705 LS1_MFA_vorhanden "MFA Tasten vorhanden /n1 = MFA-Schalter verbaut; 0";
CM_ SG_ 705 LS1_MFA_Tasten "Anzahl MFA Tasten /n0 = Init = 3 Tasten MFA- Schal";
CM_ SG_ 705 LS1_LSZ_zurueck "Lenksaeulenverstellung Z-";
CM_ SG_ 705 LS1_LSZ_vor "Lenksaeulenverstellung Z+";
CM_ SG_ 705 LS1_LSY_unten "Lenksaeulenverstellung Y-";
CM_ SG_ 705 LS1_LSY_oben "Lenksaeulenverstellung Y+";
CM_ SG_ 705 LS1_Lichthupe "Lichthupe ein";
CM_ SG_ 705 LS1_LHeizung_aktiv "Lenkradheizung ist eingeschaltet /nEine Abschaltun";
CM_ SG_ 705 LS1_KD_Fehler "Kundendienstfehler /n1 = mindestens ein Kundendien";
CM_ SG_ 705 LS1_Intervallstufen "Intervallstufen /nIntervallgeschwindigkeit / Regen";
CM_ SG_ 705 LS1_Intervall "Intervall oder Regensensorautomatik Frontwischer e";
CM_ SG_ 705 LS1_Heckwaschen "Wisch-Wasch hinten /n1 = Lenkstockschalter in Posi";
CM_ SG_ 705 LS1_Heckintervall "Intervall Heckwischer ein";
CM_ SG_ 705 LS1_Frontwaschen "Wisch-Wasch vorne /n1 = Lenkstockschalter in Posit";
CM_ SG_ 705 LS1_Fernlicht "Fernlicht ein";
CM_ SG_ 705 LS1_Easy_Entry_LS "Aktivierung Easy Entry Funktion der Lenksaeule /n1";
CM_ SG_ 705 LS1_Blk_rechts "Richtungsblinken rechts betaetigt (s. Gateway Komf";
CM_ SG_ 705 LS1_Blk_links "Richtungsblinken links betaetigt (s. Gateway Komfo";
CM_ SG_ 705 LS1_Bew_Frontwaschen "bewerte Wisch-Wasch Funktion vorne /n1 = Frontwasc";
CM_ SG_ 705 LS1_BC_Up_Cursor "Bordcomputer Cursor UP";
CM_ SG_ 705 LS1_BC_Reset "Bordcomputer Reset";
CM_ SG_ 705 LS1_BC_Down_Cursor "Bordcomputer Cursor Down";
CM_ BO_ 1585 "
Byte 1:Fehlermeldungen
Byte 2:Fehlermeldungen
Byte 3:Fehlermeldungen
Byte 4:Fehlermeldungen";
CM_ SG_ 1585 LI2_Standl_HR_def "Standlicht hinten rechts defekt /n1 = defekt";
CM_ SG_ 1585 LI2_Standl_HL_def "Standlicht hinten links defekt /n1 = defekt";
CM_ SG_ 1585 LI2_Rueckf_HR_def "Rueckfahrlicht hinten rechts defekt /n1 = defekt";
CM_ SG_ 1585 LI2_Rueckf_HL_def "Rueckfahrlicht hinten links defekt /n1 = defekt";
CM_ SG_ 1585 LI2_Parkl_VR_def "Parklicht vorne rechts defekt /n1 = defekt";
CM_ SG_ 1585 LI2_Parkl_VL_def "Parklicht vorne links defekt /n1 = defekt";
CM_ SG_ 1585 LI2_Nebel_VR_def "Nebellicht vorne rechts defekt /n1 = defekt";
CM_ SG_ 1585 LI2_Nebel_VL_def "Nebellicht vorne links defekt /n1 = defekt";
CM_ SG_ 1585 LI2_Nebel_HR_def "Nebelschlussleuchte rechts defekt /n1 = defekt";
CM_ SG_ 1585 LI2_Nebel_HL_def "Nebelschlussleuchte links defekt /n1 = defekt";
CM_ SG_ 1585 LI2_Kurv_R_Licht_def "Kurvenausleuchtung rechts defekt /n1 = defekt";
CM_ SG_ 1585 LI2_Kurv_L_Licht_def "Kurvenausleuchtung links defekt /n1 = defekt";
CM_ SG_ 1585 LI2_Kennzl_def "Kennzeichenbeleuchtung defekt /n1 = defekt";
CM_ SG_ 1585 LI2_Fernl_VR_def "Fernlicht vorne rechts defekt /n1 = defekt";
CM_ SG_ 1585 LI2_Fernl_VL_def "Fernlicht vorne links defekt /n1 = defekt";
CM_ SG_ 1585 LI2_Bremsl_HR_def "Bremsleuchte hinten rechts defekt (s. Gateway Komf";
CM_ SG_ 1585 LI2_Bremsl_HL_def "Bremsleuchte hinten links defekt (s. Gateway Komfo";
CM_ SG_ 1585 LI2_Blk_VR_def "Blinker vorne rechts defekt /n1 = defekt";
CM_ SG_ 1585 LI2_Blk_VL_def "Blinker vorne links defekt /n1 = defekt";
CM_ SG_ 1585 LI2_Blk_Seite_R_def "Seitenblinker rechts defekt /n1 = defekt";
CM_ SG_ 1585 LI2_BLk_Seite_L_def "Seitenblinker links defekt /n1 = defekt";
CM_ SG_ 1585 LI2_Blk_HR_def "Blinker hinten rechts defekt /n1 = defekt";
CM_ SG_ 1585 LI2_Blk_HL_def "Blinker hinten links defekt /n1 = defekt";
CM_ SG_ 1585 LI2_Abblend_VR_def "Abblendlicht vorne rechts defekt /n1 = defekt";
CM_ SG_ 1585 LI2_Abblend_VL_def "Abblendlicht vorne links defekt /n1 = defekt";
CM_ SG_ 1585 LI2_3Bremsl_def "3.Bremsleuchte defekt (s. Gateway Komfort 1) /n1 =";
CM_ BO_ 1329 "
Byte 1:Licht
Byte 2:Blinker und andere
Byte 3:Zaehler, Kontroll, sonst
Byte 4:Checksumme";
CM_ SG_ 1329 LIA_Zaehler "Botschaftszaehler zur Lebenderkennung /nDefinition";
CM_ SG_ 1329 LIA_Warnblk_Status "Statische Anzeige Warnblinklicht ist eingeschaltet";
CM_ SG_ 1329 LIA_Warnblink "Warnblinklampe ein /n'1 = Warnblinkmode; dynamisch";
CM_ SG_ 1329 LIA_Tagesfahrlicht "Tagesfahrlicht ist eingeschaltet /n1 = Tagesfahrli";
CM_ SG_ 1329 LIA_Standlicht "Kl58, Standlicht ein /n'Vorsicht Sleep-Mode!; Acht";
CM_ SG_ 1329 LIA_Rueckfahrlicht "Rueckfahrlicht ein /n1 = Rueckfahrlicht ein";
CM_ SG_ 1329 LIA_Pruefsumme "Pruefsumme gem. Lastenheft /nDefinition gemaess La";
CM_ SG_ 1329 LIA_Parklicht_rechts "Parklicht rechts ein /n1 = Parklicht rehts eingesh";
CM_ SG_ 1329 LIA_Parklicht_links "Parklicht links ein /n1 = Parklicht links eingesha";
CM_ SG_ 1329 LIA_Nebelschluss "Kl83b Nebelschlussleuchte ein /n1 = Nebelschlussli";
CM_ SG_ 1329 LIA_Nebellicht "Kl83a Nebellicht ein /n1 = Nebelscheinwerfer einge";
CM_ SG_ 1329 LIA_Fernlicht "Kl56a Fernlicht ein /nBit 0 ... 7 : 1 = Licht ein";
CM_ SG_ 1329 LIA_Blk_rechts "Blinklampe rechts ein /n1 = Blinker ein; 0 = Blink";
CM_ SG_ 1329 LIA_Blk_R_Kontrolle "Ansteuerung Blinkerkontrollampe rechts /n'1 = Kont";
CM_ SG_ 1329 LIA_Blk_links "Blinklampe links ein /n1 = Blinker ein; 0 = Blinke";
CM_ SG_ 1329 LIA_Blk_L_Kontrolle "Ansteuerung Blinkerkontrollampe links /n'1 = Kontr";
CM_ SG_ 1329 LIA_BLK_Frequenz "Blinkfrequenz /n1 = Blinkfrequenz der Blinker";
CM_ SG_ 1329 LIA_Anhaenger "Anhaengerblinklampe ein /n'1 = Anhaengerbetrieb; d";
CM_ SG_ 1329 LIA_AFL_Schalter "Schalter in Stellung Assistenzfahrlicht /n1 = Scha";
CM_ SG_ 1329 LIA_Abblendlicht "Kl56b Abblendlicht ein /nStatusmeldungen fuer Anze";
CM_ BO_ 963 "
Byte 1:Lenkradwinkel
Byte 3:Geschwindigkeit
Byte 5:Lenkwinkel_ID
Byte 6:Status Zaehler
Byte 7:Kodierdaten
Byte 8:Pruefsumme";
CM_ SG_ 963 LW1_Zaehler "Botschaftszaehler zur Lebenderkennung /nfreilaufen";
CM_ SG_ 963 LW1_Vorzeichen "Vorzeichen Lenkradwinkel /n0 = positiver Lenkradwi";
CM_ SG_ 963 LW1_Quelle_Init "Quelle fuer Init /n0 = Information aus Bremse 3 Bo";
CM_ SG_ 963 LW1_Pruefsumme "Pruefsumme gem. Lastenheft /nDefinition gemaess La";
CM_ SG_ 963 LW1_Lenkradwinkel "Lenkwinkel /nLow Byte 1, High Byte 2 ; 0 geradeaus";
CM_ SG_ 963 LW1_Kodierdaten "Kodierdaten /nMultiplex-Ausgabe der 3 Kodierbytes";
CM_ SG_ 963 LW1_KL30_Ausfall "Ausfall Klemme 30 /n(z.Zt. nur Kostal-Sensor); 1 =";
CM_ SG_ 963 LW1_Int_Status "Interner Status /n00 o.k. ; 01 no init ; 10 sporad";
CM_ SG_ 963 LW1_ID "Lenkwinkel ID /n0 = noch nicht kalibriet, Nullpunk";
CM_ SG_ 963 LW1_Geschwindigkeit "Lenkwinkelgeschwindigkeit /nLow Byte 3, High Byte";
CM_ SG_ 963 LW1_Geschw_Vorzeichen "Vorzeichen Geschwindigkeit /n0 = positiv; 1 = nega";
CM_ BO_ 961 "
Byte 1:Lastinformation
Byte 2:Statusmeldungen
Byte 4:Notlauf
Byte 5:Unterstuetzungsleistung";
CM_ SG_ 961 LH1_Welligkeit "Bordnetzwelligkeit /nIndikator Bordnetzwelligkeit";
CM_ SG_ 961 LH1_Unterst_Leist "Unterstuetzungsleistung /n0% = keine Unterstuetzun";
CM_ SG_ 961 LH1_Unterspannung "Notlauf Unterspannung /n1 = Versorgungsspannung Le";
CM_ SG_ 961 LH1_Uebertemperatur "Notlauf Uebertemperatur /n1 = Interne Temperaturse";
CM_ SG_ 961 LH1_Ueberspannung "Notlauf Ueberspannung /n1 = Versorgungsspannung Le";
CM_ SG_ 961 LH1_Textbits "Textbits fuer Kombi /n0 = kein Text; 1 = Text 1; 2";
CM_ SG_ 961 LH1_Sleep_Indication "Schlafbereitschaft im CAN-Antrieb /n1 = CAN wird n";
CM_ SG_ 961 LH1_Sensorik "Notlauf Sensorik /n1 = Interne Sensorik (z.B. Mome";
CM_ SG_ 961 LH1_NL_Res "Notlauf Reserviert /n1 = Reserviert";
CM_ SG_ 961 LH1_Motor "Notlauf Servo Motor /n1 = Defekt am Lenkhilfe-Serv";
CM_ SG_ 961 LH1_Lastinfo "Lastinformation Lenkhilfe /nreale Auflösung z. Zt.";
CM_ SG_ 961 LH1_KD_Fehler "Kundendienstfehler im SG vorhanden /n1 = mindesten";
CM_ SG_ 961 LH1_gueltig_Wellig "Bordnetzwelligkeit gültig /nIst der Wert der Bordn";
CM_ SG_ 961 LH1_gueltig_Batt_ab "Batterie-Ab gültig /nIst das Flag 'Batterie ab' un";
CM_ SG_ 961 LH1_Fehlerlampe "Fehlerlampe Lenkhilfe /n1 = Lampe ein (direkte Ste";
CM_ SG_ 961 LH1_Fehler_Lastinfo "Fehlerstatus Lastinformation /n1 = Fehlerwert oder";
CM_ SG_ 961 LH1_ECU_intern "Notlauf ECU Intern /n1 = Steuergeraeteinterner Def";
CM_ SG_ 961 LH1_Diag "EPS Diagnosemode /n0 = nicht aktiv; 1= aktiv, Anze";
CM_ SG_ 961 LH1_CAN_Schnittstelle "Notlauf CAN-Schnittstelle /n1 = Die notwendigen Da";
CM_ SG_ 961 LH1_Batterie_ab "Batterie-Ab /nDie Analyse der Bordnetzspannung erm";
CM_ SG_ 961 LH1_Akustiksig "Akustiksignal /n0 = Akustiksignal nicht aktiv; 1 =";
CM_ BO_ 1569 "
Byte 1:Kombi_Status
Byte 2:Kombi_Status
Byte 4:Kombi_Status
Byte 5:Schluesselinfo";
CM_ SG_ 1569 KO1_WFS_Schluessel "Schluesselinformation (s. Kombi_3) /n0 = ungueltig";
CM_ SG_ 1569 KO1_WaschWasser "Waschwasser Warnung /n1 = Waschwasserstand zu nied";
CM_ SG_ 1569 KO1_Tankwarnung "Tankwarnung (s. Kombi_1) /nOBD-Schwelle (z.Zt. 15%";
CM_ SG_ 1569 KO1_Tankwarnlampe "Tankwarnlampe ein (s. Kombi_1, Byte 1, Bit 6) /n1";
CM_ SG_ 1569 KO1_Tankstop "Tankstop erkannt (s. Kombi_1, Byte 2, Bit 7) /n'Bo";
CM_ SG_ 1569 KO1_Tankinhalt "Tankinhalt (s. Kombi_1) /nRestmenge 2 bzw. 2,5l ni";
CM_ SG_ 1569 KO1_Standzeit_Fehler "Standzeit Fehlerstatus (s. Kombi_3, Byte 5, Bit 7)";
CM_ SG_ 1569 KO1_Standzeit "Standzeit (s. Kombi_3) /n'Low Byte 2, High Byte 3;";
CM_ SG_ 1569 KO1_Handbremse "Zustand der Handbremse /n1 = Handbremse festgestel";
CM_ BO_ 1501 "
Byte 1:TIG_Beleuchtung
Byte 2:Fuss_Beleuchtung
Byte 3:Ausstieg_Beleuchtung
Byte 4:Umfeld_Beleuchtung";
CM_ SG_ 1501 IL1_Kl_30G "Klemme 30 geschaltet /n'geschaltete Klemme 30 fuer";
CM_ SG_ 1501 IL1_Funktionsanzeige "Freigabe Funktionsanzeige in den Bedientastern /n1";
CM_ SG_ 1501 IL1_Bel_Umfeld "Umfeldbeleuchtung, Tueraussengriff /nIntensitaet d";
CM_ SG_ 1501 IL1_Bel_Innengriff_Tuer "Tuerinnengriff /nIntensitaet der TIG - 0-aus / 255";
CM_ SG_ 1501 IL1_Bel_HR_Ausstieg "Tuerausstieg & Rueckstrahler hinten rechts /n1 = E";
CM_ SG_ 1501 IL1_Bel_HL_Ausstieg "Tuerausstieg & Rueckstrahler hinten links /n1 = Ei";
CM_ SG_ 1501 IL1_Bel_Fussraum "Fussraumbeleuchtung /nIntensitaet der Fussraumbelu";
CM_ SG_ 1501 IL1_Bel_FT_Ausstieg "Tuerausstieg & Rueckstrahler Fahrer /n1 = Ein";
CM_ SG_ 1501 IL1_Bel_BT_Ausstieg "Tuerausstieg & Rueckstrahler Beifahrer /n1 = Ein";
CM_ BO_ 859 "
Byte 1:Veraltetet Informationen
Byte 2:Motordrehzahl
Byte 4:Kuehlmitteltemperatur
Byte 5:Motorsignale
Byte 6:Kuehlerluefter
Byte 7:Motorsignale 2";
CM_ SG_ 859 GWM_Motordrehzahl "Motordrehzahl (s. Motor 1) /n'Byte 3 = FF = Fehler";
CM_ SG_ 859 GWM_Kuppl_Schalter "Kupplungsschalter (s. Motor 1) /n'1 = Schalter sag";
CM_ SG_ 859 GWM_KuehlmittelTemp "Kuehlmitteltemperatur (s. Motor 2 ) /n'FF = Fehler";
CM_ SG_ 859 GWM_Komp_Leist_red "Leistungsreduzierung des Kompressors (s. Motor 5)";
CM_ SG_ 859 GWM_KLuefter "Kuehlerluefteransteuerung ( s. Motor 5 ) /nIstzust";
CM_ SG_ 859 GWM_Klimaabschaltung "Klimaabschaltung (s. Motor 5) /n1 = Motor fordert";
CM_ SG_ 859 GWM_Kennfeldkuehlung "Kennfeldkuehlung (s. Motor 5) /n1 = Kennfeldkuehlu";
CM_ SG_ 859 GWM_Heissl_Vorwarn "Heissleuchtenvorwarnung (s. Motor 5, 6/0) /n1 = He";
CM_ SG_ 859 GWM_GRA_Status "GRA_Status (s. Motor 2, 3/6)) /n00 steht auch für";
CM_ SG_ 859 GWM_Fehl_KmittelTemp "Fehlerstatus Kuehlmitteltemperatur (s. Motor 2) /n";
CM_ SG_ 859 GWM_Bremstest_Schalter "Bremstestschalter (s. Motor 2) /n'1 = Bremse betae";
CM_ SG_ 859 GWM_Bremslicht_Schalter "Bremslichtschalter (s. Motor 2) /n1 = Bremse betae";
CM_ SG_ 859 GWM_Anl_Freigabe "Anlasser Freigabe (s. Motor 5) /n'0 = Start nicht";
CM_ SG_ 859 GWM_Anl_Ausspuren "Anlasser ausspuren (s. Motor 5) /n'0 = Motor läuft";
CM_ SG_ 859 GWM_Alt_5_Motor "veraltete Signale aus Botschsaft Motor 5";
CM_ SG_ 859 GWM_Alt_2_Motor "veraltete Signale aus Botschsaft Motor 2 /n1 = Feh";
CM_ SG_ 859 GWM_Alt_1_Motor "veraltete Signale aus Botschsaft Motor 1 /n1 = Feh";
CM_ BO_ 1319 "
Byte 1:Fehlerbits Gateway
Byte 6:Aussentemperatur_gefiltert
Byte 7:Aussentemperatur_ungefiltert
Byte 8:Kombi Signale";
CM_ SG_ 1319 GWK_Umfang_Reifen "mittlerer Reifenumfang (S. Kombi 3) /nMittlerer Re";
CM_ SG_ 1319 GWK_AussenTemp_ungefiltert "Aussentemperatur ungefiltert (s. Kombi 2) /n'FF =";
CM_ SG_ 1319 GWK_AussenTemp_gefiltert "Aussentemperatur gefiltert (s. Kombi 2) /n'FF = Fe";
CM_ SG_ 1319 GWK_AussenTemp_Fehler "Fehlerbit Aussentemperatur (s. Kombi 2) /n1 = Fehl";
CM_ SG_ 1319 GWK_Alt_3_Kombi "veraltete Signale aus Botschaft Kombi 3 /n1 = Wert";
CM_ SG_ 1319 GWK_Alt_2_Kombi "veraltete Signale aus Botschaft Kombi 2";
CM_ BO_ 857 "
Byte 1:Fehlerbits Gateway
Byte 2:Fahrzeuggeschwindigkeit
Byte 4:Wegstreckensignal
Byte 6:Bremse 2
Byte 8:Waehlhebelposition";
CM_ SG_ 857 GWB_Wegimpulse_Fehler "Fehlerbit Wegimpulse (s. Bremse 2) /n1 = Fehler, w";
CM_ SG_ 857 GWB_Wegimpulse "Wegimpulse (s. Bremse 2) /n'(Low Byte 4; High Byte";
CM_ SG_ 857 GWB_Wegimpuls_Status "Wegimpulszaehler-Status (s. Bremse 2) /n'1 = minde";
CM_ SG_ 857 GWB_Shift_Lock "Shift-Lock Lampe (s. Getriebe_2) /n1 = Shift lock";
CM_ SG_ 857 GWB_Schlechtweg_Fehler "Fehlerbit Schlechtweginfo (s. Bremse 1) /n1 = Schl";
CM_ SG_ 857 GWB_Schlechtweg "Schechtweginformation (s. Bremse 1) /n1 = Schlecht";
CM_ SG_ 857 GWB_Schaltvorgang "Getriebe schaltet (s. Getriebe 1) /n1 = Schaltung";
CM_ SG_ 857 GWB_res_Richtung "Reserviert fuer Richtungserkennungsbit";
CM_ SG_ 857 GWB_Info_Waehlhebel "Waehlhebelinfo (s. Getriebe_1) /n'0=Zwischenstellu";
CM_ SG_ 857 GWB_Impulszahl "Zaehnezahl des verwendeten Impulsrades (Bremse 2)";
CM_ SG_ 857 GWB_Geschw_Ersatz "Geschwindigkeitsersatzwert, auch Ersatzwert Wegstr";
CM_ SG_ 857 GWB_FzgGeschw_Quelle "Signalquelle FzgGeschw. (s. Bremse 1 bzw. Kombi 1)";
CM_ SG_ 857 GWB_FzgGeschw "Fzg.-Geschwindigkeit (s. Bremse1 bzw. Kombi 1) /n'";
CM_ SG_ 857 GWB_Alt_FzgGeschw "Fahrzeuggeschwindigkeit veraltet /n1 = Wert veralt";
CM_ SG_ 857 GWB_Alt_2_Getriebe "veraltete Signale aus Botschaft Getriebe 2";
CM_ SG_ 857 GWB_Alt_2_Bremse "veraltete Signale aus Botschaft Bremse 2 ( Byte 4";
CM_ SG_ 857 GWB_Alt_1_Getriebe "veraltete Signale aus Botschaft Getriebe 1 /n1 = W";
CM_ SG_ 857 GWB_Alt_1_Bremse "veraltete Signale aus Botschaft Bremse 1 (Byte 7)";
CM_ SG_ 857 GWB_ABS_Bremsung "Antiblockiersystem bremst (s. Bremse1) /n1 = ABS B";
CM_ BO_ 649 "
Byte 1:Checksumme
Byte 2:GRA_ADR_Schalter_1
Byte 4:Distanz_Tiptronic";
CM_ SG_ 649 GR2_Zaehler "Botschaftszaehler /nBotschaftszaehler zur Erkennun";
CM_ SG_ 649 GR2_Typ_Hauptschalter "Typ GRA Haupt-schalter/-taster /n0 = Hauptschalter";
CM_ SG_ 649 GR2_Tip_Verzoegern "GRA_ADR_Tipschalter_Verzoegern betaetigt, KurzTip-";
CM_ SG_ 649 GR2_Tip_Up "Tiptronic Bedienung Up, Tiptronik-Tip-Up /n0 = Tas";
CM_ SG_ 649 GR2_Tip_Fehler "Fehler Tiptronic Bedienteil /n1 = Fehler im Tiptro";
CM_ SG_ 649 GR2_Tip_Down "Tiptronic Bedienung Down, Tiptronik-Tip-Down /n0 =";
CM_ SG_ 649 GR2_Tip_Beschleunigen "GRA_ADR_Tipschalter_Beschleunigen betaetigt, KurzT";
CM_ SG_ 649 GR2_Tip_aus_GRA "GRA_ADR_Tippschalter _aus betaetigt, Abbrechen /n'";
CM_ SG_ 649 GR2_Sendercodierung "GRA_ADR_Sendercodierung /n'00: Sender = Bordnetz-S";
CM_ SG_ 649 GR2_Kodierinfo "Kodierinfo SMLS /n0 = GRA, 1 = ACC";
CM_ SG_ 649 GR2_Hauptschalter_ein "GRA_ADR_Hauptschalter eingeschaltet /n'1 = GRA-Hau";
CM_ SG_ 649 GR2_Checksumme "Pruefsumme /nPruefsumme, Definition im CAN-Lastenh";
CM_ SG_ 649 GR2_Bedienteil_Fehler "GRA_ADR_Fehler Bedienteil /n1 = Fehler im Bediente";
CM_ BO_ 1619 "
Byte 1:Laendervariante
Byte 2:Sprachvariante
Byte 3:Motorinfo";
CM_ SG_ 1619 GW3_Sprachvariante "Sprachvariante (s. Kombi_3) /n'0 = keine Sprachvar";
CM_ SG_ 1619 GW3_Motortyp "Motortyp (s. Motor_5) /n'Bit5: 0=Otto/1=Diesel; Bi";
CM_ SG_ 1619 GW3_Laendervariante "Laendervariante (s. Kombi_3) /n'0 = Deutschland; 1";
CM_ BO_ 1631 "
Byte 1:MUX
Byte 2:Data_1
Byte 3:Data_2
Byte 4:Data_3
Byte 5:Data_4
Byte 6:Data_5
Byte 7:Data_6
Byte 8:Data_7";
CM_ SG_ 1631 FI1_MUX "Multiplexbyte zur Datenbyteszuordnung /nMultiplexb";
CM_ SG_ 1631 FI1_Data7 "Fahrgestellnummer: Datenbytes je nach Multiplexinf";
CM_ SG_ 1631 FI1_Data6 "Fahrgestellnummer: Datenbytes je nach Multiplexinf";
CM_ SG_ 1631 FI1_Data5 "Fahrgestellnummer: Datenbytes je nach Multiplexinf";
CM_ SG_ 1631 FI1_Data4 "Fahrgestellnummer: Datenbytes je nach Multiplexinf";
CM_ SG_ 1631 FI1_Data3 "Fahrgestellnummer: Datenbytes je nach Multiplexinf";
CM_ SG_ 1631 FI1_Data2 "Fahrgestellnummer: Datenbytes je nach Multiplexinf";
CM_ SG_ 1631 FI1_Data1 "Fahrgestellnummer: Datenbytes je nach Multiplexinf";
CM_ BO_ 1550 "
Byte 1:Einheitenwahl
Byte 2:Personalisierung";
CM_ SG_ 1550 EH1_Profil "Profilnummer /naktuelle Profilnummer";
CM_ SG_ 1550 EH1_Einh_Vol "Einheit_Volumen ( liter / gallons) /n'0=liter ; 1";
CM_ SG_ 1550 EH1_Einh_Verbr "Einheit Verbrauchsanzeige ( Vol./Strecke ; Strecke";
CM_ SG_ 1550 EH1_Einh_Temp "Einheit Temperaturanzeige ( °C / °F ) /n'0 = °C; 1";
CM_ SG_ 1550 EH1_Einh_Strck "Einheit Streckenanzeige (km/mls) /n'0 = km; 1 = ml";
CM_ SG_ 1550 EH1_Einh_Druck "Einheit Druck (bar/psi) /n0 = Druckangabe in bar;";
CM_ BO_ 1583 "
Byte 1:Status_Bedienung
Byte 2:Anzeigebereich1
Byte 3:Anzeigebereich2
Byte 4:Anzeigebereich3";
CM_ SG_ 1583 DY1_Reset "Display Reset ist erfolgt /n1 = Anzeige wurde rese";
CM_ SG_ 1583 DY1_Global_Reset "Reset aller DDP-Teilnehmer gefordert /n1 = Zurueck";
CM_ SG_ 1583 DY1_Display_OK "Display ist betriebsbereit /n1 = Diplay ist bereit";
CM_ SG_ 1583 DY1_Bereich3 "Displaybereich Nr. 3 /nBelegung des Displaybereich";
CM_ SG_ 1583 DY1_Bereich2 "Displaybereich Nr. 2 /nBelegung des Displaybereich";
CM_ SG_ 1583 DY1_Bereich1 "Displaybereich Nr. 1 /nBelegung des Displaybereich";
CM_ BO_ 1589 "
Byte 1:Klemme_58d (Display)
Byte 2:Klemme_58s (Schalter)";
CM_ SG_ 1589 DI1_Schalter_def "Klemme 58s n.i.O /n1 = Fehler, bzw. nicht verfuegb";
CM_ SG_ 1589 DI1_Schalter "Schalterdimmung; Tastverhaeltnis' /n7F = Fehlerwer";
CM_ SG_ 1589 DI1_Display_def "Klemme 58d n.i.O /n1 = Fehler, bzw. nicht verfuegb";
CM_ SG_ 1589 DI1_Display "Displaydimmung; Tastverhaeltnis ' /n'7F = Fehlerwe";
CM_ BO_ 1629 "
Byte 1:Verlernzaehler
Byte 2:Kilometerstand, Uhr";
CM_ SG_ 1629 DN1_Verlernzaehler "Verlernzaehler /nFFh = Fehler, ungueltiger Zaehler";
CM_ SG_ 1629 DN1_Tag "Tag /n0 = unbekannt";
CM_ SG_ 1629 DN1_Stunde "Stunde /n18h - 1Fh ungueltig";
CM_ SG_ 1629 DN1_Sekunde "Sekunde /n3Ch - 3Fh ungueltig";
CM_ SG_ 1629 DN1_Monat "Monat /n0 = Monat unbekannt, Dh, Eh, ungueltig; Fh";
CM_ SG_ 1629 DN1_Minute "Minute /n3Ch - 3Fh ungueltig";
CM_ SG_ 1629 DN1_KM_Stand "Kilometerstand";
CM_ SG_ 1629 DN1_Jahr "Jahr /n0 = Datum unbekannt";
CM_ SG_ 1629 DN1_alt_Zeit "Zeit veraltet /n0 = Zeit aktuell vom Kombi empfang";
CM_ SG_ 1629 DN1_alt_Kilometerstand "Kilometerstand veraltet /n0 = Kilometerstand aktue";
CM_ BO_ 995 "
Byte 1:Sonnensensor_links
Byte 2:Sonnensensor_rechts
Byte 3:Innenraumtemperatur
Byte 4:Sitzheizung
Byte 5:Standheizung
Byte 8:Vorgabe Kuehlwassertemp";
CM_ SG_ 995 CL2_Vorgabe_KWTemp "Vorgabe Kuehlwassertemp /nFF = Fehler; Vorgabe der";
CM_ SG_ 995 CL2_Umluft_Taste "Umluft Taste gedrueckt /n1 = Taste gedrueckt, 0 =";
CM_ SG_ 995 CL2_Sonne_rechts "Sonnensensor rechts /nFF = Fehler";
CM_ SG_ 995 CL2_Sonne_links "Sonnensensor links /nFF = Fehler";
CM_ SG_ 995 CL2_SL_LED "Kontrollampe Standlueftung /n1 = Kontrolllampe SL_";
CM_ SG_ 995 CL2_SitzH_rechts "Sitzheizung rechts Stufe 0...6 /nStatus Sitzheizun";
CM_ SG_ 995 CL2_SitzH_links "Sitzheizung links Stufe 0...6 /nStatus Sitzheizung";
CM_ SG_ 995 CL2_SH "Standheizung /n1 = Standheizung ein, 0 = Standheiz";
CM_ SG_ 995 CL2_InnenTemp "Innenraumtemperatur /nFF = Fehler";
CM_ BO_ 993 "
Byte 1:Status
Byte 2:Aussentemp_ungefiltert
Byte 3:KlimaDrucksignal
Byte 4:Kompressorlast
Byte 5:Geblaeseslast
Byte 6:Kuehlerlueftersteuerung
Byte 7:Zusatzfunktionen";
CM_ SG_ 993 CL1_Zuheizer "Fahrerwunsch Zuheizer /n1 = Zuheizerfreigabe";
CM_ SG_ 993 CL1_Temp_in_F "Temperaturanzeige in der Klimaanlage in Fahrenheit";
CM_ SG_ 993 CL1_Strg_Kluefter "Ansteuerung Kuehlerluefter /nAnsteuerung des Kuehl";
CM_ SG_ 993 CL1_Last_Kompressor "Lastinfo: Kompressorzustand /nVerlustmoment der Kl";
CM_ SG_ 993 CL1_Kompressormoment_alt "Kompressormoment veraltet /n'1 = veraltet; Ermittl";
CM_ SG_ 993 CL1_Kompressor "Kompressor eingeschaltet /n1 = Kompressor ein";
CM_ SG_ 993 CL1_KD_Fehler "Kundendienstfehler im SG vorhanden /n1 = mindesten";
CM_ SG_ 993 CL1_Kaeltemitteldruck_alt "Kaeltemitteldruck veraltet /n'1 = veraltet; bei Kl";
CM_ SG_ 993 CL1_KaeltemittelDruck "Kaeltemitteldruck /nFF = Fehler";
CM_ SG_ 993 CL1_HzgHeckscheibe "Hzg Heckscheibe angesteuert (Power) /n1 = Hecksche";
CM_ SG_ 993 CL1_HzgFrontscheibe "Hzg Frontscheibe angesteuert (Power) /n1 = Frontsc";
CM_ SG_ 993 CL1_Heizung_aus "Keine Heizleistung gewuenscht /n1, wenn beide Temp";
CM_ SG_ 993 CL1_Geblaeselast "Lastinfo: Geblaeseansteuerung /nLastinfo";
CM_ SG_ 993 CL1_Drehzahlanhebung "Signal fuer Drehzahlanhebung /n1 = Drehzahlanhebun";
CM_ SG_ 993 CL1_AussenTemp "Aussentemperatur ungefiltert Wasserkasten /nFF = F";
CM_ BO_ 1708 "
Byte 4:Datenbyte 1
Byte 5:Datenbyte 2
Byte 6:Datenbyte 3
Byte 7:Datenbyte 4
Byte 8:Datenbyte 5";
CM_ SG_ 1708 Module_ID_12 "ZV";
CM_ SG_ 1708 Data_Byte_5_12 "Datenbyte 5 /nFestlegung der Datenbytes siehe CAN";
CM_ SG_ 1708 Data_Byte_4_12 "Datenbyte 4 /nFestlegung der Datenbytes siehe CAN";
CM_ SG_ 1708 Data_Byte_3_12 "Datenbyte 3 /nFestlegung der Datenbytes siehe CAN";
CM_ SG_ 1708 Data_Byte_2_12 "Datenbyte 2 /nFestlegung der Datenbytes siehe CAN";
CM_ SG_ 1708 Data_Byte_1_12 "Datenbyte 1 /nFestlegung der Datenbytes siehe CAN";
CM_ BO_ 1762 "
Byte 4:Datenbyte 1
Byte 5:Datenbyte 2
Byte 6:Datenbyte 3
Byte 7:Datenbyte 4
Byte 8:Datenbyte 5";
CM_ SG_ 1762 Module_ID_32 "Regen-Lichtsensor, AFL";
CM_ SG_ 1762 Data_Byte_5_32 "Datenbyte 5 /nFestlegung der Datenbytes siehe CAN";
CM_ SG_ 1762 Data_Byte_4_32 "Datenbyte 4 /nFestlegung der Datenbytes siehe CAN";
CM_ SG_ 1762 Data_Byte_3_32 "Datenbyte 3 /nFestlegung der Datenbytes siehe CAN";
CM_ SG_ 1762 Data_Byte_2_32 "Datenbyte 2 /nFestlegung der Datenbytes siehe CAN";
CM_ SG_ 1762 Data_Byte_1_32 "Datenbyte 1 /nFestlegung der Datenbytes siehe CAN";
CM_ BO_ 1761 "
Byte 4:Datenbyte 1
Byte 5:Datenbyte 2
Byte 6:Datenbyte 3
Byte 7:Datenbyte 4
Byte 8:Datenbyte 5";
CM_ SG_ 1761 Module_ID_31 "Regen-Lichtsensor, AFL";
CM_ SG_ 1761 Data_Byte_5_31 "Datenbyte 5 /nFestlegung der Datenbytes siehe CAN";
CM_ SG_ 1761 Data_Byte_4_31 "Datenbyte 4 /nFestlegung der Datenbytes siehe CAN";
CM_ SG_ 1761 Data_Byte_3_31 "Datenbyte 3 /nFestlegung der Datenbytes siehe CAN";
CM_ SG_ 1761 Data_Byte_2_31 "Datenbyte 2 /nFestlegung der Datenbytes siehe CAN";
CM_ SG_ 1761 Data_Byte_1_31 "Datenbyte 1 /nFestlegung der Datenbytes siehe CAN";
CM_ BO_ 1760 "
Byte 4:Datenbyte 1
Byte 5:Datenbyte 2
Byte 6:Datenbyte 3
Byte 7:Datenbyte 4
Byte 8:Datenbyte 5";
CM_ SG_ 1760 Module_ID_30 "Regen-Lichtsensor, AFL";
CM_ SG_ 1760 Data_Byte_5_30 "Datenbyte 5 /nFestlegung der Datenbytes siehe CAN";
CM_ SG_ 1760 Data_Byte_4_30 "Datenbyte 4 /nFestlegung der Datenbytes siehe CAN";
CM_ SG_ 1760 Data_Byte_3_30 "Datenbyte 3 /nFestlegung der Datenbytes siehe CAN";
CM_ SG_ 1760 Data_Byte_2_30 "Datenbyte 2 /nFestlegung der Datenbytes siehe CAN";
CM_ SG_ 1760 Data_Byte_1_30 "Datenbyte 1 /nFestlegung der Datenbytes siehe CAN";
CM_ BO_ 1698 "
Byte 4:Datenbyte 1
Byte 5:Datenbyte 2
Byte 6:Datenbyte 3
Byte 7:Datenbyte 4
Byte 8:Datenbyte 5";
CM_ SG_ 1698 Module_ID_2 "Regen-Lichtsensor, AFL";
CM_ SG_ 1698 Data_Byte_5_2 "Datenbyte 5 /nFestlegung der Datenbytes siehe CAN";
CM_ SG_ 1698 Data_Byte_4_2 "Datenbyte 4 /nFestlegung der Datenbytes siehe CAN";
CM_ SG_ 1698 Data_Byte_3_2 "Datenbyte 3 /nFestlegung der Datenbytes siehe CAN";
CM_ SG_ 1698 Data_Byte_2_2 "Datenbyte 2 /nFestlegung der Datenbytes siehe CAN";
CM_ SG_ 1698 Data_Byte_1_2 "Datenbyte 1 /nFestlegung der Datenbytes siehe CAN";
CM_ BO_ 1704 "
Byte 4:Datenbyte 1
Byte 5:Datenbyte 2
Byte 6:Datenbyte 3
Byte 7:Datenbyte 4
Byte 8:Datenbyte 5";
CM_ SG_ 1704 Module_ID_8 "Standheizung";
CM_ SG_ 1704 Data_Byte_5_8 "Datenbyte 5 /nFestlegung der Datenbytes siehe CAN";
CM_ SG_ 1704 Data_Byte_4_8 "Datenbyte 4 /nFestlegung der Datenbytes siehe CAN";
CM_ SG_ 1704 Data_Byte_3_8 "Datenbyte 3 /nFestlegung der Datenbytes siehe CAN";
CM_ SG_ 1704 Data_Byte_2_8 "Datenbyte 2 /nFestlegung der Datenbytes siehe CAN";
CM_ SG_ 1704 Data_Byte_1_8 "Datenbyte 1 /nFestlegung der Datenbytes siehe CAN";
CM_ BO_ 1710 "
Byte 4:Datenbyte 1
Byte 5:Datenbyte 2
Byte 6:Datenbyte 3
Byte 7:Datenbyte 4
Byte 8:Datenbyte 5";
CM_ SG_ 1710 Module_ID_14 "Regen-Lichtsensor, AFL";
CM_ SG_ 1710 Data_Byte_5_14 "Datenbyte 5 /nFestlegung der Datenbytes siehe CAN";
CM_ SG_ 1710 Data_Byte_4_14 "Datenbyte 4 /nFestlegung der Datenbytes siehe CAN";
CM_ SG_ 1710 Data_Byte_3_14 "Datenbyte 3 /nFestlegung der Datenbytes siehe CAN";
CM_ SG_ 1710 Data_Byte_2_14 "Datenbyte 2 /nFestlegung der Datenbytes siehe CAN";
CM_ SG_ 1710 Data_Byte_1_14 "Datenbyte 1 /nFestlegung der Datenbytes siehe CAN";
CM_ BO_ 1702 "
Byte 4:Datenbyte 1
Byte 5:Datenbyte 2
Byte 6:Datenbyte 3
Byte 7:Datenbyte 4
Byte 8:Datenbyte 5";
CM_ SG_ 1702 Module_ID_6 "Reifendruckkontrolle";
CM_ SG_ 1702 Data_Byte_5_6 "Datenbyte 5 /nFestlegung der Datenbytes siehe CAN";
CM_ SG_ 1702 Data_Byte_4_6 "Datenbyte 4 /nFestlegung der Datenbytes siehe CAN";
CM_ SG_ 1702 Data_Byte_3_6 "Datenbyte 3 /nFestlegung der Datenbytes siehe CAN";
CM_ SG_ 1702 Data_Byte_2_6 "Datenbyte 2 /nFestlegung der Datenbytes siehe CAN";
CM_ SG_ 1702 Data_Byte_1_6 "Datenbyte 1 /nFestlegung der Datenbytes siehe CAN";
CM_ BO_ 1785 "
Byte 4:Datenbyte 1
Byte 5:Datenbyte 2
Byte 6:Datenbyte 3
Byte 7:Datenbyte 4
Byte 8:Datenbyte 5";
CM_ SG_ 1785 Module_ID_24 "ZV";
CM_ SG_ 1785 Data_Byte_5_24 "Datenbyte 5 /nFestlegung der Datenbytes siehe CAN";
CM_ SG_ 1785 Data_Byte_4_24 "Datenbyte 4 /nFestlegung der Datenbytes siehe CAN";
CM_ SG_ 1785 Data_Byte_3_24 "Datenbyte 3 /nFestlegung der Datenbytes siehe CAN";
CM_ SG_ 1785 Data_Byte_2_24 "Datenbyte 2 /nFestlegung der Datenbytes siehe CAN";
CM_ SG_ 1785 Data_Byte_1_24 "Datenbyte 1 /nFestlegung der Datenbytes siehe CAN";
CM_ BO_ 1787 "
Byte 4:Datenbyte 1
Byte 5:Datenbyte 2
Byte 6:Datenbyte 3
Byte 7:Datenbyte 4
Byte 8:Datenbyte 5";
CM_ SG_ 1787 Module_ID_26 "Regen-Lichtsensor, AFL";
CM_ SG_ 1787 Data_Byte_5_26 "Datenbyte 5 /nFestlegung der Datenbytes siehe CAN";
CM_ SG_ 1787 Data_Byte_4_26 "Datenbyte 4 /nFestlegung der Datenbytes siehe CAN";
CM_ SG_ 1787 Data_Byte_3_26 "Datenbyte 3 /nFestlegung der Datenbytes siehe CAN";
CM_ SG_ 1787 Data_Byte_2_26 "Datenbyte 2 /nFestlegung der Datenbytes siehe CAN";
CM_ SG_ 1787 Data_Byte_1_26 "Datenbyte 1 /nFestlegung der Datenbytes siehe CAN";
CM_ BO_ 1781 "
Byte 4:Datenbyte 1
Byte 5:Datenbyte 2
Byte 6:Datenbyte 3
Byte 7:Datenbyte 4
Byte 8:Datenbyte 5";
CM_ SG_ 1781 Module_ID_20 "Reifendruckkontrolle";
CM_ SG_ 1781 Data_Byte_5_20 "Datenbyte 5 /nFestlegung der Datenbytes siehe CAN";
CM_ SG_ 1781 Data_Byte_4_20 "Datenbyte 4 /nFestlegung der Datenbytes siehe CAN";
CM_ SG_ 1781 Data_Byte_3_20 "Datenbyte 3 /nFestlegung der Datenbytes siehe CAN";
CM_ SG_ 1781 Data_Byte_2_20 "Datenbyte 2 /nFestlegung der Datenbytes siehe CAN";
CM_ SG_ 1781 Data_Byte_1_20 "Datenbyte 1 /nFestlegung der Datenbytes siehe CAN";
CM_ BO_ 1782 "
Byte 4:Datenbyte 1
Byte 5:Datenbyte 2
Byte 6:Datenbyte 3
Byte 7:Datenbyte 4
Byte 8:Datenbyte 5";
CM_ SG_ 1782 Module_ID_21 "Klima";
CM_ SG_ 1782 Data_Byte_5_21 "Datenbyte 5 /nFestlegung der Datenbytes siehe CAN";
CM_ SG_ 1782 Data_Byte_4_21 "Datenbyte 4 /nFestlegung der Datenbytes siehe CAN";
CM_ SG_ 1782 Data_Byte_3_21 "Datenbyte 3 /nFestlegung der Datenbytes siehe CAN";
CM_ SG_ 1782 Data_Byte_2_21 "Datenbyte 2 /nFestlegung der Datenbytes siehe CAN";
CM_ SG_ 1782 Data_Byte_1_21 "Datenbyte 1 /nFestlegung der Datenbytes siehe CAN";
CM_ BO_ 1783 "
Byte 4:Datenbyte 1
Byte 5:Datenbyte 2
Byte 6:Datenbyte 3
Byte 7:Datenbyte 4
Byte 8:Datenbyte 5";
CM_ SG_ 1783 Module_ID_22 "Fenster / Spiegel";
CM_ SG_ 1783 Data_Byte_5_22 "Datenbyte 5 /nFestlegung der Datenbytes siehe CAN";
CM_ SG_ 1783 Data_Byte_4_22 "Datenbyte 4 /nFestlegung der Datenbytes siehe CAN";
CM_ SG_ 1783 Data_Byte_3_22 "Datenbyte 3 /nFestlegung der Datenbytes siehe CAN";
CM_ SG_ 1783 Data_Byte_2_22 "Datenbyte 2 /nFestlegung der Datenbytes siehe CAN";
CM_ SG_ 1783 Data_Byte_1_22 "Datenbyte 1 /nFestlegung der Datenbytes siehe CAN";
CM_ BO_ 1780 "
Byte 4:Datenbyte 1
Byte 5:Datenbyte 2
Byte 6:Datenbyte 3
Byte 7:Datenbyte 4
Byte 8:Datenbyte 5";
CM_ SG_ 1780 Module_ID_19 "APS";
CM_ SG_ 1780 Data_Byte_5_19 "Datenbyte 5 /nFestlegung der Datenbytes siehe CAN";
CM_ SG_ 1780 Data_Byte_4_19 "Datenbyte 4 /nFestlegung der Datenbytes siehe CAN";
CM_ SG_ 1780 Data_Byte_3_19 "Datenbyte 3 /nFestlegung der Datenbytes siehe CAN";
CM_ SG_ 1780 Data_Byte_2_19 "Datenbyte 2 /nFestlegung der Datenbytes siehe CAN";
CM_ SG_ 1780 Data_Byte_1_19 "Datenbyte 1 /nFestlegung der Datenbytes siehe CAN";
CM_ BO_ 1697 "
Byte 4:Datenbyte 1
Byte 5:Datenbyte 2
Byte 6:Datenbyte 3
Byte 7:Datenbyte 4
Byte 8:Datenbyte 5";
CM_ SG_ 1697 Module_ID_1 "Regen-Lichtsensor, AFL";
CM_ SG_ 1697 Data_Byte_5_1 "Datenbyte 5 /nFestlegung der Datenbytes siehe CAN";
CM_ SG_ 1697 Data_Byte_4_1 "Datenbyte 4 /nFestlegung der Datenbytes siehe CAN";
CM_ SG_ 1697 Data_Byte_3_1 "Datenbyte 3 /nFestlegung der Datenbytes siehe CAN";
CM_ SG_ 1697 Data_Byte_2_1 "Datenbyte 2 /nFestlegung der Datenbytes siehe CAN";
CM_ SG_ 1697 Data_Byte_1_1 "Datenbyte 1 /nFestlegung der Datenbytes siehe CAN";
CM_ BO_ 1703 "
Byte 4:Datenbyte 1
Byte 5:Datenbyte 2
Byte 6:Datenbyte 3
Byte 7:Datenbyte 4
Byte 8:Datenbyte 5";
CM_ SG_ 1703 Module_ID_7 "Klima";
CM_ SG_ 1703 Data_Byte_5_7 "Datenbyte 5 /nFestlegung der Datenbytes siehe CAN";
CM_ SG_ 1703 Data_Byte_4_7 "Datenbyte 4 /nFestlegung der Datenbytes siehe CAN";
CM_ SG_ 1703 Data_Byte_3_7 "Datenbyte 3 /nFestlegung der Datenbytes siehe CAN";
CM_ SG_ 1703 Data_Byte_2_7 "Datenbyte 2 /nFestlegung der Datenbytes siehe CAN";
CM_ SG_ 1703 Data_Byte_1_7 "Datenbyte 1 /nFestlegung der Datenbytes siehe CAN";
CM_ BO_ 1705 "
Byte 4:Datenbyte 1
Byte 5:Datenbyte 2
Byte 6:Datenbyte 3
Byte 7:Datenbyte 4
Byte 8:Datenbyte 5";
CM_ SG_ 1705 Module_ID_9 "Fenster / Spiegel";
CM_ SG_ 1705 Data_Byte_5_9 "Datenbyte 5 /nFestlegung der Datenbytes siehe CAN";
CM_ SG_ 1705 Data_Byte_4_9 "Datenbyte 4 /nFestlegung der Datenbytes siehe CAN";
CM_ SG_ 1705 Data_Byte_3_9 "Datenbyte 3 /nFestlegung der Datenbytes siehe CAN";
CM_ SG_ 1705 Data_Byte_2_9 "Datenbyte 2 /nFestlegung der Datenbytes siehe CAN";
CM_ SG_ 1705 Data_Byte_1_9 "Datenbyte 1 /nFestlegung der Datenbytes siehe CAN";
CM_ BO_ 1696 "
Byte 4:Datenbyte 1
Byte 5:Datenbyte 2
Byte 6:Datenbyte 3
Byte 7:Datenbyte 4
Byte 8:Datenbyte 5";
CM_ SG_ 1696 Module_ID_0 "Regen-Lichtsensor, AFL";
CM_ SG_ 1696 Data_Byte_5_0 "Datenbyte 5 /nFestlegung der Datenbytes siehe CAN";
CM_ SG_ 1696 Data_Byte_4_0 "Datenbyte 4 /nFestlegung der Datenbytes siehe CAN";
CM_ SG_ 1696 Data_Byte_3_0 "Datenbyte 3 /nFestlegung der Datenbytes siehe CAN";
CM_ SG_ 1696 Data_Byte_2_0 "Datenbyte 2 /nFestlegung der Datenbytes siehe CAN";
CM_ SG_ 1696 Data_Byte_1_0 "Datenbyte 1 /nFestlegung der Datenbytes siehe CAN";
CM_ BO_ 1701 "
Byte 4:Datenbyte 1
Byte 5:Datenbyte 2
Byte 6:Datenbyte 3
Byte 7:Datenbyte 4
Byte 8:Datenbyte 5";
CM_ SG_ 1701 Module_ID_5 "APS";
CM_ SG_ 1701 Data_Byte_5_5 "Datenbyte 5 /nFestlegung der Datenbytes siehe CAN";
CM_ SG_ 1701 Data_Byte_4_5 "Datenbyte 4 /nFestlegung der Datenbytes siehe CAN";
CM_ SG_ 1701 Data_Byte_3_5 "Datenbyte 3 /nFestlegung der Datenbytes siehe CAN";
CM_ SG_ 1701 Data_Byte_2_5 "Datenbyte 2 /nFestlegung der Datenbytes siehe CAN";
CM_ SG_ 1701 Data_Byte_1_5 "Datenbyte 1 /nFestlegung der Datenbytes siehe CAN";
CM_ BO_ 1136 "
Byte 2:Tuerkontakte
Byte 3:Klemme_58d (Display)";
CM_ SG_ 1136 BSK_Unterspannung "Unterspannung, Signale nicht mehr alle o.k.";
CM_ SG_ 1136 BSK_Ruecks_HR_verriegelt "Status Verriegelungszustand Ruecksitzlehne rechts";
CM_ SG_ 1136 BSK_Ruecks_HL_verriegelt "Status Verriegelungszustand Ruecksitzlehne links /";
CM_ SG_ 1136 BSK_Rueckfahrlicht "Status Rueckfahrlicht /n1 = Rueckfahrlicht ein (AG";
CM_ SG_ 1136 BSK_NSL_LED_Pfad "Signalpfad Kontrolllampe Nebelschlusslicht /n0 = N";
CM_ SG_ 1136 BSK_MH_geoeffnet "Status des Motorhaubenkontaktes";
CM_ SG_ 1136 BSK_Ladekontrollampe "Ladekontrollampe /nredundantes Signal in BSG_Last";
CM_ SG_ 1136 BSK_HR_geoeffnet "Status der Drehfalle Tuer hinten rechts";
CM_ SG_ 1136 BSK_HL_geoeffnet "Status der Drehfalle Tuer hinten links";
CM_ SG_ 1136 BSK_HD_Vorraste "Status der Heckdeckel-Vorraste";
CM_ SG_ 1136 BSK_HD_Hauptraste "Status der Heckdeckel-Hauptraste";
CM_ SG_ 1136 BSK_FT_geoeffnet "Status der Drehfalle Fahrertuer";
CM_ SG_ 1136 BSK_Display_def "Klemme 58d n.i.O. /n1 = Fehler = nicht verfuegbar";
CM_ SG_ 1136 BSK_Display "Displaydimmung; Tastverhaeltnis' /n7F = Fehlerwert";
CM_ SG_ 1136 BSK_Def_Lampe "Ausfall einer Gluehlampe erkannt (Anzeige im Kombi";
CM_ SG_ 1136 BSK_BT_geoeffnet "Status der Drehfalle Beifahrertuer";
CM_ SG_ 1136 BSK_AFL_defekt "AFL_defekt /n0 = Automatisches Fahrlicht (AFL) i.o";
CM_ BO_ 1397 "
Byte 1:Klemmenzustaende
Byte 2:Zusatzfunktionen
Byte 3:Zusatzfunktionen_2";
CM_ SG_ 1397 BS3_LED_Sitze "Sitze LED /n1 = Heizbare Sitze angesteuert";
CM_ SG_ 1397 BS3_LED_Heckscheibe "Heckscheibe LED /n1 = Heizbare Heckscheibe angeste";
CM_ SG_ 1397 BS3_LED_Frontscheibe "Frontscheibe LED /n1 = Heizbare Frontscheibe anges";
CM_ SG_ 1397 BS3_LED_Aussenspiegel "Aussenspiegel LED /n1 = Heizbare Aussenspiegel ang";
CM_ SG_ 1397 BS3_Leaving_Home "Leaving Home Ausleuchtung aktiv /n1 = Leaving Home";
CM_ SG_ 1397 BS3_Ladekontrollampe "Ladekontrollampe(Klemme L) /n1 = mangelnde Batteri";
CM_ SG_ 1397 BS3_Klemme_X "Klemme X (Starten) /n1 = Klemme X aktiv";
CM_ SG_ 1397 BS3_Klemme_S "S-Kontakt (Schluessel steckt) /n1 = S-Kontakt gesc";
CM_ SG_ 1397 BS3_Klemme_P "Klemme 50 (Parklichtstellung) /n1 = Klemme P ein (";
CM_ SG_ 1397 BS3_Klemme_50 "Klemme 50 geschaltet (Starten) /n1 = Klemme 50 ist";
CM_ SG_ 1397 BS3_Klemme_15_Motorraum "Klemme 15 Motorraum geschaltet /n1 = Klemme 15 Mot";
CM_ SG_ 1397 BS3_Klemme_15 "Klemme 15 Innenraum geschaltet /n1 = Klemme 15 Inn";
CM_ SG_ 1397 BS3_KD_Fehler "Kundendienstfehler /n1 = mindestens ein Fehler ist";
CM_ SG_ 1397 BS3_K_Luefter_ein "Kuehlerluefter einschalten (s. BSG_Last, 5/2) /n1";
CM_ SG_ 1397 BS3_Haubenkontakt "Oeffnung Motorhaube /n1 = Haube geoeffnet / 0 = Ha";
CM_ SG_ 1397 BS3_Drehzahlanhebung "Drehzahlanhebung /n1 = Anforderung der drehzahlanh";
CM_ SG_ 1397 BS3_Coming_Home "Coming Home Ausleuchtung aktiv /n1 = Coming Home F";
CM_ SG_ 1397 BS3_Bordnetzbatt "Zustand der Bordnetzbatterie /nZeigt den Zustand d";
CM_ SG_ 1397 BS3_2_Drehzahl "Drehzahlanhebung 2. Stufe (s. BSG_Last) /n1 = Anfo";
CM_ BO_ 1393 "
Byte 1:Batteriespannung
Byte 2:Status Lastmanagement
Byte 4:Status Lastmanagement_2
Byte 5:Status Lastmanagement_3";
CM_ SG_ 1393 BS2_Warn_Zusatz "Zusatzverbraucherabschaltung steht bevor /n1 = Zus";
CM_ SG_ 1393 BS2_Warn_Infotainment "Infotainmentteilnehmerabschaltung steht bevor /n1";
CM_ SG_ 1393 BS2_Verbr_ab_aktiv "Verbraucherabschaltung aktiv /n1 = Forderung, dass";
CM_ SG_ 1393 BS2_U_BATT "Bordnetz_Batterie_Spannung (s. BSG_Last) /nFF = Fe";
CM_ SG_ 1393 BS2_Sitzheizung_aus "Heizbare_Sitze abschalten (s. BSG_Last) /n1 = Absc";
CM_ SG_ 1393 BS2_Lastman_aktiv "Lastmanagement aktiv /n1 = Lastmanagement ist akti";
CM_ SG_ 1393 BS2_KlimaLeistRed "Leistungsreduzierung Klimaanlage /n'0: keine Leist";
CM_ SG_ 1393 BS2_Klimaanlage_aus "Klimaanlage abschalt. / reduzieren (s. BSG_Last) /";
CM_ SG_ 1393 BS2_Heckscheibe_aus "Heizbare_Heckscheibe abschalten (s. BSG_Last) /n1";
CM_ SG_ 1393 BS2_Frontscheibe_aus "Heizbare_Frontscheibe abschalten (s. BSG_Last) /n1";
CM_ SG_ 1393 BS2_Aussenspiegel_aus "Heizbare_Aussenspiegel abschalten (s. BSG_Last) /n";
CM_ SG_ 1393 BS2_aus_Sitzlueftung "Sitzbelueftung abschalten /n1 = Abschalten der Sit";
CM_ SG_ 1393 BS2_aus_Sitzhzg_H "Hintere Sitzheizung abschalten /n1 = Abschalten de";
CM_ SG_ 1393 BS2_aus_PTC_Clima "Clima-PTC abschalten /nAbschalten der Zusatzheizel";
CM_ SG_ 1393 BS2_aus_Lenkradheizung "Lenkradheizung abschalten (s. BSG_Last) /n1 = Absc";
CM_ SG_ 1393 BS2_aus_Infotainment "Infotainmentfunktionalitaet abschalten/reduzieren";
CM_ BO_ 1429 "
Byte 1:Status_1";
CM_ SG_ 1429 AG1_RFL_def "Anhaenger Rueckfahrlicht defekt /n1 = Rueckfahrlic";
CM_ SG_ 1429 AG1_NSL_def "Anhaenger Nebelschlusslicht defekt /n1 = Anhaenger";
CM_ SG_ 1429 AG1_Licht_r_def "Schlusslicht rechts defekt /n1 = Anhaengerschlussl";
CM_ SG_ 1429 AG1_Licht_l_def "Schlusslicht links defekt /n1 = Anhaengerschlussli";
CM_ SG_ 1429 AG1_KD_Fehler "Kundendienstfehlerspeichereintrag /n1 = mindestens";
CM_ SG_ 1429 AG1_Blk_ein "Anhaenger Blinker /n1 = Anhaenger Blinker ein, Bli";
CM_ SG_ 1429 AG1_Blinker_r_def "Anhaenger Blinker rechts defekt /n1 = Anhaengerbli";
CM_ SG_ 1429 AG1_Blinker_l_def "Anhaenger Blinker links defekt /n1 = Anhaengerblin";
CM_ SG_ 1429 AG1_BL_def "Anhaenger Bremslicht defekt (s. Gateway_Komfort_1)";
CM_ SG_ 1429 AG1_ANH_Erk "Anhaenger erkannt (Kombi 2, Gateway Komfort 1) /n1";
CM_ BO_ 337 "
Byte 1:Airbag_Crash_Signal
Byte 2:Airbag_Zusatzfunktionen 1
Byte 3:Airbag_Zaehler
Byte 4:Checksumme";
CM_ SG_ 337 AB1_Systemfehler "Systemfehler erkannt /n1 = Fehler im Airbagsystem";
CM_ SG_ 337 AB1_Stellglied "Airbag im Stellgliedtest /n1 = Airbag im Stellglie";
CM_ SG_ 337 AB1_Rollover "Rollover /n1 = Rollover, dieses Bit bleibt nur fue";
CM_ SG_ 337 AB1_Pruefsumme "Pruefsumme gem. Lastenheft CAN-Antrieb /nDefinitio";
CM_ SG_ 337 AB1_MessageZaehler "Botschaftszaehler zur Lebenderkennnug";
CM_ SG_ 337 AB1_KD_Fehler "Kundendienstfehler im SG eingetragen /n1 = mindest";
CM_ SG_ 337 AB1_HeckCrash "Heck-Crash /n1 = Heck-Crash, dieses Bit bleibt nur";
CM_ SG_ 337 AB1_FTGurtwarnung "Gurtwarnung Fahrer /n1 = Fahrer Warnung aktiv";
CM_ SG_ 337 AB1_FTGurtschalter "Gurtschalter Fahrer /n1 = Fahrer Gurt gesteckt";
CM_ SG_ 337 AB1_FrontCrash "Front-Crash /n1 = Front-Crash, dieses Bit bleibt n";
CM_ SG_ 337 AB1_Diagnose "Airbag in Diagnose /n1 = Airbag in Diagnose";
CM_ SG_ 337 AB1_CrashStaerke "Crash-Intensitaet /n(Bit 7, 6, 5) >= 001: Innenlic";
CM_ SG_ 337 AB1_Crash_FT "Seiten-Crash Fahrer /n1 = Seiten-Crash, dieses Bit";
CM_ SG_ 337 AB1_Crash_BT "Seiten-Crash Beifahrer /n1 = Seiten-Crash, dieses";
CM_ SG_ 337 AB1_BTGurtwarnung "Gurtwarnung Beifahrer /n1 = Beifahrer Warnung akti";
CM_ SG_ 337 AB1_BTGurtschalter "Gurtschalter Beifahrer /n1 = Beifahrer Gurt gestec";
CM_ SG_ 337 AB1_AirbagLampe_ein "Kontrollampe Airbag ein /n1 = Warnlampe im Kombi e";
CM_ SG_ 337 AB1_Airbag_deaktiviert "Airbag deaktiviert /n1 = Airbag oder Gurtstraffer";
BA_DEF_ BO_  "VAGTP20_StatConnection" ENUM  "nein","ja";
BA_DEF_ SG_  "GenSigTimeoutTime_<ECU>" HEX 0 2047;
BA_DEF_ SG_  "GenSigTimeoutMsg_<ECU>" HEX 0 2047;
BA_DEF_ SG_  "GenSigInactiveValue" HEX 0 134217727;
BA_DEF_ SG_  "GenSigSendType" ENUM  "Cyclic","OnWrite","OnWriteWithRepetition","OnChange","OnChangeWithRepetition","IfActive","IfActiveWithRepetition","NoSigSendType";
BA_DEF_ BO_  "GenMsgTimeoutTime" INT 0 100000;
BA_DEF_ BO_  "GenMsgNrOfRepetition" INT 0 100;
BA_DEF_ BO_  "GenMsgNoIalSupport" ENUM  "No","Yes";
BA_DEF_ BO_  "GenMsgStartDelayTime" INT 0 100000;
BA_DEF_ BO_  "GenMsgCycleTimeFast" INT 0 65535;
BA_DEF_ BO_  "GenMsgDelayTime" INT 0 100000;
BA_DEF_ BO_  "VAGTP20_DynConnection" ENUM  "nein","ja";
BA_DEF_ BO_  "VAGTP20_DynSetup" ENUM  "nein","ja";
BA_DEF_ BO_  "xVWTP_Channel" ENUM  "nein","ja";
BA_DEF_ BO_  "xVWTP_Setup" ENUM  "nein","ja";
BA_DEF_ SG_  "SignalRepeatDeactivation" INT 0 20;
BA_DEF_ SG_  "SignalRepeatActivation" INT 0 20;
BA_DEF_ BO_  "GenMsgSendType" ENUM  "cyclicX","spontanX","cyclicIfActiveX","spontanWithDelay","cyclicAndSpontanX","cyclicAndSpontanWithDelay","spontanWithRepitition","cyclicIfActiveAndSpontanWD","cyclicIfActiveFast","cyclicWithRepeatOnDemand";
BA_DEF_ BO_  "GenMsgCycleTime" INT 0 65535;
BA_DEF_ BO_  "NWM-Botschaft" ENUM  "nein","ja";
BA_DEF_DEF_  "VAGTP20_StatConnection" "";
BA_DEF_DEF_  "GenSigTimeoutTime_<ECU>" 0;
BA_DEF_DEF_  "GenSigTimeoutMsg_<ECU>" 0;
BA_DEF_DEF_  "GenSigInactiveValue" 0;
BA_DEF_DEF_  "GenSigSendType" "";
BA_DEF_DEF_  "GenMsgTimeoutTime" 0;
BA_DEF_DEF_  "GenMsgNrOfRepetition" 0;
BA_DEF_DEF_  "GenMsgNoIalSupport" "";
BA_DEF_DEF_  "GenMsgStartDelayTime" 0;
BA_DEF_DEF_  "GenMsgCycleTimeFast" 0;
BA_DEF_DEF_  "GenMsgDelayTime" 0;
BA_DEF_DEF_  "VAGTP20_DynConnection" "";
BA_DEF_DEF_  "VAGTP20_DynSetup" "";
BA_DEF_DEF_  "xVWTP_Channel" "";
BA_DEF_DEF_  "xVWTP_Setup" "";
BA_DEF_DEF_  "SignalRepeatDeactivation" 0;
BA_DEF_DEF_  "SignalRepeatActivation" 0;
BA_DEF_DEF_  "GenMsgSendType" "";
BA_DEF_DEF_  "GenMsgCycleTime" 0;
BA_DEF_DEF_  "NWM-Botschaft" "";
BA_ "GenMsgCycleTime" BO_ 1039 100;
BA_ "GenMsgSendType" BO_ 1039 5;
BA_ "xVWTP_Setup" BO_ 1039 0;
BA_ "xVWTP_Channel" BO_ 1039 0;
BA_ "VAGTP20_DynSetup" BO_ 1039 0;
BA_ "VAGTP20_DynConnection" BO_ 1039 0;
BA_ "GenMsgNoIalSupport" BO_ 1039 0;
BA_ "VAGTP20_StatConnection" BO_ 1039 0;
BA_ "NWM-Botschaft" BO_ 1039 1;
BA_ "GenMsgCycleTime" BO_ 1033 100;
BA_ "GenMsgSendType" BO_ 1033 5;
BA_ "xVWTP_Setup" BO_ 1033 0;
BA_ "xVWTP_Channel" BO_ 1033 0;
BA_ "VAGTP20_DynSetup" BO_ 1033 0;
BA_ "VAGTP20_DynConnection" BO_ 1033 0;
BA_ "GenMsgNoIalSupport" BO_ 1033 0;
BA_ "VAGTP20_StatConnection" BO_ 1033 0;
BA_ "NWM-Botschaft" BO_ 1033 1;
BA_ "GenMsgCycleTime" BO_ 1038 100;
BA_ "GenMsgSendType" BO_ 1038 5;
BA_ "xVWTP_Setup" BO_ 1038 0;
BA_ "xVWTP_Channel" BO_ 1038 0;
BA_ "VAGTP20_DynSetup" BO_ 1038 0;
BA_ "VAGTP20_DynConnection" BO_ 1038 0;
BA_ "GenMsgNoIalSupport" BO_ 1038 0;
BA_ "VAGTP20_StatConnection" BO_ 1038 0;
BA_ "NWM-Botschaft" BO_ 1038 1;
BA_ "GenMsgCycleTime" BO_ 1050 100;
BA_ "GenMsgSendType" BO_ 1050 5;
BA_ "xVWTP_Setup" BO_ 1050 0;
BA_ "xVWTP_Channel" BO_ 1050 0;
BA_ "VAGTP20_DynSetup" BO_ 1050 0;
BA_ "VAGTP20_DynConnection" BO_ 1050 0;
BA_ "GenMsgNoIalSupport" BO_ 1050 0;
BA_ "VAGTP20_StatConnection" BO_ 1050 0;
BA_ "NWM-Botschaft" BO_ 1050 1;
BA_ "GenMsgCycleTime" BO_ 1045 100;
BA_ "GenMsgSendType" BO_ 1045 5;
BA_ "xVWTP_Setup" BO_ 1045 0;
BA_ "xVWTP_Channel" BO_ 1045 0;
BA_ "VAGTP20_DynSetup" BO_ 1045 0;
BA_ "VAGTP20_DynConnection" BO_ 1045 0;
BA_ "GenMsgNoIalSupport" BO_ 1045 0;
BA_ "VAGTP20_StatConnection" BO_ 1045 0;
BA_ "NWM-Botschaft" BO_ 1045 1;
BA_ "GenMsgCycleTime" BO_ 1030 100;
BA_ "GenMsgSendType" BO_ 1030 5;
BA_ "xVWTP_Setup" BO_ 1030 0;
BA_ "xVWTP_Channel" BO_ 1030 0;
BA_ "VAGTP20_DynSetup" BO_ 1030 0;
BA_ "VAGTP20_DynConnection" BO_ 1030 0;
BA_ "GenMsgNoIalSupport" BO_ 1030 0;
BA_ "VAGTP20_StatConnection" BO_ 1030 0;
BA_ "NWM-Botschaft" BO_ 1030 1;
BA_ "GenMsgCycleTime" BO_ 1035 100;
BA_ "GenMsgSendType" BO_ 1035 5;
BA_ "xVWTP_Setup" BO_ 1035 0;
BA_ "xVWTP_Channel" BO_ 1035 0;
BA_ "VAGTP20_DynSetup" BO_ 1035 0;
BA_ "VAGTP20_DynConnection" BO_ 1035 0;
BA_ "GenMsgNoIalSupport" BO_ 1035 0;
BA_ "VAGTP20_StatConnection" BO_ 1035 0;
BA_ "NWM-Botschaft" BO_ 1035 1;
BA_ "GenMsgCycleTime" BO_ 1036 100;
BA_ "GenMsgSendType" BO_ 1036 5;
BA_ "xVWTP_Setup" BO_ 1036 0;
BA_ "xVWTP_Channel" BO_ 1036 0;
BA_ "VAGTP20_DynSetup" BO_ 1036 0;
BA_ "VAGTP20_DynConnection" BO_ 1036 0;
BA_ "GenMsgNoIalSupport" BO_ 1036 0;
BA_ "VAGTP20_StatConnection" BO_ 1036 0;
BA_ "NWM-Botschaft" BO_ 1036 1;
BA_ "GenMsgCycleTime" BO_ 1024 100;
BA_ "GenMsgSendType" BO_ 1024 5;
BA_ "xVWTP_Setup" BO_ 1024 0;
BA_ "xVWTP_Channel" BO_ 1024 0;
BA_ "VAGTP20_DynSetup" BO_ 1024 0;
BA_ "VAGTP20_DynConnection" BO_ 1024 0;
BA_ "GenMsgNoIalSupport" BO_ 1024 0;
BA_ "VAGTP20_StatConnection" BO_ 1024 0;
BA_ "NWM-Botschaft" BO_ 1024 1;
BA_ "GenMsgCycleTime" BO_ 1037 100;
BA_ "GenMsgSendType" BO_ 1037 5;
BA_ "xVWTP_Setup" BO_ 1037 0;
BA_ "xVWTP_Channel" BO_ 1037 0;
BA_ "VAGTP20_DynSetup" BO_ 1037 0;
BA_ "VAGTP20_DynConnection" BO_ 1037 0;
BA_ "GenMsgNoIalSupport" BO_ 1037 0;
BA_ "VAGTP20_StatConnection" BO_ 1037 0;
BA_ "NWM-Botschaft" BO_ 1037 1;
BA_ "GenMsgCycleTime" BO_ 1044 100;
BA_ "GenMsgSendType" BO_ 1044 5;
BA_ "xVWTP_Setup" BO_ 1044 0;
BA_ "xVWTP_Channel" BO_ 1044 0;
BA_ "VAGTP20_DynSetup" BO_ 1044 0;
BA_ "VAGTP20_DynConnection" BO_ 1044 0;
BA_ "GenMsgNoIalSupport" BO_ 1044 0;
BA_ "VAGTP20_StatConnection" BO_ 1044 0;
BA_ "NWM-Botschaft" BO_ 1044 1;
BA_ "GenMsgCycleTime" BO_ 1365 100;
BA_ "GenMsgSendType" BO_ 1365 0;
BA_ "xVWTP_Setup" BO_ 1365 0;
BA_ "xVWTP_Channel" BO_ 1365 0;
BA_ "VAGTP20_DynSetup" BO_ 1365 0;
BA_ "VAGTP20_DynConnection" BO_ 1365 0;
BA_ "GenMsgNoIalSupport" BO_ 1365 0;
BA_ "VAGTP20_StatConnection" BO_ 1365 0;
BA_ "NWM-Botschaft" BO_ 1365 0;
BA_ "GenMsgSendType" BO_ 1473 7;
BA_ "xVWTP_Setup" BO_ 1473 0;
BA_ "xVWTP_Channel" BO_ 1473 0;
BA_ "VAGTP20_DynSetup" BO_ 1473 0;
BA_ "VAGTP20_DynConnection" BO_ 1473 0;
BA_ "GenMsgCycleTimeFast" BO_ 1473 100;
BA_ "GenMsgNoIalSupport" BO_ 1473 0;
BA_ "GenMsgNrOfRepetition" BO_ 1473 5;
BA_ "VAGTP20_StatConnection" BO_ 1473 0;
BA_ "NWM-Botschaft" BO_ 1473 0;
BA_ "GenMsgCycleTime" BO_ 1475 100;
BA_ "GenMsgSendType" BO_ 1475 5;
BA_ "xVWTP_Setup" BO_ 1475 0;
BA_ "xVWTP_Channel" BO_ 1475 0;
BA_ "VAGTP20_DynSetup" BO_ 1475 0;
BA_ "VAGTP20_DynConnection" BO_ 1475 0;
BA_ "GenMsgNoIalSupport" BO_ 1475 0;
BA_ "VAGTP20_StatConnection" BO_ 1475 0;
BA_ "NWM-Botschaft" BO_ 1475 0;
BA_ "GenMsgCycleTime" BO_ 889 100;
BA_ "GenMsgSendType" BO_ 889 5;
BA_ "xVWTP_Setup" BO_ 889 0;
BA_ "xVWTP_Channel" BO_ 889 0;
BA_ "VAGTP20_DynSetup" BO_ 889 0;
BA_ "VAGTP20_DynConnection" BO_ 889 0;
BA_ "GenMsgNoIalSupport" BO_ 889 0;
BA_ "VAGTP20_StatConnection" BO_ 889 0;
BA_ "NWM-Botschaft" BO_ 889 0;
BA_ "GenMsgSendType" BO_ 1317 2;
BA_ "xVWTP_Setup" BO_ 1317 0;
BA_ "xVWTP_Channel" BO_ 1317 0;
BA_ "VAGTP20_DynSetup" BO_ 1317 0;
BA_ "VAGTP20_DynConnection" BO_ 1317 0;
BA_ "GenMsgCycleTimeFast" BO_ 1317 100;
BA_ "GenMsgNoIalSupport" BO_ 1317 0;
BA_ "GenMsgNrOfRepetition" BO_ 1317 5;
BA_ "VAGTP20_StatConnection" BO_ 1317 0;
BA_ "NWM-Botschaft" BO_ 1317 0;
BA_ "GenMsgCycleTime" BO_ 1297 500;
BA_ "GenMsgSendType" BO_ 1297 5;
BA_ "xVWTP_Setup" BO_ 1297 0;
BA_ "xVWTP_Channel" BO_ 1297 0;
BA_ "VAGTP20_DynSetup" BO_ 1297 0;
BA_ "VAGTP20_DynConnection" BO_ 1297 0;
BA_ "GenMsgNoIalSupport" BO_ 1297 0;
BA_ "VAGTP20_StatConnection" BO_ 1297 0;
BA_ "NWM-Botschaft" BO_ 1297 0;
BA_ "GenMsgCycleTime" BO_ 1301 500;
BA_ "GenMsgSendType" BO_ 1301 5;
BA_ "xVWTP_Setup" BO_ 1301 0;
BA_ "xVWTP_Channel" BO_ 1301 0;
BA_ "VAGTP20_DynSetup" BO_ 1301 0;
BA_ "VAGTP20_DynConnection" BO_ 1301 0;
BA_ "GenMsgNoIalSupport" BO_ 1301 0;
BA_ "VAGTP20_StatConnection" BO_ 1301 0;
BA_ "NWM-Botschaft" BO_ 1301 0;
BA_ "GenMsgCycleTime" BO_ 705 100;
BA_ "GenMsgSendType" BO_ 705 5;
BA_ "xVWTP_Setup" BO_ 705 0;
BA_ "xVWTP_Channel" BO_ 705 0;
BA_ "VAGTP20_DynSetup" BO_ 705 0;
BA_ "VAGTP20_DynConnection" BO_ 705 0;
BA_ "GenMsgNoIalSupport" BO_ 705 0;
BA_ "VAGTP20_StatConnection" BO_ 705 0;
BA_ "NWM-Botschaft" BO_ 705 0;
BA_ "GenMsgSendType" BO_ 1585 7;
BA_ "xVWTP_Setup" BO_ 1585 0;
BA_ "xVWTP_Channel" BO_ 1585 0;
BA_ "VAGTP20_DynSetup" BO_ 1585 0;
BA_ "VAGTP20_DynConnection" BO_ 1585 0;
BA_ "GenMsgCycleTimeFast" BO_ 1585 1000;
BA_ "GenMsgNoIalSupport" BO_ 1585 0;
BA_ "GenMsgNrOfRepetition" BO_ 1585 5;
BA_ "VAGTP20_StatConnection" BO_ 1585 0;
BA_ "NWM-Botschaft" BO_ 1585 0;
BA_ "GenMsgCycleTime" BO_ 1329 50;
BA_ "GenMsgSendType" BO_ 1329 5;
BA_ "xVWTP_Setup" BO_ 1329 0;
BA_ "xVWTP_Channel" BO_ 1329 0;
BA_ "VAGTP20_DynSetup" BO_ 1329 0;
BA_ "VAGTP20_DynConnection" BO_ 1329 0;
BA_ "GenMsgNoIalSupport" BO_ 1329 0;
BA_ "VAGTP20_StatConnection" BO_ 1329 0;
BA_ "NWM-Botschaft" BO_ 1329 0;
BA_ "GenMsgCycleTime" BO_ 963 100;
BA_ "GenMsgSendType" BO_ 963 0;
BA_ "xVWTP_Setup" BO_ 963 0;
BA_ "xVWTP_Channel" BO_ 963 0;
BA_ "VAGTP20_DynSetup" BO_ 963 0;
BA_ "VAGTP20_DynConnection" BO_ 963 0;
BA_ "GenMsgNoIalSupport" BO_ 963 0;
BA_ "VAGTP20_StatConnection" BO_ 963 0;
BA_ "NWM-Botschaft" BO_ 963 0;
BA_ "GenMsgCycleTime" BO_ 961 200;
BA_ "GenMsgSendType" BO_ 961 0;
BA_ "xVWTP_Setup" BO_ 961 0;
BA_ "xVWTP_Channel" BO_ 961 0;
BA_ "VAGTP20_DynSetup" BO_ 961 0;
BA_ "VAGTP20_DynConnection" BO_ 961 0;
BA_ "GenMsgNoIalSupport" BO_ 961 0;
BA_ "VAGTP20_StatConnection" BO_ 961 0;
BA_ "NWM-Botschaft" BO_ 961 0;
BA_ "GenMsgCycleTime" BO_ 1569 100;
BA_ "GenMsgSendType" BO_ 1569 0;
BA_ "xVWTP_Setup" BO_ 1569 0;
BA_ "xVWTP_Channel" BO_ 1569 0;
BA_ "VAGTP20_DynSetup" BO_ 1569 0;
BA_ "VAGTP20_DynConnection" BO_ 1569 0;
BA_ "GenMsgNoIalSupport" BO_ 1569 0;
BA_ "VAGTP20_StatConnection" BO_ 1569 0;
BA_ "NWM-Botschaft" BO_ 1569 0;
BA_ "GenMsgSendType" BO_ 1501 7;
BA_ "xVWTP_Setup" BO_ 1501 0;
BA_ "xVWTP_Channel" BO_ 1501 0;
BA_ "VAGTP20_DynSetup" BO_ 1501 0;
BA_ "VAGTP20_DynConnection" BO_ 1501 0;
BA_ "GenMsgCycleTimeFast" BO_ 1501 100;
BA_ "GenMsgNoIalSupport" BO_ 1501 0;
BA_ "VAGTP20_StatConnection" BO_ 1501 0;
BA_ "NWM-Botschaft" BO_ 1501 0;
BA_ "GenMsgCycleTime" BO_ 859 100;
BA_ "GenMsgSendType" BO_ 859 5;
BA_ "xVWTP_Setup" BO_ 859 0;
BA_ "xVWTP_Channel" BO_ 859 0;
BA_ "VAGTP20_DynSetup" BO_ 859 0;
BA_ "VAGTP20_DynConnection" BO_ 859 0;
BA_ "GenMsgNoIalSupport" BO_ 859 0;
BA_ "VAGTP20_StatConnection" BO_ 859 0;
BA_ "NWM-Botschaft" BO_ 859 0;
BA_ "GenMsgCycleTime" BO_ 1319 200;
BA_ "GenMsgSendType" BO_ 1319 0;
BA_ "xVWTP_Setup" BO_ 1319 0;
BA_ "xVWTP_Channel" BO_ 1319 0;
BA_ "VAGTP20_DynSetup" BO_ 1319 0;
BA_ "VAGTP20_DynConnection" BO_ 1319 0;
BA_ "GenMsgNoIalSupport" BO_ 1319 0;
BA_ "VAGTP20_StatConnection" BO_ 1319 0;
BA_ "NWM-Botschaft" BO_ 1319 0;
BA_ "GenMsgCycleTime" BO_ 857 100;
BA_ "GenMsgSendType" BO_ 857 0;
BA_ "xVWTP_Setup" BO_ 857 0;
BA_ "xVWTP_Channel" BO_ 857 0;
BA_ "VAGTP20_DynSetup" BO_ 857 0;
BA_ "VAGTP20_DynConnection" BO_ 857 0;
BA_ "GenMsgNoIalSupport" BO_ 857 0;
BA_ "VAGTP20_StatConnection" BO_ 857 0;
BA_ "NWM-Botschaft" BO_ 857 0;
BA_ "GenMsgCycleTime" BO_ 649 20;
BA_ "GenMsgSendType" BO_ 649 0;
BA_ "xVWTP_Setup" BO_ 649 0;
BA_ "xVWTP_Channel" BO_ 649 0;
BA_ "VAGTP20_DynSetup" BO_ 649 0;
BA_ "VAGTP20_DynConnection" BO_ 649 0;
BA_ "GenMsgNoIalSupport" BO_ 649 0;
BA_ "VAGTP20_StatConnection" BO_ 649 0;
BA_ "NWM-Botschaft" BO_ 649 0;
BA_ "GenMsgCycleTime" BO_ 1619 500;
BA_ "GenMsgSendType" BO_ 1619 0;
BA_ "xVWTP_Setup" BO_ 1619 0;
BA_ "xVWTP_Channel" BO_ 1619 0;
BA_ "VAGTP20_DynSetup" BO_ 1619 0;
BA_ "VAGTP20_DynConnection" BO_ 1619 0;
BA_ "GenMsgNoIalSupport" BO_ 1619 0;
BA_ "VAGTP20_StatConnection" BO_ 1619 0;
BA_ "NWM-Botschaft" BO_ 1619 0;
BA_ "GenMsgCycleTime" BO_ 1631 200;
BA_ "GenMsgSendType" BO_ 1631 0;
BA_ "xVWTP_Setup" BO_ 1631 0;
BA_ "xVWTP_Channel" BO_ 1631 0;
BA_ "VAGTP20_DynSetup" BO_ 1631 0;
BA_ "VAGTP20_DynConnection" BO_ 1631 0;
BA_ "GenMsgNoIalSupport" BO_ 1631 0;
BA_ "VAGTP20_StatConnection" BO_ 1631 0;
BA_ "NWM-Botschaft" BO_ 1631 0;
BA_ "GenMsgNoIalSupport" BO_ 2016 0;
BA_ "VAGTP20_StatConnection" BO_ 2016 0;
BA_ "VAGTP20_DynConnection" BO_ 2016 0;
BA_ "VAGTP20_DynSetup" BO_ 2016 0;
BA_ "xVWTP_Channel" BO_ 2016 0;
BA_ "xVWTP_Setup" BO_ 2016 0;
BA_ "GenMsgCycleTime" BO_ 2016 100;
BA_ "NWM-Botschaft" BO_ 2016 0;
BA_ "GenMsgSendType" BO_ 2016 2;
BA_ "GenMsgCycleTime" BO_ 1550 1000;
BA_ "GenMsgSendType" BO_ 1550 5;
BA_ "xVWTP_Setup" BO_ 1550 0;
BA_ "xVWTP_Channel" BO_ 1550 0;
BA_ "VAGTP20_DynSetup" BO_ 1550 0;
BA_ "VAGTP20_DynConnection" BO_ 1550 0;
BA_ "GenMsgNoIalSupport" BO_ 1550 0;
BA_ "VAGTP20_StatConnection" BO_ 1550 0;
BA_ "NWM-Botschaft" BO_ 1550 0;
BA_ "GenMsgCycleTime" BO_ 1583 200;
BA_ "GenMsgSendType" BO_ 1583 5;
BA_ "xVWTP_Setup" BO_ 1583 0;
BA_ "xVWTP_Channel" BO_ 1583 0;
BA_ "VAGTP20_DynSetup" BO_ 1583 0;
BA_ "VAGTP20_DynConnection" BO_ 1583 0;
BA_ "GenMsgNoIalSupport" BO_ 1583 0;
BA_ "VAGTP20_StatConnection" BO_ 1583 0;
BA_ "NWM-Botschaft" BO_ 1583 0;
BA_ "GenMsgCycleTime" BO_ 1589 200;
BA_ "GenMsgSendType" BO_ 1589 5;
BA_ "xVWTP_Setup" BO_ 1589 0;
BA_ "xVWTP_Channel" BO_ 1589 0;
BA_ "VAGTP20_DynSetup" BO_ 1589 0;
BA_ "VAGTP20_DynConnection" BO_ 1589 0;
BA_ "GenMsgNoIalSupport" BO_ 1589 0;
BA_ "VAGTP20_StatConnection" BO_ 1589 0;
BA_ "NWM-Botschaft" BO_ 1589 0;
BA_ "GenMsgCycleTime" BO_ 1629 1000;
BA_ "GenMsgSendType" BO_ 1629 0;
BA_ "xVWTP_Setup" BO_ 1629 0;
BA_ "xVWTP_Channel" BO_ 1629 0;
BA_ "VAGTP20_DynSetup" BO_ 1629 0;
BA_ "VAGTP20_DynConnection" BO_ 1629 0;
BA_ "GenMsgNoIalSupport" BO_ 1629 0;
BA_ "VAGTP20_StatConnection" BO_ 1629 0;
BA_ "NWM-Botschaft" BO_ 1629 0;
BA_ "GenMsgCycleTime" BO_ 995 800;
BA_ "GenMsgSendType" BO_ 995 0;
BA_ "xVWTP_Setup" BO_ 995 0;
BA_ "xVWTP_Channel" BO_ 995 0;
BA_ "VAGTP20_DynSetup" BO_ 995 0;
BA_ "VAGTP20_DynConnection" BO_ 995 0;
BA_ "GenMsgNoIalSupport" BO_ 995 0;
BA_ "VAGTP20_StatConnection" BO_ 995 0;
BA_ "NWM-Botschaft" BO_ 995 0;
BA_ "GenMsgCycleTime" BO_ 993 100;
BA_ "GenMsgSendType" BO_ 993 5;
BA_ "xVWTP_Setup" BO_ 993 0;
BA_ "xVWTP_Channel" BO_ 993 0;
BA_ "VAGTP20_DynSetup" BO_ 993 0;
BA_ "VAGTP20_DynConnection" BO_ 993 0;
BA_ "GenMsgNoIalSupport" BO_ 993 0;
BA_ "VAGTP20_StatConnection" BO_ 993 0;
BA_ "NWM-Botschaft" BO_ 993 0;
BA_ "GenMsgSendType" BO_ 1708 7;
BA_ "xVWTP_Setup" BO_ 1708 0;
BA_ "xVWTP_Channel" BO_ 1708 1;
BA_ "VAGTP20_DynSetup" BO_ 1708 0;
BA_ "VAGTP20_DynConnection" BO_ 1708 0;
BA_ "GenMsgCycleTimeFast" BO_ 1708 50;
BA_ "GenMsgNoIalSupport" BO_ 1708 0;
BA_ "VAGTP20_StatConnection" BO_ 1708 0;
BA_ "NWM-Botschaft" BO_ 1708 0;
BA_ "GenMsgSendType" BO_ 1762 7;
BA_ "xVWTP_Setup" BO_ 1762 0;
BA_ "xVWTP_Channel" BO_ 1762 1;
BA_ "VAGTP20_DynSetup" BO_ 1762 0;
BA_ "VAGTP20_DynConnection" BO_ 1762 0;
BA_ "GenMsgCycleTimeFast" BO_ 1762 50;
BA_ "GenMsgNoIalSupport" BO_ 1762 0;
BA_ "VAGTP20_StatConnection" BO_ 1762 0;
BA_ "NWM-Botschaft" BO_ 1762 0;
BA_ "GenMsgSendType" BO_ 1761 7;
BA_ "xVWTP_Setup" BO_ 1761 0;
BA_ "xVWTP_Channel" BO_ 1761 1;
BA_ "VAGTP20_DynSetup" BO_ 1761 0;
BA_ "VAGTP20_DynConnection" BO_ 1761 0;
BA_ "GenMsgCycleTimeFast" BO_ 1761 50;
BA_ "GenMsgNoIalSupport" BO_ 1761 0;
BA_ "VAGTP20_StatConnection" BO_ 1761 0;
BA_ "NWM-Botschaft" BO_ 1761 0;
BA_ "GenMsgSendType" BO_ 1760 7;
BA_ "xVWTP_Setup" BO_ 1760 0;
BA_ "xVWTP_Channel" BO_ 1760 1;
BA_ "VAGTP20_DynSetup" BO_ 1760 0;
BA_ "VAGTP20_DynConnection" BO_ 1760 0;
BA_ "GenMsgCycleTimeFast" BO_ 1760 50;
BA_ "GenMsgNoIalSupport" BO_ 1760 0;
BA_ "VAGTP20_StatConnection" BO_ 1760 0;
BA_ "NWM-Botschaft" BO_ 1760 0;
BA_ "GenMsgSendType" BO_ 1698 7;
BA_ "xVWTP_Setup" BO_ 1698 0;
BA_ "xVWTP_Channel" BO_ 1698 1;
BA_ "VAGTP20_DynSetup" BO_ 1698 0;
BA_ "VAGTP20_DynConnection" BO_ 1698 0;
BA_ "GenMsgCycleTimeFast" BO_ 1698 50;
BA_ "GenMsgNoIalSupport" BO_ 1698 0;
BA_ "VAGTP20_StatConnection" BO_ 1698 0;
BA_ "NWM-Botschaft" BO_ 1698 0;
BA_ "GenMsgSendType" BO_ 1704 7;
BA_ "xVWTP_Setup" BO_ 1704 0;
BA_ "xVWTP_Channel" BO_ 1704 1;
BA_ "VAGTP20_DynSetup" BO_ 1704 0;
BA_ "VAGTP20_DynConnection" BO_ 1704 0;
BA_ "GenMsgCycleTimeFast" BO_ 1704 50;
BA_ "GenMsgNoIalSupport" BO_ 1704 0;
BA_ "VAGTP20_StatConnection" BO_ 1704 0;
BA_ "NWM-Botschaft" BO_ 1704 0;
BA_ "GenMsgSendType" BO_ 1710 7;
BA_ "xVWTP_Setup" BO_ 1710 0;
BA_ "xVWTP_Channel" BO_ 1710 1;
BA_ "VAGTP20_DynSetup" BO_ 1710 0;
BA_ "VAGTP20_DynConnection" BO_ 1710 0;
BA_ "GenMsgCycleTimeFast" BO_ 1710 50;
BA_ "GenMsgNoIalSupport" BO_ 1710 0;
BA_ "VAGTP20_StatConnection" BO_ 1710 0;
BA_ "NWM-Botschaft" BO_ 1710 0;
BA_ "GenMsgSendType" BO_ 1702 7;
BA_ "xVWTP_Setup" BO_ 1702 0;
BA_ "xVWTP_Channel" BO_ 1702 1;
BA_ "VAGTP20_DynSetup" BO_ 1702 0;
BA_ "VAGTP20_DynConnection" BO_ 1702 0;
BA_ "GenMsgCycleTimeFast" BO_ 1702 50;
BA_ "GenMsgNoIalSupport" BO_ 1702 0;
BA_ "VAGTP20_StatConnection" BO_ 1702 0;
BA_ "NWM-Botschaft" BO_ 1702 0;
BA_ "GenMsgSendType" BO_ 1785 7;
BA_ "xVWTP_Setup" BO_ 1785 0;
BA_ "xVWTP_Channel" BO_ 1785 1;
BA_ "VAGTP20_DynSetup" BO_ 1785 0;
BA_ "VAGTP20_DynConnection" BO_ 1785 0;
BA_ "GenMsgCycleTimeFast" BO_ 1785 50;
BA_ "GenMsgNoIalSupport" BO_ 1785 0;
BA_ "VAGTP20_StatConnection" BO_ 1785 0;
BA_ "NWM-Botschaft" BO_ 1785 0;
BA_ "GenMsgSendType" BO_ 1787 7;
BA_ "xVWTP_Setup" BO_ 1787 0;
BA_ "xVWTP_Channel" BO_ 1787 1;
BA_ "VAGTP20_DynSetup" BO_ 1787 0;
BA_ "VAGTP20_DynConnection" BO_ 1787 0;
BA_ "GenMsgCycleTimeFast" BO_ 1787 50;
BA_ "GenMsgNoIalSupport" BO_ 1787 0;
BA_ "VAGTP20_StatConnection" BO_ 1787 0;
BA_ "NWM-Botschaft" BO_ 1787 0;
BA_ "GenMsgSendType" BO_ 1781 7;
BA_ "xVWTP_Setup" BO_ 1781 0;
BA_ "xVWTP_Channel" BO_ 1781 1;
BA_ "VAGTP20_DynSetup" BO_ 1781 0;
BA_ "VAGTP20_DynConnection" BO_ 1781 0;
BA_ "GenMsgCycleTimeFast" BO_ 1781 50;
BA_ "GenMsgNoIalSupport" BO_ 1781 0;
BA_ "VAGTP20_StatConnection" BO_ 1781 0;
BA_ "NWM-Botschaft" BO_ 1781 0;
BA_ "GenMsgSendType" BO_ 1782 7;
BA_ "xVWTP_Setup" BO_ 1782 0;
BA_ "xVWTP_Channel" BO_ 1782 1;
BA_ "VAGTP20_DynSetup" BO_ 1782 0;
BA_ "VAGTP20_DynConnection" BO_ 1782 0;
BA_ "GenMsgCycleTimeFast" BO_ 1782 50;
BA_ "GenMsgNoIalSupport" BO_ 1782 0;
BA_ "VAGTP20_StatConnection" BO_ 1782 0;
BA_ "NWM-Botschaft" BO_ 1782 0;
BA_ "GenMsgSendType" BO_ 1783 7;
BA_ "xVWTP_Setup" BO_ 1783 0;
BA_ "xVWTP_Channel" BO_ 1783 1;
BA_ "VAGTP20_DynSetup" BO_ 1783 0;
BA_ "VAGTP20_DynConnection" BO_ 1783 0;
BA_ "GenMsgCycleTimeFast" BO_ 1783 50;
BA_ "GenMsgNoIalSupport" BO_ 1783 0;
BA_ "VAGTP20_StatConnection" BO_ 1783 0;
BA_ "NWM-Botschaft" BO_ 1783 0;
BA_ "GenMsgSendType" BO_ 1780 7;
BA_ "xVWTP_Setup" BO_ 1780 0;
BA_ "xVWTP_Channel" BO_ 1780 1;
BA_ "VAGTP20_DynSetup" BO_ 1780 0;
BA_ "VAGTP20_DynConnection" BO_ 1780 0;
BA_ "GenMsgCycleTimeFast" BO_ 1780 50;
BA_ "GenMsgNoIalSupport" BO_ 1780 0;
BA_ "VAGTP20_StatConnection" BO_ 1780 0;
BA_ "NWM-Botschaft" BO_ 1780 0;
BA_ "GenMsgSendType" BO_ 1697 7;
BA_ "xVWTP_Setup" BO_ 1697 0;
BA_ "xVWTP_Channel" BO_ 1697 1;
BA_ "VAGTP20_DynSetup" BO_ 1697 0;
BA_ "VAGTP20_DynConnection" BO_ 1697 0;
BA_ "GenMsgCycleTimeFast" BO_ 1697 50;
BA_ "GenMsgNoIalSupport" BO_ 1697 0;
BA_ "VAGTP20_StatConnection" BO_ 1697 0;
BA_ "NWM-Botschaft" BO_ 1697 0;
BA_ "GenMsgSendType" BO_ 1703 7;
BA_ "xVWTP_Setup" BO_ 1703 0;
BA_ "xVWTP_Channel" BO_ 1703 1;
BA_ "VAGTP20_DynSetup" BO_ 1703 0;
BA_ "VAGTP20_DynConnection" BO_ 1703 0;
BA_ "GenMsgCycleTimeFast" BO_ 1703 50;
BA_ "GenMsgNoIalSupport" BO_ 1703 0;
BA_ "VAGTP20_StatConnection" BO_ 1703 0;
BA_ "NWM-Botschaft" BO_ 1703 0;
BA_ "GenMsgSendType" BO_ 1705 7;
BA_ "xVWTP_Setup" BO_ 1705 0;
BA_ "xVWTP_Channel" BO_ 1705 1;
BA_ "VAGTP20_DynSetup" BO_ 1705 0;
BA_ "VAGTP20_DynConnection" BO_ 1705 0;
BA_ "GenMsgCycleTimeFast" BO_ 1705 50;
BA_ "GenMsgNoIalSupport" BO_ 1705 0;
BA_ "VAGTP20_StatConnection" BO_ 1705 0;
BA_ "NWM-Botschaft" BO_ 1705 0;
BA_ "GenMsgSendType" BO_ 1696 7;
BA_ "xVWTP_Setup" BO_ 1696 0;
BA_ "xVWTP_Channel" BO_ 1696 1;
BA_ "VAGTP20_DynSetup" BO_ 1696 0;
BA_ "VAGTP20_DynConnection" BO_ 1696 0;
BA_ "GenMsgCycleTimeFast" BO_ 1696 50;
BA_ "GenMsgNoIalSupport" BO_ 1696 0;
BA_ "VAGTP20_StatConnection" BO_ 1696 0;
BA_ "NWM-Botschaft" BO_ 1696 0;
BA_ "GenMsgSendType" BO_ 1701 7;
BA_ "xVWTP_Setup" BO_ 1701 0;
BA_ "xVWTP_Channel" BO_ 1701 1;
BA_ "VAGTP20_DynSetup" BO_ 1701 0;
BA_ "VAGTP20_DynConnection" BO_ 1701 0;
BA_ "GenMsgCycleTimeFast" BO_ 1701 50;
BA_ "GenMsgNoIalSupport" BO_ 1701 0;
BA_ "VAGTP20_StatConnection" BO_ 1701 0;
BA_ "NWM-Botschaft" BO_ 1701 0;
BA_ "GenMsgCycleTime" BO_ 1136 50;
BA_ "GenMsgSendType" BO_ 1136 0;
BA_ "xVWTP_Setup" BO_ 1136 0;
BA_ "xVWTP_Channel" BO_ 1136 0;
BA_ "VAGTP20_DynSetup" BO_ 1136 0;
BA_ "VAGTP20_DynConnection" BO_ 1136 0;
BA_ "GenMsgNoIalSupport" BO_ 1136 0;
BA_ "VAGTP20_StatConnection" BO_ 1136 0;
BA_ "NWM-Botschaft" BO_ 1136 0;
BA_ "GenMsgCycleTime" BO_ 1397 200;
BA_ "GenMsgSendType" BO_ 1397 5;
BA_ "xVWTP_Setup" BO_ 1397 0;
BA_ "xVWTP_Channel" BO_ 1397 0;
BA_ "VAGTP20_DynSetup" BO_ 1397 0;
BA_ "VAGTP20_DynConnection" BO_ 1397 0;
BA_ "GenMsgNoIalSupport" BO_ 1397 0;
BA_ "VAGTP20_StatConnection" BO_ 1397 0;
BA_ "NWM-Botschaft" BO_ 1397 0;
BA_ "GenMsgCycleTime" BO_ 1393 500;
BA_ "GenMsgSendType" BO_ 1393 0;
BA_ "xVWTP_Setup" BO_ 1393 0;
BA_ "xVWTP_Channel" BO_ 1393 0;
BA_ "VAGTP20_DynSetup" BO_ 1393 0;
BA_ "VAGTP20_DynConnection" BO_ 1393 0;
BA_ "GenMsgNoIalSupport" BO_ 1393 0;
BA_ "VAGTP20_StatConnection" BO_ 1393 0;
BA_ "NWM-Botschaft" BO_ 1393 0;
BA_ "GenMsgCycleTime" BO_ 1429 800;
BA_ "GenMsgSendType" BO_ 1429 5;
BA_ "xVWTP_Setup" BO_ 1429 0;
BA_ "xVWTP_Channel" BO_ 1429 0;
BA_ "VAGTP20_DynSetup" BO_ 1429 0;
BA_ "VAGTP20_DynConnection" BO_ 1429 0;
BA_ "GenMsgNoIalSupport" BO_ 1429 0;
BA_ "VAGTP20_StatConnection" BO_ 1429 0;
BA_ "NWM-Botschaft" BO_ 1429 0;
BA_ "GenMsgSendType" BO_ 337 7;
BA_ "xVWTP_Setup" BO_ 337 0;
BA_ "xVWTP_Channel" BO_ 337 0;
BA_ "VAGTP20_DynSetup" BO_ 337 0;
BA_ "VAGTP20_DynConnection" BO_ 337 0;
BA_ "GenMsgCycleTimeFast" BO_ 337 20;
BA_ "GenMsgNoIalSupport" BO_ 337 0;
BA_ "VAGTP20_StatConnection" BO_ 337 0;
BA_ "NWM-Botschaft" BO_ 337 0;
BA_ "GenSigSendType" SG_ 1039 NMSH_SleepInd 3;
BA_ "GenSigSendType" SG_ 1039 NMSH_SleepAck 3;
BA_ "GenSigSendType" SG_ 1039 NMSH_SH_LED 3;
BA_ "GenSigSendType" SG_ 1039 NMSH_Receiver 3;
BA_ "GenSigSendType" SG_ 1039 NMSH_NWake 3;
BA_ "GenSigSendType" SG_ 1039 NMSH_Kl_30_Reset 3;
BA_ "GenSigSendType" SG_ 1039 NMSH_Funk 3;
BA_ "GenSigSendType" SG_ 1039 NMSH_Fkt_Nachlauf 3;
BA_ "GenSigSendType" SG_ 1039 NMSH_CmdRing 3;
BA_ "GenSigSendType" SG_ 1039 NMSH_CmdLimpHome 3;
BA_ "GenSigSendType" SG_ 1039 NMSH_CmdAlive 3;
BA_ "GenSigSendType" SG_ 1039 NMSH_CAN 3;
BA_ "GenSigSendType" SG_ 1033 NMRK_SleepInd 3;
BA_ "GenSigSendType" SG_ 1033 NMRK_SleepAck 3;
BA_ "GenSigSendType" SG_ 1033 NMRK_Receiver 3;
BA_ "GenSigSendType" SG_ 1033 NMRK_NWake 3;
BA_ "GenSigSendType" SG_ 1033 NMRK_Kl_30_Reset 3;
BA_ "GenSigSendType" SG_ 1033 NMRK_Fkt_Nachlauf 3;
BA_ "GenSigSendType" SG_ 1033 NMRK_CmdRing 3;
BA_ "GenSigSendType" SG_ 1033 NMRK_CmdLimpHome 3;
BA_ "GenSigSendType" SG_ 1033 NMRK_CmdAlive 3;
BA_ "GenSigSendType" SG_ 1033 NMRK_CAN 3;
BA_ "GenSigSendType" SG_ 1038 NMPTC_SleepInd 3;
BA_ "GenSigSendType" SG_ 1038 NMPTC_SleepAck 3;
BA_ "GenSigSendType" SG_ 1038 NMPTC_Receiver 3;
BA_ "GenSigSendType" SG_ 1038 NMPTC_NWake 3;
BA_ "GenSigSendType" SG_ 1038 NMPTC_Kl_30_Reset 3;
BA_ "GenSigSendType" SG_ 1038 NMPTC_Fkt_Nachlauf 3;
BA_ "GenSigSendType" SG_ 1038 NMPTC_CmdRing 3;
BA_ "GenSigSendType" SG_ 1038 NMPTC_CmdLimpHome 3;
BA_ "GenSigSendType" SG_ 1038 NMPTC_CmdAlive 3;
BA_ "GenSigSendType" SG_ 1038 NMPTC_CAN 3;
BA_ "GenSigSendType" SG_ 1050 NMMFG_Warnblinker 3;
BA_ "GenSigSendType" SG_ 1050 NMMFG_Standlicht 3;
BA_ "GenSigSendType" SG_ 1050 NMMFG_SleepInd 3;
BA_ "GenSigSendType" SG_ 1050 NMMFG_SleepAck 3;
BA_ "GenSigSendType" SG_ 1050 NMMFG_Receiver 3;
BA_ "GenSigSendType" SG_ 1050 NMMFG_re_Parklicht 3;
BA_ "GenSigSendType" SG_ 1050 NMMFG_NWake 3;
BA_ "GenSigSendType" SG_ 1050 NMMFG_Lichthupe 3;
BA_ "GenSigSendType" SG_ 1050 NMMFG_li_Parklicht 3;
BA_ "GenSigSendType" SG_ 1050 NMMFG_Kl_30_Reset 3;
BA_ "GenSigSendType" SG_ 1050 NMMFG_Fkt_Nachlauf 3;
BA_ "GenSigSendType" SG_ 1050 NMMFG_Fernbedienung 3;
BA_ "GenSigSendType" SG_ 1050 NMMFG_Fanfare 3;
BA_ "GenSigSendType" SG_ 1050 NMMFG_CmdRing 3;
BA_ "GenSigSendType" SG_ 1050 NMMFG_CmdLimpHome 3;
BA_ "GenSigSendType" SG_ 1050 NMMFG_CmdAlive 3;
BA_ "GenSigSendType" SG_ 1050 NMMFG_CAN 3;
BA_ "GenSigSendType" SG_ 1050 NMMFG_Blinkalarm 3;
BA_ "GenSigSendType" SG_ 1050 NMMFG_Bel_Innenraum 3;
BA_ "GenSigSendType" SG_ 1050 NMMFG_Bel_Fussraum 3;
BA_ "GenSigSendType" SG_ 1045 NMMem_BF_SleepInd 3;
BA_ "GenSigSendType" SG_ 1045 NMMem_BF_SleepAck 3;
BA_ "GenSigSendType" SG_ 1045 NMMem_BF_Receiver 3;
BA_ "GenSigSendType" SG_ 1045 NMMem_BF_NWake 3;
BA_ "GenSigSendType" SG_ 1045 NMMem_BF_Kl_30_Reset 3;
BA_ "GenSigSendType" SG_ 1045 NMMem_BF_Fkt_Nachlauf 3;
BA_ "GenSigSendType" SG_ 1045 NMMem_BF_CmdRing 3;
BA_ "GenSigSendType" SG_ 1045 NMMem_BF_CmdLimpHome 3;
BA_ "GenSigSendType" SG_ 1045 NMMem_BF_CmdAlive 3;
BA_ "GenSigSendType" SG_ 1045 NMMem_BF_CAN 3;
BA_ "GenSigSendType" SG_ 1030 NMMEM_SleepInd 3;
BA_ "GenSigSendType" SG_ 1030 NMMEM_SleepAck 3;
BA_ "GenSigSendType" SG_ 1030 NMMEM_Receiver 3;
BA_ "GenSigSendType" SG_ 1030 NMMEM_NWake 3;
BA_ "GenSigSendType" SG_ 1030 NMMEM_Memory_S 3;
BA_ "GenSigSendType" SG_ 1030 NMMEM_Memory_P4 3;
BA_ "GenSigSendType" SG_ 1030 NMMEM_Memory_P3 3;
BA_ "GenSigSendType" SG_ 1030 NMMEM_Memory_P2 3;
BA_ "GenSigSendType" SG_ 1030 NMMEM_Memory_P1 3;
BA_ "GenSigSendType" SG_ 1030 NMMEM_Kl_30_Reset 3;
BA_ "GenSigSendType" SG_ 1030 NMMEM_Fkt_Nachlauf 3;
BA_ "GenSigSendType" SG_ 1030 NMMEM_CmdRing 3;
BA_ "GenSigSendType" SG_ 1030 NMMEM_CmdLimpHome 3;
BA_ "GenSigSendType" SG_ 1030 NMMEM_CmdAlive 3;
BA_ "GenSigSendType" SG_ 1030 NMMEM_CAN 3;
BA_ "GenSigSendType" SG_ 1035 NMGW_K_SleepInd 3;
BA_ "GenSigSendType" SG_ 1035 NMGW_K_SleepAck 3;
BA_ "GenSigSendType" SG_ 1035 NMGW_K_Receiver 3;
BA_ "GenSigSendType" SG_ 1035 NMGW_K_MOST_Diag 3;
BA_ "GenSigSendType" SG_ 1035 NMGW_K_MOST 3;
BA_ "GenSigSendType" SG_ 1035 NMGW_K_Komfort 3;
BA_ "GenSigSendType" SG_ 1035 NMGW_K_Kombi 3;
BA_ "GenSigSendType" SG_ 1035 NMGW_K_Klemme_15 3;
BA_ "GenSigSendType" SG_ 1035 NMGW_K_Kl_30_Reset 3;
BA_ "GenSigSendType" SG_ 1035 NMGW_K_Infotainment 3;
BA_ "GenSigSendType" SG_ 1035 NMGW_K_Fkt_Nachlauf 3;
BA_ "GenSigSendType" SG_ 1035 NMGW_K_Diagnose 3;
BA_ "GenSigSendType" SG_ 1035 NMGW_K_CmdRing 3;
BA_ "GenSigSendType" SG_ 1035 NMGW_K_CmdLimpHome 3;
BA_ "GenSigSendType" SG_ 1035 NMGW_K_CmdAlive 3;
BA_ "GenSigSendType" SG_ 1035 NMGW_K_CAN 3;
BA_ "GenSigSendType" SG_ 1036 NMCL_SleepInd 3;
BA_ "GenSigSendType" SG_ 1036 NMCL_SleepAck 3;
BA_ "GenSigSendType" SG_ 1036 NMCL_Receiver 3;
BA_ "GenSigSendType" SG_ 1036 NMCL_NWake 3;
BA_ "GenSigSendType" SG_ 1036 NMCL_Kl_30_Reset 3;
BA_ "GenSigSendType" SG_ 1036 NMCL_Fkt_Nachlauf 3;
BA_ "GenSigSendType" SG_ 1036 NMCL_ext_Standhzg 3;
BA_ "GenSigSendType" SG_ 1036 NMCL_CmdRing 3;
BA_ "GenSigSendType" SG_ 1036 NMCL_CmdLimpHome 3;
BA_ "GenSigSendType" SG_ 1036 NMCL_CmdAlive 3;
BA_ "GenSigSendType" SG_ 1036 NMCL_CAN 3;
BA_ "GenSigSendType" SG_ 1024 NMBS_Warnblinker 3;
BA_ "GenSigSendType" SG_ 1024 NMBS_Standlicht 3;
BA_ "GenSigSendType" SG_ 1024 NMBS_SleepInd 3;
BA_ "GenSigSendType" SG_ 1024 NMBS_SleepAck 3;
BA_ "GenSigSendType" SG_ 1024 NMBS_Signalhorn 3;
BA_ "GenSigSendType" SG_ 1024 NMBS_Receiver 3;
BA_ "GenSigSendType" SG_ 1024 NMBS_NWake 3;
BA_ "GenSigSendType" SG_ 1024 NMBS_MH_Kontakt 3;
BA_ "GenSigSendType" SG_ 1024 NMBS_Lastman 3;
BA_ "GenSigSendType" SG_ 1024 NMBS_Klemme15 3;
BA_ "GenSigSendType" SG_ 1024 NMBS_Kl_30_Reset 3;
BA_ "GenSigSendType" SG_ 1024 NMBS_HR_Drehfalle 3;
BA_ "GenSigSendType" SG_ 1024 NMBS_Home_Fkt 3;
BA_ "GenSigSendType" SG_ 1024 NMBS_HL_Drehfalle 3;
BA_ "GenSigSendType" SG_ 1024 NMBS_HD_Vorraste 3;
BA_ "GenSigSendType" SG_ 1024 NMBS_HD_Innentaster 3;
BA_ "GenSigSendType" SG_ 1024 NMBS_HD_Hauptraste 3;
BA_ "GenSigSendType" SG_ 1024 NMBS_HD_Grifftaster 3;
BA_ "GenSigSendType" SG_ 1024 NMBS_FT_Drehfalle 3;
BA_ "GenSigSendType" SG_ 1024 NMBS_Fkt_Nachlauf 3;
BA_ "GenSigSendType" SG_ 1024 NMBS_Dimmsignal 3;
BA_ "GenSigSendType" SG_ 1024 NMBS_CmdRing 3;
BA_ "GenSigSendType" SG_ 1024 NMBS_CmdLimpHome 3;
BA_ "GenSigSendType" SG_ 1024 NMBS_CmdAlive 3;
BA_ "GenSigSendType" SG_ 1024 NMBS_CAN 3;
BA_ "GenSigSendType" SG_ 1024 NMBS_BT_Drehfalle 3;
BA_ "GenSigSendType" SG_ 1024 NMBS_Bremslicht 3;
BA_ "GenSigSendType" SG_ 1037 NMAPS_SleepInd 3;
BA_ "GenSigSendType" SG_ 1037 NMAPS_SleepAck 3;
BA_ "GenSigSendType" SG_ 1037 NMAPS_Receiver 3;
BA_ "GenSigSendType" SG_ 1037 NMAPS_NWake 3;
BA_ "GenSigSendType" SG_ 1037 NMAPS_Kl_30_Reset 3;
BA_ "GenSigSendType" SG_ 1037 NMAPS_Fkt_Nachlauf 3;
BA_ "GenSigSendType" SG_ 1037 NMAPS_CmdRing 3;
BA_ "GenSigSendType" SG_ 1037 NMAPS_CmdLimpHome 3;
BA_ "GenSigSendType" SG_ 1037 NMAPS_CmdAlive 3;
BA_ "GenSigSendType" SG_ 1037 NMAPS_CAN 3;
BA_ "GenSigSendType" SG_ 1044 NMANH_SleepInd 3;
BA_ "GenSigSendType" SG_ 1044 NMANH_SleepAck 3;
BA_ "GenSigSendType" SG_ 1044 NMANH_Receiver 3;
BA_ "GenSigSendType" SG_ 1044 NMANH_NWake 3;
BA_ "GenSigSendType" SG_ 1044 NMANH_Kl_30_Reset 3;
BA_ "GenSigSendType" SG_ 1044 NMANH_CmdRing 3;
BA_ "GenSigSendType" SG_ 1044 NMANH_CmdLimpHome 3;
BA_ "GenSigSendType" SG_ 1044 NMANH_CmdAlive 3;
BA_ "GenSigSendType" SG_ 1044 NMANH_CAN 3;
BA_ "GenSigSendType" SG_ 1044 NMANG_Fkt_Nachlauf 3;
BA_ "GenSigSendType" SG_ 1365 MO7_V_Begrenz 7;
BA_ "GenSigSendType" SG_ 1365 MO7_V_Begr_akt 7;
BA_ "GenSigSendType" SG_ 1365 MO7_Sleep_Ind 7;
BA_ "GenSigSendType" SG_ 1365 MO7_Rueck_LLDz 7;
BA_ "GenSigSendType" SG_ 1365 MO7_PTC 7;
BA_ "GenSigSendType" SG_ 1365 MO7_Oeltemperatur 7;
BA_ "GenSigSendType" SG_ 1365 MO7_LL_Status 7;
BA_ "GenSigSendType" SG_ 1365 MO7_Hoeheninfo 7;
BA_ "GenSigSendType" SG_ 1365 MO7_Gradient_Vorz 7;
BA_ "GenSigSendType" SG_ 1365 MO7_Gradient_Drehz 7;
BA_ "GenSigSendType" SG_ 1365 MO7_FehlerSp 7;
BA_ "GenSigSendType" SG_ 1365 MO7_DFM 7;
BA_ "SignalRepeatDeactivation" SG_ 1473 MLT_Symbol 5;
BA_ "GenSigSendType" SG_ 1473 MLT_Symbol 4;
BA_ "SignalRepeatDeactivation" SG_ 1473 MLT_DW_VZ 5;
BA_ "GenSigSendType" SG_ 1473 MLT_DW_VZ 4;
BA_ "SignalRepeatDeactivation" SG_ 1473 MLT_DW_Ticks 5;
BA_ "GenSigSendType" SG_ 1473 MLT_DW_Ticks 4;
BA_ "GenSigSendType" SG_ 1475 ML1_Ziel 3;
BA_ "GenSigSendType" SG_ 1475 ML1_DW_VZ 3;
BA_ "GenSigSendType" SG_ 1475 ML1_DW_Ticks 3;
BA_ "GenSigSendType" SG_ 1475 ML1_Befehl 3;
BA_ "GenSigSendType" SG_ 889 MG1_Zaehler 3;
BA_ "GenSigSendType" SG_ 889 MG1_WischenStufe_2 3;
BA_ "GenSigSendType" SG_ 889 MG1_WischenStufe_1 3;
BA_ "GenSigSendType" SG_ 889 MG1_Warnblinker 3;
BA_ "GenSigSendType" SG_ 889 MG1_Typ3 3;
BA_ "GenSigSendType" SG_ 889 MG1_Typ2 3;
BA_ "GenSigSendType" SG_ 889 MG1_Typ1 3;
BA_ "GenSigSendType" SG_ 889 MG1_Typ0 3;
BA_ "GenSigSendType" SG_ 889 MG1_Tipwischen 3;
BA_ "GenSigSendType" SG_ 889 MG1_Summer 3;
BA_ "GenSigSendType" SG_ 889 MG1_Standlicht 3;
BA_ "GenSigSendType" SG_ 889 MG1_Signalhorn 3;
BA_ "GenSigSendType" SG_ 889 MG1_Parklicht_rechts 3;
BA_ "GenSigSendType" SG_ 889 MG1_Parklicht_links 3;
BA_ "GenSigSendType" SG_ 889 MG1_Motorweiterlauf 3;
BA_ "GenSigSendType" SG_ 889 MG1_Lichthupe 3;
BA_ "GenSigSendType" SG_ 889 MG1_KD_Fehler 3;
BA_ "GenSigSendType" SG_ 889 MG1_Interm_Fernlicht 3;
BA_ "GenSigSendType" SG_ 889 MG1_Innenraumbel 3;
BA_ "GenSigSendType" SG_ 889 MG1_Heckwaschen 3;
BA_ "GenSigSendType" SG_ 889 MG1_Heckintervall 3;
BA_ "GenSigSendType" SG_ 889 MG1_Fussraumbel 3;
BA_ "GenSigSendType" SG_ 889 MG1_Frontwaschen 3;
BA_ "GenSigSendType" SG_ 889 MG1_Frontintervall 3;
BA_ "GenSigSendType" SG_ 889 MG1_FH_FT_Tief 3;
BA_ "GenSigSendType" SG_ 889 MG1_FH_FT_Hoch 3;
BA_ "GenSigSendType" SG_ 889 MG1_FH_BT_Tief 3;
BA_ "GenSigSendType" SG_ 889 MG1_FH_BT_Hoch 3;
BA_ "GenSigSendType" SG_ 889 MG1_Fernlicht 3;
BA_ "GenSigSendType" SG_ 889 MG1_Fernbedienung 3;
BA_ "GenSigSendType" SG_ 889 MG1_Fahrlicht 3;
BA_ "GenSigSendType" SG_ 889 MG1_Checksumme 3;
BA_ "GenSigSendType" SG_ 889 MG1_Blk_rechts 3;
BA_ "GenSigSendType" SG_ 889 MG1_Blk_links 3;
BA_ "GenSigSendType" SG_ 889 MG1_Anlasssperre 3;
BA_ "GenSigSendType" SG_ 889 MG1_Anlasser 3;
BA_ "GenSigSendType" SG_ 889 MG1_Alarm_Fanfare 3;
BA_ "GenSigSendType" SG_ 889 MG1_Alarm_Blinker 3;
BA_ "SignalRepeatActivation" SG_ 1317 SHM_SL 5;
BA_ "SignalRepeatDeactivation" SG_ 1317 SHM_SL 5;
BA_ "GenSigSendType" SG_ 1317 SHM_SL 6;
BA_ "SignalRepeatActivation" SG_ 1317 SHM_SH_SL 5;
BA_ "SignalRepeatDeactivation" SG_ 1317 SHM_SH_SL 5;
BA_ "GenSigSendType" SG_ 1317 SHM_SH_SL 6;
BA_ "SignalRepeatActivation" SG_ 1317 SHM_SH 5;
BA_ "SignalRepeatDeactivation" SG_ 1317 SHM_SH 5;
BA_ "GenSigSendType" SG_ 1317 SHM_SH 6;
BA_ "SignalRepeatActivation" SG_ 1317 SHM_Restdauer 5;
BA_ "SignalRepeatDeactivation" SG_ 1317 SHM_Restdauer 5;
BA_ "GenSigSendType" SG_ 1317 SHM_Restdauer 6;
BA_ "SignalRepeatActivation" SG_ 1317 SHM_MVW 5;
BA_ "SignalRepeatDeactivation" SG_ 1317 SHM_MVW 5;
BA_ "GenSigSendType" SG_ 1317 SHM_MVW 6;
BA_ "GenSigSendType" SG_ 1297 ME1_SP_MEM_Default 3;
BA_ "GenSigSendType" SG_ 1297 ME1_Sitzhzg_Stat 3;
BA_ "GenSigSendType" SG_ 1297 ME1_SG_Init 3;
BA_ "GenSigSendType" SG_ 1297 ME1_res_Sp_Abs 3;
BA_ "GenSigSendType" SG_ 1297 ME1_Pos3 3;
BA_ "GenSigSendType" SG_ 1297 ME1_Pos2 3;
BA_ "GenSigSendType" SG_ 1297 ME1_Pos1 3;
BA_ "GenSigSendType" SG_ 1297 ME1_Pos_speichern 3;
BA_ "GenSigSendType" SG_ 1297 ME1_Pos_anfahren 3;
BA_ "GenSigSendType" SG_ 1297 ME1_KD_Fehler 3;
BA_ "GenSigSendType" SG_ 1297 ME1_Funk_Tasten 3;
BA_ "GenSigSendType" SG_ 1297 ME1_FFB_Pos3 3;
BA_ "GenSigSendType" SG_ 1297 ME1_FFB_Pos2 3;
BA_ "GenSigSendType" SG_ 1297 ME1_FFB_Pos1 3;
BA_ "GenSigSendType" SG_ 1297 ME1_Buzzer 3;
BA_ "GenSigSendType" SG_ 1297 ME1_Abb_Pos_anf 3;
BA_ "GenSigSendType" SG_ 1301 MB1_Sitzhzg_Stat 3;
BA_ "GenSigSendType" SG_ 1301 MB1_Pos4 3;
BA_ "GenSigSendType" SG_ 1301 MB1_Pos3 3;
BA_ "GenSigSendType" SG_ 1301 MB1_Pos2 3;
BA_ "GenSigSendType" SG_ 1301 MB1_Pos1 3;
BA_ "GenSigSendType" SG_ 1301 MB1_Pos_speichern 3;
BA_ "GenSigSendType" SG_ 1301 MB1_Pos_anfahren 3;
BA_ "GenSigSendType" SG_ 1301 MB1_KD_Fehler 3;
BA_ "GenSigSendType" SG_ 1301 MB1_Buzzer 3;
BA_ "GenSigSendType" SG_ 705 LS1_WischenStufe_2 3;
BA_ "GenSigSendType" SG_ 705 LS1_WischenStufe_1 3;
BA_ "GenSigSendType" SG_ 705 LS1_Winterstellung 3;
BA_ "GenSigSendType" SG_ 705 LS1_Tipwischen 3;
BA_ "GenSigSendType" SG_ 705 LS1_Signalhorn 3;
BA_ "GenSigSendType" SG_ 705 LS1_Servicestellung 3;
BA_ "GenSigSendType" SG_ 705 LS1_Parklicht_rechts 3;
BA_ "GenSigSendType" SG_ 705 LS1_Parklicht_links 3;
BA_ "GenSigSendType" SG_ 705 LS1_MFL_vorhanden 3;
BA_ "GenSigSendType" SG_ 705 LS1_MFA_vorhanden 3;
BA_ "GenSigSendType" SG_ 705 LS1_MFA_Tasten 3;
BA_ "GenSigSendType" SG_ 705 LS1_LSZ_zurueck 3;
BA_ "GenSigSendType" SG_ 705 LS1_LSZ_vor 3;
BA_ "GenSigSendType" SG_ 705 LS1_LSY_unten 3;
BA_ "GenSigSendType" SG_ 705 LS1_LSY_oben 3;
BA_ "GenSigSendType" SG_ 705 LS1_Lichthupe 3;
BA_ "GenSigSendType" SG_ 705 LS1_LHeizung_aktiv 3;
BA_ "GenSigSendType" SG_ 705 LS1_KD_Fehler 3;
BA_ "GenSigSendType" SG_ 705 LS1_Intervallstufen 3;
BA_ "GenSigSendType" SG_ 705 LS1_Intervall 3;
BA_ "GenSigSendType" SG_ 705 LS1_Heckwaschen 3;
BA_ "GenSigSendType" SG_ 705 LS1_Heckintervall 3;
BA_ "GenSigSendType" SG_ 705 LS1_Frontwaschen 3;
BA_ "GenSigSendType" SG_ 705 LS1_Fernlicht 3;
BA_ "GenSigSendType" SG_ 705 LS1_Easy_Entry_LS 3;
BA_ "GenSigSendType" SG_ 705 LS1_Blk_rechts 3;
BA_ "GenSigSendType" SG_ 705 LS1_Blk_links 3;
BA_ "GenSigSendType" SG_ 705 LS1_Bew_Frontwaschen 3;
BA_ "GenSigSendType" SG_ 705 LS1_BC_Up_Cursor 3;
BA_ "GenSigSendType" SG_ 705 LS1_BC_Reset 3;
BA_ "GenSigSendType" SG_ 705 LS1_BC_Down_Cursor 3;
BA_ "SignalRepeatDeactivation" SG_ 1585 LI2_Standl_HR_def 5;
BA_ "GenSigSendType" SG_ 1585 LI2_Standl_HR_def 4;
BA_ "SignalRepeatDeactivation" SG_ 1585 LI2_Standl_HL_def 5;
BA_ "GenSigSendType" SG_ 1585 LI2_Standl_HL_def 4;
BA_ "SignalRepeatDeactivation" SG_ 1585 LI2_Rueckf_HR_def 5;
BA_ "GenSigSendType" SG_ 1585 LI2_Rueckf_HR_def 4;
BA_ "SignalRepeatDeactivation" SG_ 1585 LI2_Rueckf_HL_def 5;
BA_ "GenSigSendType" SG_ 1585 LI2_Rueckf_HL_def 4;
BA_ "SignalRepeatDeactivation" SG_ 1585 LI2_Parkl_VR_def 5;
BA_ "GenSigSendType" SG_ 1585 LI2_Parkl_VR_def 4;
BA_ "SignalRepeatDeactivation" SG_ 1585 LI2_Parkl_VL_def 5;
BA_ "GenSigSendType" SG_ 1585 LI2_Parkl_VL_def 4;
BA_ "SignalRepeatDeactivation" SG_ 1585 LI2_Nebel_VR_def 5;
BA_ "GenSigSendType" SG_ 1585 LI2_Nebel_VR_def 4;
BA_ "SignalRepeatDeactivation" SG_ 1585 LI2_Nebel_VL_def 5;
BA_ "GenSigSendType" SG_ 1585 LI2_Nebel_VL_def 4;
BA_ "SignalRepeatDeactivation" SG_ 1585 LI2_Nebel_HR_def 5;
BA_ "GenSigSendType" SG_ 1585 LI2_Nebel_HR_def 4;
BA_ "SignalRepeatDeactivation" SG_ 1585 LI2_Nebel_HL_def 5;
BA_ "GenSigSendType" SG_ 1585 LI2_Nebel_HL_def 4;
BA_ "GenSigSendType" SG_ 1585 LI2_Kurv_R_Licht_def 3;
BA_ "GenSigSendType" SG_ 1585 LI2_Kurv_L_Licht_def 3;
BA_ "SignalRepeatDeactivation" SG_ 1585 LI2_Kennzl_def 5;
BA_ "GenSigSendType" SG_ 1585 LI2_Kennzl_def 4;
BA_ "SignalRepeatDeactivation" SG_ 1585 LI2_Fernl_VR_def 5;
BA_ "GenSigSendType" SG_ 1585 LI2_Fernl_VR_def 4;
BA_ "SignalRepeatDeactivation" SG_ 1585 LI2_Fernl_VL_def 5;
BA_ "GenSigSendType" SG_ 1585 LI2_Fernl_VL_def 4;
BA_ "SignalRepeatDeactivation" SG_ 1585 LI2_Bremsl_HR_def 5;
BA_ "GenSigSendType" SG_ 1585 LI2_Bremsl_HR_def 4;
BA_ "SignalRepeatDeactivation" SG_ 1585 LI2_Bremsl_HL_def 5;
BA_ "GenSigSendType" SG_ 1585 LI2_Bremsl_HL_def 4;
BA_ "SignalRepeatDeactivation" SG_ 1585 LI2_Blk_VR_def 5;
BA_ "GenSigSendType" SG_ 1585 LI2_Blk_VR_def 4;
BA_ "SignalRepeatDeactivation" SG_ 1585 LI2_Blk_VL_def 5;
BA_ "GenSigSendType" SG_ 1585 LI2_Blk_VL_def 4;
BA_ "SignalRepeatDeactivation" SG_ 1585 LI2_Blk_Seite_R_def 5;
BA_ "GenSigSendType" SG_ 1585 LI2_Blk_Seite_R_def 4;
BA_ "SignalRepeatDeactivation" SG_ 1585 LI2_BLk_Seite_L_def 5;
BA_ "GenSigSendType" SG_ 1585 LI2_BLk_Seite_L_def 4;
BA_ "SignalRepeatDeactivation" SG_ 1585 LI2_Blk_HR_def 5;
BA_ "GenSigSendType" SG_ 1585 LI2_Blk_HR_def 4;
BA_ "SignalRepeatDeactivation" SG_ 1585 LI2_Blk_HL_def 5;
BA_ "GenSigSendType" SG_ 1585 LI2_Blk_HL_def 4;
BA_ "SignalRepeatDeactivation" SG_ 1585 LI2_Abblend_VR_def 5;
BA_ "GenSigSendType" SG_ 1585 LI2_Abblend_VR_def 4;
BA_ "SignalRepeatDeactivation" SG_ 1585 LI2_Abblend_VL_def 5;
BA_ "GenSigSendType" SG_ 1585 LI2_Abblend_VL_def 4;
BA_ "SignalRepeatDeactivation" SG_ 1585 LI2_3Bremsl_def 5;
BA_ "GenSigSendType" SG_ 1585 LI2_3Bremsl_def 4;
BA_ "GenSigSendType" SG_ 1329 LIA_Zaehler 3;
BA_ "GenSigSendType" SG_ 1329 LIA_Warnblk_Status 3;
BA_ "GenSigSendType" SG_ 1329 LIA_Warnblink 3;
BA_ "GenSigSendType" SG_ 1329 LIA_Tagesfahrlicht 3;
BA_ "GenSigSendType" SG_ 1329 LIA_Standlicht 3;
BA_ "GenSigSendType" SG_ 1329 LIA_Rueckfahrlicht 3;
BA_ "GenSigSendType" SG_ 1329 LIA_Pruefsumme 3;
BA_ "GenSigSendType" SG_ 1329 LIA_Parklicht_rechts 3;
BA_ "GenSigSendType" SG_ 1329 LIA_Parklicht_links 3;
BA_ "GenSigSendType" SG_ 1329 LIA_Nebelschluss 3;
BA_ "GenSigSendType" SG_ 1329 LIA_Nebellicht 3;
BA_ "GenSigSendType" SG_ 1329 LIA_Fernlicht 3;
BA_ "GenSigSendType" SG_ 1329 LIA_Blk_rechts 3;
BA_ "GenSigSendType" SG_ 1329 LIA_Blk_R_Kontrolle 3;
BA_ "GenSigSendType" SG_ 1329 LIA_Blk_links 3;
BA_ "GenSigSendType" SG_ 1329 LIA_Blk_L_Kontrolle 3;
BA_ "GenSigSendType" SG_ 1329 LIA_BLK_Frequenz 3;
BA_ "GenSigSendType" SG_ 1329 LIA_Anhaenger 3;
BA_ "GenSigSendType" SG_ 1329 LIA_AFL_Schalter 3;
BA_ "GenSigSendType" SG_ 1329 LIA_Abblendlicht 3;
BA_ "GenSigSendType" SG_ 963 LW1_Zaehler 7;
BA_ "GenSigSendType" SG_ 963 LW1_Vorzeichen 7;
BA_ "GenSigSendType" SG_ 963 LW1_Quelle_Init 7;
BA_ "GenSigSendType" SG_ 963 LW1_Pruefsumme 7;
BA_ "GenSigSendType" SG_ 963 LW1_Lenkradwinkel 7;
BA_ "GenSigSendType" SG_ 963 LW1_Kodierdaten 7;
BA_ "GenSigSendType" SG_ 963 LW1_KL30_Ausfall 7;
BA_ "GenSigSendType" SG_ 963 LW1_Int_Status 7;
BA_ "GenSigSendType" SG_ 963 LW1_ID 7;
BA_ "GenSigSendType" SG_ 963 LW1_Geschwindigkeit 7;
BA_ "GenSigSendType" SG_ 963 LW1_Geschw_Vorzeichen 7;
BA_ "GenSigSendType" SG_ 961 LH1_Welligkeit 7;
BA_ "GenSigSendType" SG_ 961 LH1_Unterst_Leist 7;
BA_ "GenSigSendType" SG_ 961 LH1_Unterspannung 7;
BA_ "GenSigSendType" SG_ 961 LH1_Uebertemperatur 7;
BA_ "GenSigSendType" SG_ 961 LH1_Ueberspannung 7;
BA_ "GenSigSendType" SG_ 961 LH1_Textbits 7;
BA_ "GenSigSendType" SG_ 961 LH1_Sleep_Indication 7;
BA_ "GenSigSendType" SG_ 961 LH1_Sensorik 7;
BA_ "GenSigSendType" SG_ 961 LH1_NL_Res 7;
BA_ "GenSigSendType" SG_ 961 LH1_Motor 7;
BA_ "GenSigSendType" SG_ 961 LH1_Lastinfo 7;
BA_ "GenSigSendType" SG_ 961 LH1_KD_Fehler 7;
BA_ "GenSigSendType" SG_ 961 LH1_gueltig_Wellig 7;
BA_ "GenSigSendType" SG_ 961 LH1_gueltig_Batt_ab 7;
BA_ "GenSigSendType" SG_ 961 LH1_Fehlerlampe 7;
BA_ "GenSigSendType" SG_ 961 LH1_Fehler_Lastinfo 7;
BA_ "GenSigSendType" SG_ 961 LH1_ECU_intern 7;
BA_ "GenSigSendType" SG_ 961 LH1_Diag 7;
BA_ "GenSigSendType" SG_ 961 LH1_CAN_Schnittstelle 7;
BA_ "GenSigSendType" SG_ 961 LH1_Batterie_ab 7;
BA_ "GenSigSendType" SG_ 961 LH1_Akustiksig 7;
BA_ "GenSigSendType" SG_ 1569 KO1_WFS_Schluessel 7;
BA_ "GenSigSendType" SG_ 1569 KO1_WaschWasser 7;
BA_ "GenSigSendType" SG_ 1569 KO1_Tankwarnung 7;
BA_ "GenSigSendType" SG_ 1569 KO1_Tankwarnlampe 7;
BA_ "GenSigSendType" SG_ 1569 KO1_Tankstop 7;
BA_ "GenSigSendType" SG_ 1569 KO1_Tankinhalt 7;
BA_ "GenSigSendType" SG_ 1569 KO1_Standzeit_Fehler 7;
BA_ "GenSigSendType" SG_ 1569 KO1_Standzeit 7;
BA_ "GenSigSendType" SG_ 1569 KO1_Handbremse 7;
BA_ "SignalRepeatActivation" SG_ 1501 IL1_Kl_30G 5;
BA_ "GenSigSendType" SG_ 1501 IL1_Kl_30G 3;
BA_ "SignalRepeatActivation" SG_ 1501 IL1_Funktionsanzeige 5;
BA_ "GenSigSendType" SG_ 1501 IL1_Funktionsanzeige 3;
BA_ "SignalRepeatActivation" SG_ 1501 IL1_Bel_Umfeld 5;
BA_ "GenSigSendType" SG_ 1501 IL1_Bel_Umfeld 3;
BA_ "SignalRepeatActivation" SG_ 1501 IL1_Bel_Innengriff_Tuer 5;
BA_ "GenSigSendType" SG_ 1501 IL1_Bel_Innengriff_Tuer 3;
BA_ "SignalRepeatActivation" SG_ 1501 IL1_Bel_HR_Ausstieg 5;
BA_ "GenSigSendType" SG_ 1501 IL1_Bel_HR_Ausstieg 3;
BA_ "SignalRepeatActivation" SG_ 1501 IL1_Bel_HL_Ausstieg 5;
BA_ "GenSigSendType" SG_ 1501 IL1_Bel_HL_Ausstieg 3;
BA_ "SignalRepeatActivation" SG_ 1501 IL1_Bel_Fussraum 5;
BA_ "GenSigSendType" SG_ 1501 IL1_Bel_Fussraum 3;
BA_ "SignalRepeatActivation" SG_ 1501 IL1_Bel_FT_Ausstieg 5;
BA_ "GenSigSendType" SG_ 1501 IL1_Bel_FT_Ausstieg 3;
BA_ "SignalRepeatActivation" SG_ 1501 IL1_Bel_BT_Ausstieg 5;
BA_ "GenSigSendType" SG_ 1501 IL1_Bel_BT_Ausstieg 3;
BA_ "GenSigSendType" SG_ 859 GWM_Motordrehzahl 7;
BA_ "GenSigSendType" SG_ 859 GWM_Kuppl_Schalter 3;
BA_ "GenSigSendType" SG_ 859 GWM_KuehlmittelTemp 7;
BA_ "GenSigSendType" SG_ 859 GWM_Komp_Leist_red 3;
BA_ "GenSigSendType" SG_ 859 GWM_KLuefter 7;
BA_ "GenSigSendType" SG_ 859 GWM_Klimaabschaltung 3;
BA_ "GenSigSendType" SG_ 859 GWM_Kennfeldkuehlung 3;
BA_ "GenSigSendType" SG_ 859 GWM_Heissl_Vorwarn 3;
BA_ "GenSigSendType" SG_ 859 GWM_GRA_Status 3;
BA_ "GenSigSendType" SG_ 859 GWM_Fehl_KmittelTemp 3;
BA_ "GenSigSendType" SG_ 859 GWM_Bremstest_Schalter 3;
BA_ "GenSigSendType" SG_ 859 GWM_Bremslicht_Schalter 3;
BA_ "GenSigSendType" SG_ 859 GWM_Anl_Freigabe 3;
BA_ "GenSigSendType" SG_ 859 GWM_Anl_Ausspuren 3;
BA_ "GenSigSendType" SG_ 859 GWM_Alt_5_Motor 3;
BA_ "GenSigSendType" SG_ 859 GWM_Alt_2_Motor 3;
BA_ "GenSigSendType" SG_ 859 GWM_Alt_1_Motor 3;
BA_ "GenSigSendType" SG_ 1319 GWK_Umfang_Reifen 7;
BA_ "GenSigSendType" SG_ 1319 GWK_AussenTemp_ungefiltert 7;
BA_ "GenSigSendType" SG_ 1319 GWK_AussenTemp_gefiltert 7;
BA_ "GenSigSendType" SG_ 1319 GWK_AussenTemp_Fehler 7;
BA_ "GenSigSendType" SG_ 1319 GWK_Alt_3_Kombi 7;
BA_ "GenSigSendType" SG_ 1319 GWK_Alt_2_Kombi 7;
BA_ "GenSigSendType" SG_ 857 GWB_Wegimpulse_Fehler 7;
BA_ "GenSigSendType" SG_ 857 GWB_Wegimpulse 7;
BA_ "GenSigSendType" SG_ 857 GWB_Wegimpuls_Status 7;
BA_ "GenSigSendType" SG_ 857 GWB_Shift_Lock 7;
BA_ "GenSigSendType" SG_ 857 GWB_Schlechtweg_Fehler 7;
BA_ "GenSigSendType" SG_ 857 GWB_Schlechtweg 7;
BA_ "GenSigSendType" SG_ 857 GWB_Schaltvorgang 7;
BA_ "GenSigSendType" SG_ 857 GWB_res_Richtung 7;
BA_ "GenSigSendType" SG_ 857 GWB_Info_Waehlhebel 7;
BA_ "GenSigSendType" SG_ 857 GWB_Impulszahl 7;
BA_ "GenSigSendType" SG_ 857 GWB_Geschw_Ersatz 7;
BA_ "GenSigSendType" SG_ 857 GWB_FzgGeschw_Quelle 7;
BA_ "GenSigSendType" SG_ 857 GWB_FzgGeschw 7;
BA_ "GenSigSendType" SG_ 857 GWB_Alt_FzgGeschw 7;
BA_ "GenSigSendType" SG_ 857 GWB_Alt_2_Getriebe 7;
BA_ "GenSigSendType" SG_ 857 GWB_Alt_2_Bremse 7;
BA_ "GenSigSendType" SG_ 857 GWB_Alt_1_Getriebe 7;
BA_ "GenSigSendType" SG_ 857 GWB_Alt_1_Bremse 7;
BA_ "GenSigSendType" SG_ 857 GWB_ABS_Bremsung 7;
BA_ "GenSigSendType" SG_ 649 GR2_Zaehler 7;
BA_ "GenSigSendType" SG_ 649 GR2_Typ_Hauptschalter 7;
BA_ "GenSigSendType" SG_ 649 GR2_Tip_Verzoegern 7;
BA_ "GenSigSendType" SG_ 649 GR2_Tip_Up 7;
BA_ "GenSigSendType" SG_ 649 GR2_Tip_Fehler 7;
BA_ "GenSigSendType" SG_ 649 GR2_Tip_Down 7;
BA_ "GenSigSendType" SG_ 649 GR2_Tip_Beschleunigen 7;
BA_ "GenSigSendType" SG_ 649 GR2_Tip_aus_GRA 7;
BA_ "GenSigSendType" SG_ 649 GR2_Sendercodierung 7;
BA_ "GenSigSendType" SG_ 649 GR2_Kodierinfo 7;
BA_ "GenSigSendType" SG_ 649 GR2_Hauptschalter_ein 7;
BA_ "GenSigSendType" SG_ 649 GR2_Checksumme 7;
BA_ "GenSigSendType" SG_ 649 GR2_Bedienteil_Fehler 7;
BA_ "GenSigSendType" SG_ 1619 GW3_Sprachvariante 7;
BA_ "GenSigSendType" SG_ 1619 GW3_Motortyp 7;
BA_ "GenSigSendType" SG_ 1619 GW3_Laendervariante 7;
BA_ "GenSigSendType" SG_ 1631 FI1_MUX 7;
BA_ "GenSigSendType" SG_ 1631 FI1_Data7 7;
BA_ "GenSigSendType" SG_ 1631 FI1_Data6 7;
BA_ "GenSigSendType" SG_ 1631 FI1_Data5 7;
BA_ "GenSigSendType" SG_ 1631 FI1_Data4 7;
BA_ "GenSigSendType" SG_ 1631 FI1_Data3 7;
BA_ "GenSigSendType" SG_ 1631 FI1_Data2 7;
BA_ "GenSigSendType" SG_ 1631 FI1_Data1 7;
BA_ "GenSigSendType" SG_ 1550 EH1_Profil 3;
BA_ "GenSigSendType" SG_ 1550 EH1_Einh_Vol 3;
BA_ "GenSigSendType" SG_ 1550 EH1_Einh_Verbr 3;
BA_ "GenSigSendType" SG_ 1550 EH1_Einh_Temp 3;
BA_ "GenSigSendType" SG_ 1550 EH1_Einh_Strck 3;
BA_ "GenSigSendType" SG_ 1550 EH1_Einh_Druck 3;
BA_ "GenSigSendType" SG_ 1583 DY1_Reset 3;
BA_ "GenSigSendType" SG_ 1583 DY1_Global_Reset 3;
BA_ "GenSigSendType" SG_ 1583 DY1_Display_OK 3;
BA_ "GenSigSendType" SG_ 1583 DY1_Bereich3 3;
BA_ "GenSigSendType" SG_ 1583 DY1_Bereich2 3;
BA_ "GenSigSendType" SG_ 1583 DY1_Bereich1 3;
BA_ "GenSigSendType" SG_ 1589 DI1_Schalter_def 3;
BA_ "GenSigSendType" SG_ 1589 DI1_Schalter 3;
BA_ "GenSigSendType" SG_ 1589 DI1_Display_def 3;
BA_ "GenSigSendType" SG_ 1589 DI1_Display 3;
BA_ "GenSigSendType" SG_ 1629 DN1_Verlernzaehler 7;
BA_ "GenSigSendType" SG_ 1629 DN1_Tag 7;
BA_ "GenSigSendType" SG_ 1629 DN1_Stunde 7;
BA_ "GenSigSendType" SG_ 1629 DN1_Sekunde 7;
BA_ "GenSigSendType" SG_ 1629 DN1_Monat 7;
BA_ "GenSigSendType" SG_ 1629 DN1_Minute 7;
BA_ "GenSigSendType" SG_ 1629 DN1_KM_Stand 7;
BA_ "GenSigSendType" SG_ 1629 DN1_Jahr 7;
BA_ "GenSigSendType" SG_ 1629 DN1_alt_Zeit 7;
BA_ "GenSigSendType" SG_ 1629 DN1_alt_Kilometerstand 7;
BA_ "GenSigSendType" SG_ 995 CL2_Vorgabe_KWTemp 3;
BA_ "GenSigSendType" SG_ 995 CL2_Umluft_Taste 3;
BA_ "GenSigSendType" SG_ 995 CL2_Sonne_rechts 7;
BA_ "GenSigSendType" SG_ 995 CL2_Sonne_links 7;
BA_ "GenSigSendType" SG_ 995 CL2_SL_LED 3;
BA_ "GenSigSendType" SG_ 995 CL2_SitzH_rechts 7;
BA_ "GenSigSendType" SG_ 995 CL2_SitzH_links 7;
BA_ "GenSigSendType" SG_ 995 CL2_SH 3;
BA_ "GenSigSendType" SG_ 995 CL2_InnenTemp 7;
BA_ "GenSigSendType" SG_ 993 CL1_Zuheizer 3;
BA_ "GenSigSendType" SG_ 993 CL1_Temp_in_F 7;
BA_ "GenSigSendType" SG_ 993 CL1_Strg_Kluefter 7;
BA_ "GenSigSendType" SG_ 993 CL1_Last_Kompressor 7;
BA_ "GenSigSendType" SG_ 993 CL1_Kompressormoment_alt 3;
BA_ "GenSigSendType" SG_ 993 CL1_Kompressor 3;
BA_ "GenSigSendType" SG_ 993 CL1_KD_Fehler 7;
BA_ "GenSigSendType" SG_ 993 CL1_Kaeltemitteldruck_alt 3;
BA_ "GenSigSendType" SG_ 993 CL1_KaeltemittelDruck 7;
BA_ "GenSigSendType" SG_ 993 CL1_HzgHeckscheibe 3;
BA_ "GenSigSendType" SG_ 993 CL1_HzgFrontscheibe 3;
BA_ "GenSigSendType" SG_ 993 CL1_Heizung_aus 3;
BA_ "GenSigSendType" SG_ 993 CL1_Geblaeselast 7;
BA_ "GenSigSendType" SG_ 993 CL1_Drehzahlanhebung 3;
BA_ "GenSigSendType" SG_ 993 CL1_AussenTemp 7;
BA_ "GenSigSendType" SG_ 1708 Update_Indikator_12 3;
BA_ "GenSigSendType" SG_ 1708 OpCode_12 3;
BA_ "GenSigSendType" SG_ 1708 Module_ID_12 3;
BA_ "GenSigSendType" SG_ 1708 Funktions_ID_12 3;
BA_ "GenSigSendType" SG_ 1708 Data_Byte_5_12 3;
BA_ "GenSigSendType" SG_ 1708 Data_Byte_4_12 3;
BA_ "GenSigSendType" SG_ 1708 Data_Byte_3_12 3;
BA_ "GenSigSendType" SG_ 1708 Data_Byte_2_12 3;
BA_ "GenSigSendType" SG_ 1708 Data_Byte_1_12 3;
BA_ "GenSigSendType" SG_ 1708 Controller_ID_12 3;
BA_ "GenSigSendType" SG_ 1762 Update_Indikator_32 3;
BA_ "GenSigSendType" SG_ 1762 OpCode_32 3;
BA_ "GenSigSendType" SG_ 1762 Module_ID_32 3;
BA_ "GenSigSendType" SG_ 1762 Funktions_ID_32 3;
BA_ "GenSigSendType" SG_ 1762 Data_Byte_5_32 3;
BA_ "GenSigSendType" SG_ 1762 Data_Byte_4_32 3;
BA_ "GenSigSendType" SG_ 1762 Data_Byte_3_32 3;
BA_ "GenSigSendType" SG_ 1762 Data_Byte_2_32 3;
BA_ "GenSigSendType" SG_ 1762 Data_Byte_1_32 3;
BA_ "GenSigSendType" SG_ 1762 Controller_ID_32 3;
BA_ "GenSigSendType" SG_ 1761 Update_Indikator_31 3;
BA_ "GenSigSendType" SG_ 1761 OpCode_31 3;
BA_ "GenSigSendType" SG_ 1761 Module_ID_31 3;
BA_ "GenSigSendType" SG_ 1761 Funktions_ID_31 3;
BA_ "GenSigSendType" SG_ 1761 Data_Byte_5_31 3;
BA_ "GenSigSendType" SG_ 1761 Data_Byte_4_31 3;
BA_ "GenSigSendType" SG_ 1761 Data_Byte_3_31 3;
BA_ "GenSigSendType" SG_ 1761 Data_Byte_2_31 3;
BA_ "GenSigSendType" SG_ 1761 Data_Byte_1_31 3;
BA_ "GenSigSendType" SG_ 1761 Controller_ID_31 3;
BA_ "GenSigSendType" SG_ 1760 Update_Indikator_30 3;
BA_ "GenSigSendType" SG_ 1760 OpCode_30 3;
BA_ "GenSigSendType" SG_ 1760 Module_ID_30 3;
BA_ "GenSigSendType" SG_ 1760 Funktions_ID_30 3;
BA_ "GenSigSendType" SG_ 1760 Data_Byte_5_30 3;
BA_ "GenSigSendType" SG_ 1760 Data_Byte_4_30 3;
BA_ "GenSigSendType" SG_ 1760 Data_Byte_3_30 3;
BA_ "GenSigSendType" SG_ 1760 Data_Byte_2_30 3;
BA_ "GenSigSendType" SG_ 1760 Data_Byte_1_30 3;
BA_ "GenSigSendType" SG_ 1760 Controller_ID_30 3;
BA_ "GenSigSendType" SG_ 1698 Update_Indikator_2 3;
BA_ "GenSigSendType" SG_ 1698 OpCode_2 3;
BA_ "GenSigSendType" SG_ 1698 Module_ID_2 3;
BA_ "GenSigSendType" SG_ 1698 Funktions_ID_2 3;
BA_ "GenSigSendType" SG_ 1698 Data_Byte_5_2 3;
BA_ "GenSigSendType" SG_ 1698 Data_Byte_4_2 3;
BA_ "GenSigSendType" SG_ 1698 Data_Byte_3_2 3;
BA_ "GenSigSendType" SG_ 1698 Data_Byte_2_2 3;
BA_ "GenSigSendType" SG_ 1698 Data_Byte_1_2 3;
BA_ "GenSigSendType" SG_ 1698 Controller_ID_2 3;
BA_ "GenSigSendType" SG_ 1704 Update_Indikator_8 3;
BA_ "GenSigSendType" SG_ 1704 OpCode_8 3;
BA_ "GenSigSendType" SG_ 1704 Module_ID_8 3;
BA_ "GenSigSendType" SG_ 1704 Funktions_ID_8 3;
BA_ "GenSigSendType" SG_ 1704 Data_Byte_5_8 3;
BA_ "GenSigSendType" SG_ 1704 Data_Byte_4_8 3;
BA_ "GenSigSendType" SG_ 1704 Data_Byte_3_8 3;
BA_ "GenSigSendType" SG_ 1704 Data_Byte_2_8 3;
BA_ "GenSigSendType" SG_ 1704 Data_Byte_1_8 3;
BA_ "GenSigSendType" SG_ 1704 Controller_ID_8 3;
BA_ "GenSigSendType" SG_ 1710 Update_Indikator_14 3;
BA_ "GenSigSendType" SG_ 1710 OpCode_14 3;
BA_ "GenSigSendType" SG_ 1710 Module_ID_14 3;
BA_ "GenSigSendType" SG_ 1710 Funktions_ID_14 3;
BA_ "GenSigSendType" SG_ 1710 Data_Byte_5_14 3;
BA_ "GenSigSendType" SG_ 1710 Data_Byte_4_14 3;
BA_ "GenSigSendType" SG_ 1710 Data_Byte_3_14 3;
BA_ "GenSigSendType" SG_ 1710 Data_Byte_2_14 3;
BA_ "GenSigSendType" SG_ 1710 Data_Byte_1_14 3;
BA_ "GenSigSendType" SG_ 1710 Controller_ID_14 3;
BA_ "GenSigSendType" SG_ 1702 Update_Indikator_6 3;
BA_ "GenSigSendType" SG_ 1702 OpCode_6 3;
BA_ "GenSigSendType" SG_ 1702 Module_ID_6 3;
BA_ "GenSigSendType" SG_ 1702 Funktions_ID_6 3;
BA_ "GenSigSendType" SG_ 1702 Data_Byte_5_6 3;
BA_ "GenSigSendType" SG_ 1702 Data_Byte_4_6 3;
BA_ "GenSigSendType" SG_ 1702 Data_Byte_3_6 3;
BA_ "GenSigSendType" SG_ 1702 Data_Byte_2_6 3;
BA_ "GenSigSendType" SG_ 1702 Data_Byte_1_6 3;
BA_ "GenSigSendType" SG_ 1702 Controller_ID_6 3;
BA_ "GenSigSendType" SG_ 1785 Update_Indikator_24 3;
BA_ "GenSigSendType" SG_ 1785 OpCode_24 3;
BA_ "GenSigSendType" SG_ 1785 Module_ID_24 3;
BA_ "GenSigSendType" SG_ 1785 Funktions_ID_24 3;
BA_ "GenSigSendType" SG_ 1785 Data_Byte_5_24 3;
BA_ "GenSigSendType" SG_ 1785 Data_Byte_4_24 3;
BA_ "GenSigSendType" SG_ 1785 Data_Byte_3_24 3;
BA_ "GenSigSendType" SG_ 1785 Data_Byte_2_24 3;
BA_ "GenSigSendType" SG_ 1785 Data_Byte_1_24 3;
BA_ "GenSigSendType" SG_ 1785 Controller_ID_24 3;
BA_ "GenSigSendType" SG_ 1787 Update_Indikator_26 3;
BA_ "GenSigSendType" SG_ 1787 OpCode_26 3;
BA_ "GenSigSendType" SG_ 1787 Module_ID_26 3;
BA_ "GenSigSendType" SG_ 1787 Funktions_ID_26 3;
BA_ "GenSigSendType" SG_ 1787 Data_Byte_5_26 3;
BA_ "GenSigSendType" SG_ 1787 Data_Byte_4_26 3;
BA_ "GenSigSendType" SG_ 1787 Data_Byte_3_26 3;
BA_ "GenSigSendType" SG_ 1787 Data_Byte_2_26 3;
BA_ "GenSigSendType" SG_ 1787 Data_Byte_1_26 3;
BA_ "GenSigSendType" SG_ 1787 Controller_ID_26 3;
BA_ "GenSigSendType" SG_ 1781 Update_Indikator_20 3;
BA_ "GenSigSendType" SG_ 1781 OpCode_20 3;
BA_ "GenSigSendType" SG_ 1781 Module_ID_20 3;
BA_ "GenSigSendType" SG_ 1781 Funktions_ID_20 3;
BA_ "GenSigSendType" SG_ 1781 Data_Byte_5_20 3;
BA_ "GenSigSendType" SG_ 1781 Data_Byte_4_20 3;
BA_ "GenSigSendType" SG_ 1781 Data_Byte_3_20 3;
BA_ "GenSigSendType" SG_ 1781 Data_Byte_2_20 3;
BA_ "GenSigSendType" SG_ 1781 Data_Byte_1_20 3;
BA_ "GenSigSendType" SG_ 1781 Controller_ID_20 3;
BA_ "GenSigSendType" SG_ 1782 Update_Indikator_21 3;
BA_ "GenSigSendType" SG_ 1782 OpCode_21 3;
BA_ "GenSigSendType" SG_ 1782 Module_ID_21 3;
BA_ "GenSigSendType" SG_ 1782 Funktions_ID_21 3;
BA_ "GenSigSendType" SG_ 1782 Data_Byte_5_21 3;
BA_ "GenSigSendType" SG_ 1782 Data_Byte_4_21 3;
BA_ "GenSigSendType" SG_ 1782 Data_Byte_3_21 3;
BA_ "GenSigSendType" SG_ 1782 Data_Byte_2_21 3;
BA_ "GenSigSendType" SG_ 1782 Data_Byte_1_21 3;
BA_ "GenSigSendType" SG_ 1782 Controller_ID_21 3;
BA_ "GenSigSendType" SG_ 1783 Update_Indikator_22 3;
BA_ "GenSigSendType" SG_ 1783 OpCode_22 3;
BA_ "GenSigSendType" SG_ 1783 Module_ID_22 3;
BA_ "GenSigSendType" SG_ 1783 Funktions_ID_22 3;
BA_ "GenSigSendType" SG_ 1783 Data_Byte_5_22 3;
BA_ "GenSigSendType" SG_ 1783 Data_Byte_4_22 3;
BA_ "GenSigSendType" SG_ 1783 Data_Byte_3_22 3;
BA_ "GenSigSendType" SG_ 1783 Data_Byte_2_22 3;
BA_ "GenSigSendType" SG_ 1783 Data_Byte_1_22 3;
BA_ "GenSigSendType" SG_ 1783 Controller_ID_22 3;
BA_ "GenSigSendType" SG_ 1780 Update_Indikator_19 3;
BA_ "GenSigSendType" SG_ 1780 OpCode_19 3;
BA_ "GenSigSendType" SG_ 1780 Module_ID_19 3;
BA_ "GenSigSendType" SG_ 1780 Funktions_ID_19 3;
BA_ "GenSigSendType" SG_ 1780 Data_Byte_5_19 3;
BA_ "GenSigSendType" SG_ 1780 Data_Byte_4_19 3;
BA_ "GenSigSendType" SG_ 1780 Data_Byte_3_19 3;
BA_ "GenSigSendType" SG_ 1780 Data_Byte_2_19 3;
BA_ "GenSigSendType" SG_ 1780 Data_Byte_1_19 3;
BA_ "GenSigSendType" SG_ 1780 Controller_ID_19 3;
BA_ "GenSigSendType" SG_ 1697 Update_Indikator_1 3;
BA_ "GenSigSendType" SG_ 1697 OpCode_1 3;
BA_ "GenSigSendType" SG_ 1697 Module_ID_1 3;
BA_ "GenSigSendType" SG_ 1697 Funktions_ID_1 3;
BA_ "GenSigSendType" SG_ 1697 Data_Byte_5_1 3;
BA_ "GenSigSendType" SG_ 1697 Data_Byte_4_1 3;
BA_ "GenSigSendType" SG_ 1697 Data_Byte_3_1 3;
BA_ "GenSigSendType" SG_ 1697 Data_Byte_2_1 3;
BA_ "GenSigSendType" SG_ 1697 Data_Byte_1_1 3;
BA_ "GenSigSendType" SG_ 1697 Controller_ID_1 3;
BA_ "GenSigSendType" SG_ 1703 Update_Indikator_7 3;
BA_ "GenSigSendType" SG_ 1703 OpCode_7 3;
BA_ "GenSigSendType" SG_ 1703 Module_ID_7 3;
BA_ "GenSigSendType" SG_ 1703 Funktions_ID_7 3;
BA_ "GenSigSendType" SG_ 1703 Data_Byte_5_7 3;
BA_ "GenSigSendType" SG_ 1703 Data_Byte_4_7 3;
BA_ "GenSigSendType" SG_ 1703 Data_Byte_3_7 3;
BA_ "GenSigSendType" SG_ 1703 Data_Byte_2_7 3;
BA_ "GenSigSendType" SG_ 1703 Data_Byte_1_7 3;
BA_ "GenSigSendType" SG_ 1703 Controller_ID_7 3;
BA_ "GenSigSendType" SG_ 1705 Update_Indikator_9 3;
BA_ "GenSigSendType" SG_ 1705 OpCode_9 3;
BA_ "GenSigSendType" SG_ 1705 Module_ID_9 3;
BA_ "GenSigSendType" SG_ 1705 Funktions_ID_9 3;
BA_ "GenSigSendType" SG_ 1705 Data_Byte_5_9 3;
BA_ "GenSigSendType" SG_ 1705 Data_Byte_4_9 3;
BA_ "GenSigSendType" SG_ 1705 Data_Byte_3_9 3;
BA_ "GenSigSendType" SG_ 1705 Data_Byte_2_9 3;
BA_ "GenSigSendType" SG_ 1705 Data_Byte_1_9 3;
BA_ "GenSigSendType" SG_ 1705 Controller_ID_9 3;
BA_ "GenSigSendType" SG_ 1696 Update_Indikator_0 3;
BA_ "GenSigSendType" SG_ 1696 OpCode_0 3;
BA_ "GenSigSendType" SG_ 1696 Module_ID_0 3;
BA_ "GenSigSendType" SG_ 1696 Funktions_ID_0 3;
BA_ "GenSigSendType" SG_ 1696 Data_Byte_5_0 3;
BA_ "GenSigSendType" SG_ 1696 Data_Byte_4_0 3;
BA_ "GenSigSendType" SG_ 1696 Data_Byte_3_0 3;
BA_ "GenSigSendType" SG_ 1696 Data_Byte_2_0 3;
BA_ "GenSigSendType" SG_ 1696 Data_Byte_1_0 3;
BA_ "GenSigSendType" SG_ 1696 Controller_ID_0 3;
BA_ "GenSigSendType" SG_ 1701 Update_Indikator_5 3;
BA_ "GenSigSendType" SG_ 1701 OpCode_5 3;
BA_ "GenSigSendType" SG_ 1701 Module_ID_5 3;
BA_ "GenSigSendType" SG_ 1701 Funktions_ID_5 3;
BA_ "GenSigSendType" SG_ 1701 Data_Byte_5_5 3;
BA_ "GenSigSendType" SG_ 1701 Data_Byte_4_5 3;
BA_ "GenSigSendType" SG_ 1701 Data_Byte_3_5 3;
BA_ "GenSigSendType" SG_ 1701 Data_Byte_2_5 3;
BA_ "GenSigSendType" SG_ 1701 Data_Byte_1_5 3;
BA_ "GenSigSendType" SG_ 1701 Controller_ID_5 3;
BA_ "GenSigSendType" SG_ 1136 BSK_Unterspannung 7;
BA_ "GenSigSendType" SG_ 1136 BSK_Ruecks_HR_verriegelt 7;
BA_ "GenSigSendType" SG_ 1136 BSK_Ruecks_HL_verriegelt 7;
BA_ "GenSigSendType" SG_ 1136 BSK_Rueckfahrlicht 7;
BA_ "GenSigSendType" SG_ 1136 BSK_NSL_LED_Pfad 7;
BA_ "GenSigSendType" SG_ 1136 BSK_MH_geoeffnet 7;
BA_ "GenSigSendType" SG_ 1136 BSK_Ladekontrollampe 7;
BA_ "GenSigSendType" SG_ 1136 BSK_HR_geoeffnet 7;
BA_ "GenSigSendType" SG_ 1136 BSK_HL_geoeffnet 7;
BA_ "GenSigSendType" SG_ 1136 BSK_HD_Vorraste 7;
BA_ "GenSigSendType" SG_ 1136 BSK_HD_Hauptraste 7;
BA_ "GenSigSendType" SG_ 1136 BSK_FT_geoeffnet 7;
BA_ "GenSigSendType" SG_ 1136 BSK_Display_def 7;
BA_ "GenSigSendType" SG_ 1136 BSK_Display 7;
BA_ "GenSigSendType" SG_ 1136 BSK_Def_Lampe 7;
BA_ "GenSigSendType" SG_ 1136 BSK_BT_geoeffnet 7;
BA_ "GenSigSendType" SG_ 1136 BSK_AFL_defekt 7;
BA_ "GenSigSendType" SG_ 1397 BS3_LED_Sitze 3;
BA_ "GenSigSendType" SG_ 1397 BS3_LED_Heckscheibe 3;
BA_ "GenSigSendType" SG_ 1397 BS3_LED_Frontscheibe 3;
BA_ "GenSigSendType" SG_ 1397 BS3_LED_Aussenspiegel 3;
BA_ "GenSigSendType" SG_ 1397 BS3_Leaving_Home 3;
BA_ "GenSigSendType" SG_ 1397 BS3_Ladekontrollampe 3;
BA_ "GenSigSendType" SG_ 1397 BS3_Klemme_X 3;
BA_ "GenSigSendType" SG_ 1397 BS3_Klemme_S 3;
BA_ "GenSigSendType" SG_ 1397 BS3_Klemme_P 3;
BA_ "GenSigSendType" SG_ 1397 BS3_Klemme_50 3;
BA_ "GenSigSendType" SG_ 1397 BS3_Klemme_15_Motorraum 3;
BA_ "GenSigSendType" SG_ 1397 BS3_Klemme_15 3;
BA_ "GenSigSendType" SG_ 1397 BS3_KD_Fehler 3;
BA_ "GenSigSendType" SG_ 1397 BS3_K_Luefter_ein 3;
BA_ "GenSigSendType" SG_ 1397 BS3_Haubenkontakt 3;
BA_ "GenSigSendType" SG_ 1397 BS3_Drehzahlanhebung 3;
BA_ "GenSigSendType" SG_ 1397 BS3_Coming_Home 3;
BA_ "GenSigSendType" SG_ 1397 BS3_Bordnetzbatt 3;
BA_ "GenSigSendType" SG_ 1397 BS3_2_Drehzahl 3;
BA_ "GenSigSendType" SG_ 1393 BS2_Warn_Zusatz 7;
BA_ "GenSigSendType" SG_ 1393 BS2_Warn_Infotainment 7;
BA_ "GenSigSendType" SG_ 1393 BS2_Verbr_ab_aktiv 7;
BA_ "GenSigSendType" SG_ 1393 BS2_U_BATT 7;
BA_ "GenSigSendType" SG_ 1393 BS2_Sitzheizung_aus 7;
BA_ "GenSigSendType" SG_ 1393 BS2_Lastman_aktiv 7;
BA_ "GenSigSendType" SG_ 1393 BS2_KlimaLeistRed 7;
BA_ "GenSigSendType" SG_ 1393 BS2_Klimaanlage_aus 7;
BA_ "GenSigSendType" SG_ 1393 BS2_Heckscheibe_aus 7;
BA_ "GenSigSendType" SG_ 1393 BS2_Frontscheibe_aus 7;
BA_ "GenSigSendType" SG_ 1393 BS2_Aussenspiegel_aus 7;
BA_ "GenSigSendType" SG_ 1393 BS2_aus_Sitzlueftung 7;
BA_ "GenSigSendType" SG_ 1393 BS2_aus_Sitzhzg_H 7;
BA_ "GenSigSendType" SG_ 1393 BS2_aus_PTC_Clima 7;
BA_ "GenSigSendType" SG_ 1393 BS2_aus_Lenkradheizung 7;
BA_ "GenSigSendType" SG_ 1393 BS2_aus_Infotainment 7;
BA_ "GenSigSendType" SG_ 1429 AG1_RFL_def 3;
BA_ "GenSigSendType" SG_ 1429 AG1_NSL_def 3;
BA_ "GenSigSendType" SG_ 1429 AG1_Licht_r_def 3;
BA_ "GenSigSendType" SG_ 1429 AG1_Licht_l_def 3;
BA_ "GenSigSendType" SG_ 1429 AG1_KD_Fehler 3;
BA_ "GenSigSendType" SG_ 1429 AG1_Blk_ein 3;
BA_ "GenSigSendType" SG_ 1429 AG1_Blinker_r_def 3;
BA_ "GenSigSendType" SG_ 1429 AG1_Blinker_l_def 3;
BA_ "GenSigSendType" SG_ 1429 AG1_BL_def 3;
BA_ "GenSigSendType" SG_ 1429 AG1_ANH_Erk 3;
BA_ "GenSigSendType" SG_ 337 AB1_Systemfehler 7;
BA_ "GenSigSendType" SG_ 337 AB1_Stellglied 7;
BA_ "GenSigSendType" SG_ 337 AB1_Rollover 3;
BA_ "GenSigSendType" SG_ 337 AB1_Pruefsumme 7;
BA_ "GenSigSendType" SG_ 337 AB1_MessageZaehler 7;
BA_ "GenSigSendType" SG_ 337 AB1_KD_Fehler 7;
BA_ "GenSigSendType" SG_ 337 AB1_HeckCrash 3;
BA_ "GenSigSendType" SG_ 337 AB1_FTGurtwarnung 7;
BA_ "GenSigSendType" SG_ 337 AB1_FTGurtschalter 7;
BA_ "GenSigSendType" SG_ 337 AB1_FrontCrash 3;
BA_ "GenSigSendType" SG_ 337 AB1_Diagnose 7;
BA_ "GenSigSendType" SG_ 337 AB1_CrashStaerke 3;
BA_ "GenSigSendType" SG_ 337 AB1_Crash_FT 3;
BA_ "GenSigSendType" SG_ 337 AB1_Crash_BT 3;
BA_ "GenSigSendType" SG_ 337 AB1_BTGurtwarnung 7;
BA_ "GenSigSendType" SG_ 337 AB1_BTGurtschalter 7;
BA_ "GenSigSendType" SG_ 337 AB1_AirbagLampe_ein 7;
BA_ "GenSigSendType" SG_ 337 AB1_Airbag_deaktiviert 7;
